VERSION ""

NS_ :

BS_:

BU_: ADCS_FD3 GW_FD2 BDCS CDCS GW_FD3 GW_FD4 GW_FD5 GW_FD6 GW_FD1 MCU FMCU EPS1 IDB1 ACU ICU TBOX IDB2 EPS2 RCU1 PDCU DDCU PLSD DLSD PDCS1 BTM GW_FD8 HNS2 HNS1 EMS BMS EDU RCU2

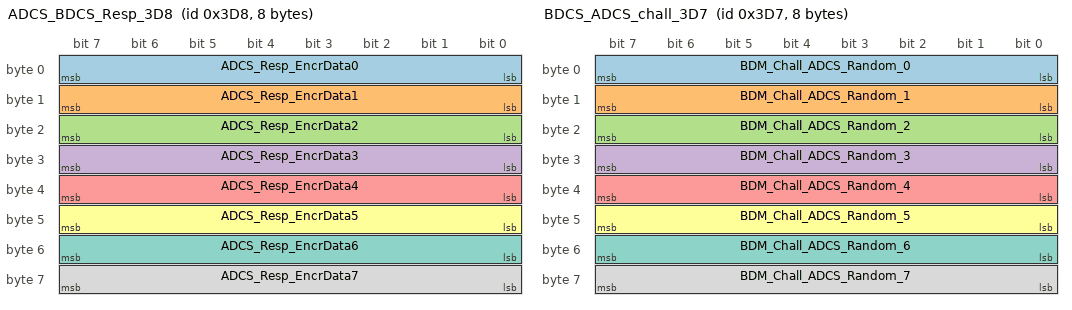
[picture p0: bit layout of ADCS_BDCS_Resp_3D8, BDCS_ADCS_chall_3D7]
BO_ 984 ADCS_BDCS_Resp_3D8: 8 ADCS_FD3
 SG_ ADCS_Resp_EncrData0 : 7|8@0+ (1,0) [0|255] "NoUnit" GW_FD2,BDCS
 SG_ ADCS_Resp_EncrData1 : 15|8@0+ (1,0) [0|255] "NoUnit" GW_FD2,BDCS
 SG_ ADCS_Resp_EncrData2 : 23|8@0+ (1,0) [0|255] "NoUnit" GW_FD2,BDCS
 SG_ ADCS_Resp_EncrData3 : 31|8@0+ (1,0) [0|255] "NoUnit" GW_FD2,BDCS
 SG_ ADCS_Resp_EncrData4 : 39|8@0+ (1,0) [0|255] "NoUnit" GW_FD2,BDCS
 SG_ ADCS_Resp_EncrData5 : 47|8@0+ (1,0) [0|255] "NoUnit" GW_FD2,BDCS
 SG_ ADCS_Resp_EncrData6 : 55|8@0+ (1,0) [0|255] "NoUnit" GW_FD2,BDCS
 SG_ ADCS_Resp_EncrData7 : 63|8@0+ (1,0) [0|255] "NoUnit" GW_FD2,BDCS

BO_ 983 BDCS_ADCS_chall_3D7: 8 BDCS
 SG_ BDM_Chall_ADCS_Random_0 : 7|8@0+ (1,0) [0|255] "NoUnit" ADCS_FD3
 SG_ BDM_Chall_ADCS_Random_1 : 15|8@0+ (1,0) [0|255] "NoUnit" ADCS_FD3
 SG_ BDM_Chall_ADCS_Random_2 : 23|8@0+ (1,0) [0|255] "NoUnit" ADCS_FD3
 SG_ BDM_Chall_ADCS_Random_3 : 31|8@0+ (1,0) [0|255] "NoUnit" ADCS_FD3
 SG_ BDM_Chall_ADCS_Random_4 : 39|8@0+ (1,0) [0|255] "NoUnit" ADCS_FD3
 SG_ BDM_Chall_ADCS_Random_5 : 47|8@0+ (1,0) [0|255] "NoUnit" ADCS_FD3
 SG_ BDM_Chall_ADCS_Random_6 : 55|8@0+ (1,0) [0|255] "NoUnit" ADCS_FD3
 SG_ BDM_Chall_ADCS_Random_7 : 63|8@0+ (1,0) [0|255] "NoUnit" ADCS_FD3

BO_ 515 CDCS_Fr15_203: 16 CDCS
 SG_ CDCS15_NNP_DriverStatus : 71|2@0+ (1,0) [0|3] "NoUnit" ADCS_FD3
 SG_ CDCS15_Storage_St : 72|1@0+ (1,0) [0|1] "NoUnit" ADCS_FD3
 SG_ CDCS15_USB_St : 73|1@0+ (1,0) [0|1] "NoUnit" ADCS_FD3
 SG_ CDCS15_UserSceneMode : 79|4@0+ (1,0) [0|15] "NoUnit" ADCS_FD3

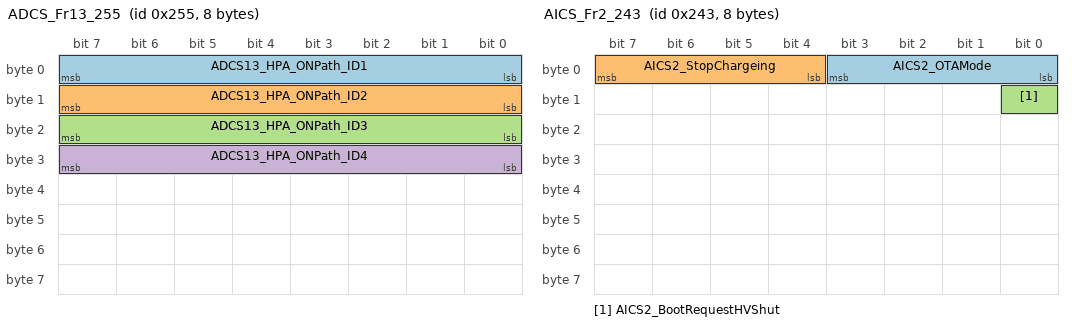
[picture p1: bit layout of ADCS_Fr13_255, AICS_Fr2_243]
BO_ 597 ADCS_Fr13_255: 8 ADCS_FD3
 SG_ ADCS13_HPA_ONPath_ID1 : 7|8@0+ (1,0) [0|255] "NoUnit" GW_FD3,GW_FD4,CDCS
 SG_ ADCS13_HPA_ONPath_ID2 : 15|8@0+ (1,0) [0|255] "NoUnit" GW_FD3,GW_FD4,CDCS
 SG_ ADCS13_HPA_ONPath_ID3 : 23|8@0+ (1,0) [0|255] "NoUnit" GW_FD3,GW_FD4,CDCS
 SG_ ADCS13_HPA_ONPath_ID4 : 31|8@0+ (1,0) [0|255] "NoUnit" GW_FD3,GW_FD4,CDCS

BO_ 579 AICS_Fr2_243: 8 GW_FD5
 SG_ AICS2_OTAMode : 3|4@0+ (1,0) [0|15] "NoUnit" ADCS_FD3
 SG_ AICS2_StopChargeing : 7|4@0+ (1,0) [0|15] "NoUnit" ADCS_FD3
 SG_ AICS2_BootRequestHVShut : 8|1@0+ (1,0) [0|1] "NoUnit" ADCS_FD3

BO_ 170 MCU_Fr01_0AA: 16 MCU
 SG_ MCU1_MotorSpeed : 23|16@0+ (0.5,-16000) [-16000|16000] "Rpm" ADCS_FD3
 SG_ MCU1_ControllerTorque : 39|16@0+ (0.05,-1024) [-1024|1024] "Nm" ADCS_FD3
 SG_ MCU1_AliveCounter : 51|4@0+ (1,0) [0|15] "NoUnit" ADCS_FD3
 SG_ MCU1_presentActivityFault : 71|8@0+ (1,0) [0|128] "NoUnit" ADCS_FD3
 SG_ MCU1_CurrentTorque : 78|15@0+ (0.05,-400) [-400|400] "Nm" ADCS_FD3
 SG_ MCU1_CurrentTorqueValid : 95|1@0+ (1,0) [0|1] "NoUnit" ADCS_FD3

BO_ 171 FMCU_Fr01_0AB: 16 FMCU
 SG_ FMCU1_MotorSpeed : 23|16@0+ (0.5,-16000) [-16000|16000] "Rpm" ADCS_FD3
 SG_ FMCU1_ControllerTorque : 39|16@0+ (0.05,-1024) [-1024|1024] "Nm" ADCS_FD3
 SG_ FMCU1_AliveCounter : 51|4@0+ (1,0) [0|15] "NoUnit" ADCS_FD3
 SG_ FMCU1_Checksum : 63|8@0+ (1,0) [0|255] "NoUnit" ADCS_FD3
 SG_ FMCU1_presentActivityFault : 71|8@0+ (1,0) [0|128] "NoUnit" ADCS_FD3
 SG_ FMCU1_CurrentTorque : 78|15@0+ (0.05,-400) [-400|400] "Nm" ADCS_FD3
 SG_ FMCU1_CurrentTorqueValid : 95|1@0+ (1,0) [0|1] "NoUnit" ADCS_FD3

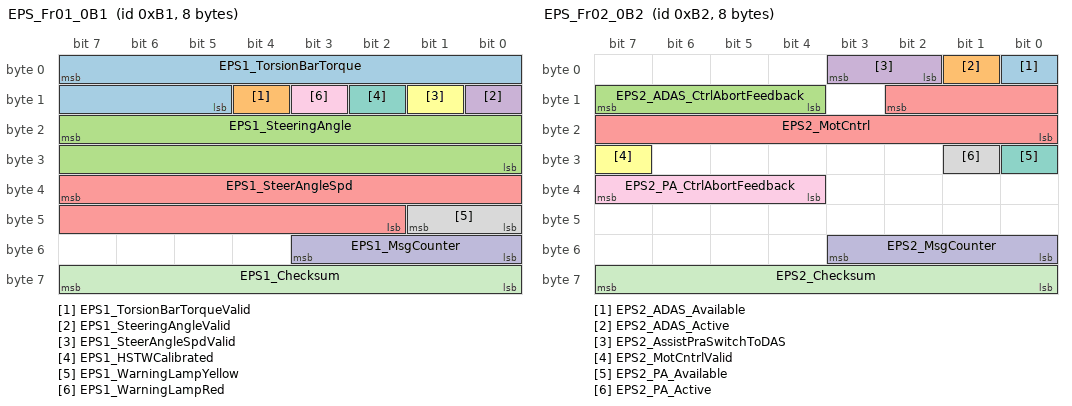
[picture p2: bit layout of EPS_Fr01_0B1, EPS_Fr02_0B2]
BO_ 177 EPS_Fr01_0B1: 8 EPS1
 SG_ EPS1_TorsionBarTorque : 7|11@0+ (0.01,-10.24) [-10.24|10.23] "Nm" ADCS_FD3
 SG_ EPS1_TorsionBarTorqueValid : 12|1@0+ (1,0) [0|1] "NoUnit" ADCS_FD3
 SG_ EPS1_SteeringAngle : 23|16@0+ (0.0345,-780) [-780|780.021] "degree" ADCS_FD3
 SG_ EPS1_SteeringAngleValid : 8|1@0+ (1,0) [0|1] "NoUnit" ADCS_FD3
 SG_ EPS1_SteerAngleSpd : 39|14@0+ (0.125,-1024) [-1024|1023.75] "deg/s" ADCS_FD3
 SG_ EPS1_SteerAngleSpdValid : 9|1@0+ (1,0) [0|1] "NoUnit" ADCS_FD3
 SG_ EPS1_HSTWCalibrated : 10|1@0+ (1,0) [0|1] "NoUnit" ADCS_FD3
 SG_ EPS1_WarningLampYellow : 41|2@0+ (1,0) [0|3] "NoUnit" ADCS_FD3
 SG_ EPS1_WarningLampRed : 11|1@0+ (1,0) [0|1] "NoUnit" ADCS_FD3
 SG_ EPS1_MsgCounter : 51|4@0+ (1,0) [0|15] "NoUnit" ADCS_FD3
 SG_ EPS1_Checksum : 63|8@0+ (1,0) [0|255] "NoUnit" ADCS_FD3

BO_ 178 EPS_Fr02_0B2: 8 EPS1
 SG_ EPS2_ADAS_Available : 0|1@0+ (1,0) [0|1] "NoUnit" ADCS_FD3
 SG_ EPS2_ADAS_Active : 1|1@0+ (1,0) [0|1] "NoUnit" ADCS_FD3
 SG_ EPS2_ADAS_CtrlAbortFeedback : 15|4@0+ (1,0) [0|15] "NoUnit" ADCS_FD3
 SG_ EPS2_AssistPraSwitchToDAS : 3|2@0+ (1,0) [0|3] "NoUnit" ADCS_FD3
 SG_ EPS2_MotCntrl : 10|11@0+ (0.01,-8) [-8|8] "Nm" ADCS_FD3
 SG_ EPS2_MotCntrlValid : 31|1@0+ (1,0) [0|1] "NoUnit" ADCS_FD3
 SG_ EPS2_PA_Available : 24|1@0+ (1,0) [0|1] "NoUnit" ADCS_FD3
 SG_ EPS2_PA_Active : 25|1@0+ (1,0) [0|1] "NoUnit" ADCS_FD3
 SG_ EPS2_PA_CtrlAbortFeedback : 39|4@0+ (1,0) [0|15] "NoUnit" ADCS_FD3
 SG_ EPS2_MsgCounter : 51|4@0+ (1,0) [0|15] "NoUnit" ADCS_FD3
 SG_ EPS2_Checksum : 63|8@0+ (1,0) [0|255] "NoUnit" ADCS_FD3

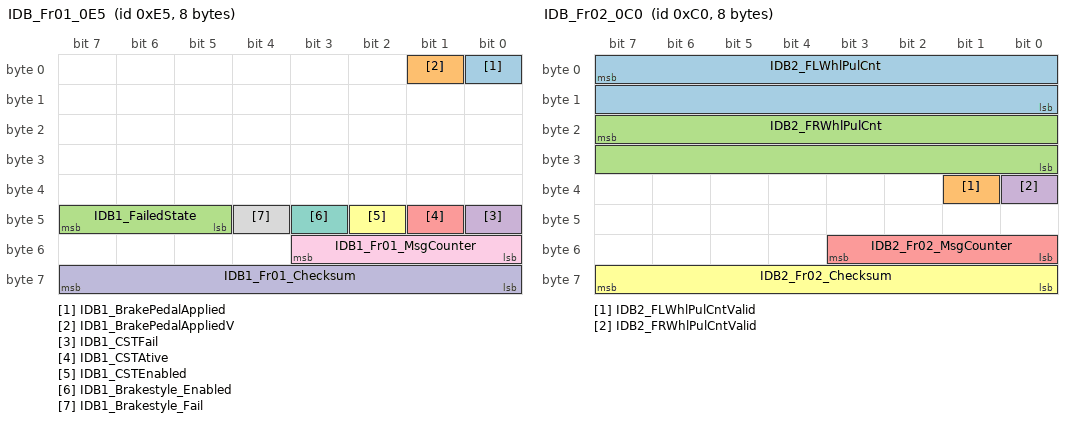
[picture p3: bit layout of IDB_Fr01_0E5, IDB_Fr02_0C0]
BO_ 229 IDB_Fr01_0E5: 8 IDB1
 SG_ IDB1_BrakePedalApplied : 0|1@0+ (1,0) [0|1] "NoUnit" ADCS_FD3
 SG_ IDB1_BrakePedalAppliedV : 1|1@0+ (1,0) [0|1] "NoUnit" ADCS_FD3
 SG_ IDB1_FailedState : 47|3@0+ (1,0) [0|7] "NoUnit" ADCS_FD3
 SG_ IDB1_CSTFail : 40|1@0+ (1,0) [0|1] "NoUnit" ADCS_FD3
 SG_ IDB1_CSTAtive : 41|1@0+ (1,0) [0|1] "NoUnit" ADCS_FD3
 SG_ IDB1_CSTEnabled : 42|1@0+ (1,0) [0|1] "NoUnit" ADCS_FD3
 SG_ IDB1_Brakestyle_Enabled : 43|1@0+ (1,0) [0|1] "NoUnit" ADCS_FD3
 SG_ IDB1_Brakestyle_Fail : 44|1@0+ (1,0) [0|1] "NoUnit" ADCS_FD3
 SG_ IDB1_Fr01_MsgCounter : 51|4@0+ (1,0) [0|15] "NoUnit" ADCS_FD3
 SG_ IDB1_Fr01_Checksum : 63|8@0+ (1,0) [0|255] "NoUnit" ADCS_FD3

BO_ 192 IDB_Fr02_0C0: 8 IDB1
 SG_ IDB2_FLWhlPulCnt : 7|16@0+ (0.5,0) [0|32767] "NoUnit" ADCS_FD3
 SG_ IDB2_FLWhlPulCntValid : 33|1@0+ (1,0) [0|1] "NoUnit" ADCS_FD3
 SG_ IDB2_FRWhlPulCnt : 23|16@0+ (0.5,0) [0|32767] "NoUnit" ADCS_FD3
 SG_ IDB2_FRWhlPulCntValid : 32|1@0+ (1,0) [0|1] "NoUnit" ADCS_FD3
 SG_ IDB2_Fr02_MsgCounter : 51|4@0+ (1,0) [0|15] "NoUnit" ADCS_FD3
 SG_ IDB2_Fr02_Checksum : 63|8@0+ (1,0) [0|255] "NoUnit" ADCS_FD3

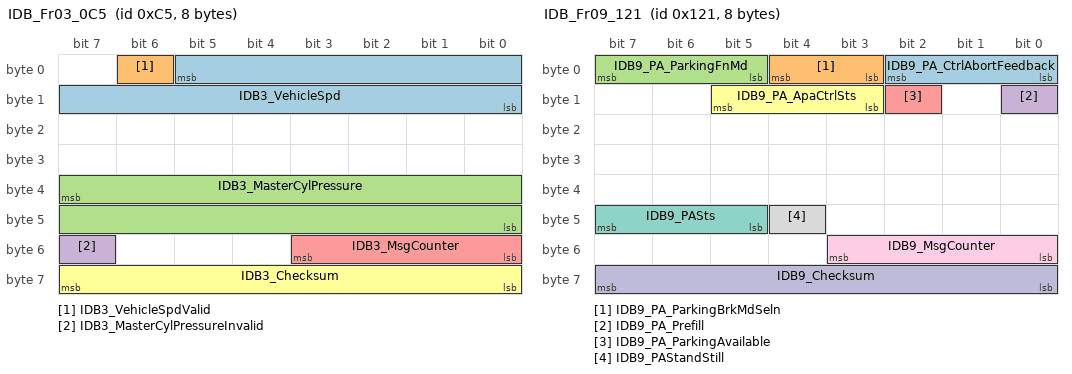
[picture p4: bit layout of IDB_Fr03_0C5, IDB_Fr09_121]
BO_ 197 IDB_Fr03_0C5: 8 IDB1
 SG_ IDB3_VehicleSpd : 5|14@0+ (0.03125,0) [0|511.9375] "km/h" ADCS_FD3
 SG_ IDB3_VehicleSpdValid : 6|1@0+ (1,0) [0|1] "NoUnit" ADCS_FD3
 SG_ IDB3_MasterCylPressure : 39|16@0+ (0.01,-30) [0|280] "bar" ADCS_FD3
 SG_ IDB3_MasterCylPressureInvalid : 55|1@0+ (1,0) [0|1] "NoUnit" ADCS_FD3
 SG_ IDB3_MsgCounter : 51|4@0+ (1,0) [0|15] "NoUnit" ADCS_FD3
 SG_ IDB3_Checksum : 63|8@0+ (1,0) [0|255] "NoUnit" ADCS_FD3

BO_ 199 IDB_Fr04_0C7: 32 IDB1
 SG_ IDB4_FLWhlVelocity : 7|14@0+ (0.03125,0) [0|511.9375] "km/h" ADCS_FD3
 SG_ IDB4_FLWhlVelocityValid : 9|1@0+ (1,0) [0|1] "NoUnit" ADCS_FD3
 SG_ IDB4_FRWhlVelocity : 23|14@0+ (0.03125,0) [0|511.9375] "km/h" ADCS_FD3
 SG_ IDB4_FRWhlVelocityValid : 25|1@0+ (1,0) [0|1] "NoUnit" ADCS_FD3
 SG_ IDB4_FRWhlDir : 37|2@0+ (1,0) [0|3] "NoUnit" ADCS_FD3
 SG_ IDB4_FLWhlDir : 39|2@0+ (1,0) [0|3] "NoUnit" ADCS_FD3
 SG_ IDB4_RLWhlDir : 35|2@0+ (1,0) [0|3] "NoUnit" ADCS_FD3
 SG_ IDB4_RRWhlDir : 33|2@0+ (1,0) [0|3] "NoUnit" ADCS_FD3
 SG_ IDB4_MsgCounter : 51|4@0+ (1,0) [0|15] "NoUnit" ADCS_FD3
 SG_ IDB4_Checksum : 63|8@0+ (1,0) [0|255] "NoUnit" ADCS_FD3
 SG_ IDB4_RLWhlVelocity : 71|14@0+ (0.03125,0) [0|511.9375] "km/h" ADCS_FD3
 SG_ IDB4_RLWhlVelocityValid : 73|1@0+ (1,0) [0|1] "NoUnit" ADCS_FD3
 SG_ IDB4_RRWhlVelocity : 87|14@0+ (0.03125,0) [0|511.9375] "km/h" ADCS_FD3
 SG_ IDB4_RRWhlVelocityValid : 72|1@0+ (1,0) [0|1] "NoUnit" ADCS_FD3
 SG_ IDB4_RLWhlPulCnt : 103|16@0+ (0.5,0) [0|32767] "NoUnit" ADCS_FD3
 SG_ IDB4_RRWhlPulCnt : 119|16@0+ (0.5,0) [0|32767] "NoUnit" ADCS_FD3
 SG_ IDB4_RLWhlPulCntValid : 88|1@0+ (1,0) [0|1] "NoUnit" ADCS_FD3
 SG_ IDB4_RRWhlPulCntValid : 89|1@0+ (1,0) [0|1] "NoUnit" ADCS_FD3

BO_ 289 IDB_Fr09_121: 8 IDB1
 SG_ IDB9_PA_CtrlAbortFeedback : 2|3@0+ (1,0) [0|7] "NoUnit" ADCS_FD3
 SG_ IDB9_PA_ParkingBrkMdSeln : 4|2@0+ (1,0) [0|3] "NoUnit" ADCS_FD3
 SG_ IDB9_PA_ParkingFnMd : 7|3@0+ (1,0) [0|7] "NoUnit" ADCS_FD3
 SG_ IDB9_PA_Prefill : 8|1@0+ (1,0) [0|1] "NoUnit" ADCS_FD3
 SG_ IDB9_PA_ParkingAvailable : 10|1@0+ (1,0) [0|1] "NoUnit" ADCS_FD3
 SG_ IDB9_PA_ApaCtrlSts : 13|3@0+ (1,0) [0|7] "NoUnit" ADCS_FD3
 SG_ IDB9_PASts : 47|3@0+ (1,0) [0|7] "NoUnit" ADCS_FD3
 SG_ IDB9_PAStandStill : 44|1@0+ (1,0) [0|1] "NoUnit" ADCS_FD3
 SG_ IDB9_MsgCounter : 51|4@0+ (1,0) [0|15] "NoUnit" ADCS_FD3
 SG_ IDB9_Checksum : 63|8@0+ (1,0) [0|255] "NoUnit" ADCS_FD3

BO_ 297 IDB_Fr05_129: 8 IDB1
 SG_ IDB5_BrakeDiscTempSts : 0|1@0+ (1,0) [0|1] "NoUnit" ADCS_FD3
 SG_ IDB5_VehicleStanstill : 2|2@0+ (1,0) [0|3] "NoUnit" ADCS_FD3
 SG_ IDB5_JerkActive : 3|1@0+ (1,0) [0|1] "NoUnit" ADCS_FD3
 SG_ IDB5_Jerkfail : 4|1@0+ (1,0) [0|1] "NoUnit" ADCS_FD3
 SG_ IDB5_ADAS_PrefillSts : 6|2@0+ (1,0) [0|3] "" ADCS_FD3
 SG_ IDB5_ACC_ReqLim : 25|2@0+ (1,0) [0|3] "NoUnit" ADCS_FD3
 SG_ IDB5_DBSavailable : 26|1@0+ (1,0) [0|1] "NoUnit" ADCS_FD3
 SG_ IDB5_Prefillavailable : 27|1@0+ (1,0) [0|1] "NoUnit" ADCS_FD3
 SG_ IDB5_ABAactive : 28|1@0+ (1,0) [0|1] "NoUnit" ADCS_FD3
 SG_ IDB5_ACC_ReferenceAccel : 39|11@0+ (0.01,-10.23) [-10.23|10.24] "m/s" ADCS_FD3
 SG_ IDB5_ACC_Enable : 43|2@0+ (1,0) [0|3] "NoUnit" ADCS_FD3
 SG_ IDB5_ACC_Sta : 44|1@0+ (1,0) [0|1] "NoUnit" ADCS_FD3
 SG_ IDB5_AEB_Enable : 41|2@0+ (1,0) [0|3] "NoUnit" ADCS_FD3
 SG_ IDB5_AEBactive : 52|1@0+ (1,0) [0|1] "NoUnit" ADCS_FD3
 SG_ IDB5_DriverOverride : 54|2@0+ (1,0) [0|3] "NoUnit" ADCS_FD3
 SG_ IDB5_MsgCounter : 51|4@0+ (1,0) [0|15] "NoUnit" ADCS_FD3
 SG_ IDB5_Checksum : 63|8@0+ (1,0) [0|255] "NoUnit" ADCS_FD3

BO_ 299 IDB_Fr06_12B: 8 IDB1
 SG_ IDB6_EPBAvailable : 37|3@0+ (1,0) [0|7] "NoUnit" ADCS_FD3
 SG_ IDB6_EPBStatus : 34|3@0+ (1,0) [0|7] "NoUnit" ADCS_FD3

BO_ 301 IDB_Fr07_12D: 16 IDB1
 SG_ IDB7_EBD_Fail : 4|1@0+ (1,0) [0|1] "NoUnit" ADCS_FD3
 SG_ IDB7_EBD_Active : 5|1@0+ (1,0) [0|1] "NoUnit" ADCS_FD3
 SG_ IDB7_HBAActive : 6|1@0+ (1,0) [0|1] "NoUnit" ADCS_FD3
 SG_ IDB7_HBAFail : 7|1@0+ (1,0) [0|1] "NoUnit" ADCS_FD3
 SG_ IDB7_DiagMode : 8|1@0+ (1,0) [0|1] "NoUnit" ADCS_FD3
 SG_ IDB7_TCSActive : 9|1@0+ (1,0) [0|1] "NoUnit" ADCS_FD3
 SG_ IDB7_TCSDisable : 10|1@0+ (1,0) [0|1] "NoUnit" ADCS_FD3
 SG_ IDB7_TCSFail : 11|1@0+ (1,0) [0|1] "NoUnit" ADCS_FD3
 SG_ IDB7_ROPACTIVE : 12|1@0+ (1,0) [0|1] "NoUnit" ADCS_FD3
 SG_ IDB7_ROPFailure : 13|1@0+ (1,0) [0|1] "NoUnit" ADCS_FD3
 SG_ IDB7_AVHDispMSG : 15|2@0+ (1,0) [0|3] "NoUnit" ADCS_FD3
 SG_ IDB7_AVHLampReq : 17|2@0+ (1,0) [0|3] "NoUnit" ADCS_FD3
 SG_ IDB7_AVHStatus : 19|2@0+ (1,0) [0|3] "NoUnit" ADCS_FD3
 SG_ IDB7_AVHEnabled : 20|1@0+ (1,0) [0|1] "NoUnit" ADCS_FD3
 SG_ IDB7_DynParkBrkByIDBActive : 21|1@0+ (1,0) [0|1] "NoUnit" ADCS_FD3
 SG_ IDB7_DynParkBrkByIDBAvailable : 22|1@0+ (1,0) [0|1] "NoUnit" ADCS_FD3
 SG_ IDB7_HSAActive : 23|1@0+ (1,0) [0|1] "NoUnit" ADCS_FD3
 SG_ IDB7_HSAFail : 24|1@0+ (1,0) [0|1] "NoUnit" ADCS_FD3
 SG_ IDB7_HDCEnabled : 25|1@0+ (1,0) [0|1] "NoUnit" ADCS_FD3
 SG_ IDB7_HDCFail : 26|1@0+ (1,0) [0|1] "NoUnit" ADCS_FD3
 SG_ IDB7_HDCAtive : 27|1@0+ (1,0) [0|1] "NoUnit" ADCS_FD3
 SG_ IDB7_ABSActive : 3|1@0+ (1,0) [0|1] "NoUnit" ADCS_FD3
 SG_ IDB7_ABSFail : 29|1@0+ (1,0) [0|1] "NoUnit" ADCS_FD3
 SG_ IDB7_ESCFail : 0|1@0+ (1,0) [0|1] "NoUnit" ADCS_FD3
 SG_ IDB7_ESCActive : 1|1@0+ (1,0) [0|1] "NoUnit" ADCS_FD3
 SG_ IDB7_ESCDisable : 2|1@0+ (1,0) [0|1] "NoUnit" ADCS_FD3

BO_ 201 IDB_Fr10_0C9: 16 IDB1
 SG_ IDB10_MotrTrqFrntAxleTargtReq : 54|1@0+ (1,0) [0|1] "NoUnit" ADCS_FD3
 SG_ IDB10_MotrTrqRearAxleTargtReq : 55|1@0+ (1,0) [0|1] "NoUnit" ADCS_FD3
 SG_ IDB10_MotrTrqFrntAxleTargt : 71|16@0+ (0.5,-16000) [-16000|16000] "Nm" ADCS_FD3
 SG_ IDB10_MotrTrqRearAxleTargt : 87|16@0+ (0.5,-16000) [-16000|16000] "Nm" ADCS_FD3
 SG_ IDB10_ADAS_DrvTorque : 103|16@0+ (0.5,-16000) [-16000|16000] "Nm" ADCS_FD3
 SG_ IDB10_ADAS_DrvTorqueReq : 40|1@0+ (1,0) [0|1] "NoUnit" ADCS_FD3

BO_ 272 BDCS_Fr01_110: 8 BDCS
 SG_ BDCS1_PowerMode : 1|2@0+ (1,0) [0|3] "NoUnit" ADCS_FD3
 SG_ BDCS1_PowerManageMode : 7|4@0+ (1,0) [0|15] "NoUnit" ADCS_FD3
 SG_ BDCS1_LowBeamSt : 11|1@0+ (1,0) [0|1] "NoUnit" ADCS_FD3
 SG_ BDCS1_HighBeamSt : 12|1@0+ (1,0) [0|1] "NoUnit" ADCS_FD3
 SG_ BDCS1_PositionLightSts : 17|1@0+ (1,0) [0|1] "NoUnit" ADCS_FD3
 SG_ BDCS1_BacklightStatus : 18|1@0+ (1,0) [0|1] "NoUnit" ADCS_FD3
 SG_ BDCS1_LeftTurnLightSt : 19|1@0+ (1,0) [0|1] "NoUnit" ADCS_FD3
 SG_ BDCS1_RightTurnLightSt : 20|1@0+ (1,0) [0|1] "NoUnit" ADCS_FD3
 SG_ BDCS1_FrontLampSt : 22|2@0+ (1,0) [0|3] "NoUnit" ADCS_FD3
 SG_ BDCS1_HazardLampSt : 23|1@0+ (1,0) [0|1] "NoUnit" ADCS_FD3
 SG_ BDCS1_HighBeamSW : 25|2@0+ (1,0) [0|3] "NoUnit" ADCS_FD3
 SG_ BDCS1_TurnLightSW : 27|2@0+ (1,0) [0|3] "NoUnit" ADCS_FD3
 SG_ BDCS1_HazardSwSt : 28|1@0+ (1,0) [0|1] "NoUnit" ADCS_FD3
 SG_ BDCS1_RearFogLampSt : 30|1@0+ (1,0) [0|1] "NoUnit" ADCS_FD3
 SG_ BDCS1_FrontFogLampSt : 31|1@0+ (1,0) [0|1] "NoUnit" ADCS_FD3
 SG_ BDCS1_TrunkLockSts : 35|1@0+ (1,0) [0|1] "NoUnit" ADCS_FD3
 SG_ BDCS1_HoodAjarSts : 39|1@0+ (1,0) [0|1] "NoUnit" ADCS_FD3
 SG_ BDCS1_MsgCounter : 51|4@0+ (1,0) [0|15] "NoUnit" ADCS_FD3
 SG_ BDCS1_Checksum : 63|8@0+ (1,0) [0|255] "NoUnit" ADCS_FD3

BO_ 274 BDCS_Fr03_112: 16 BDCS
 SG_ BDCS3_RemoteAuthenSts : 11|2@0+ (1,0) [0|3] "NoUnit" ADCS_FD3
 SG_ BDCS3_BackDoorAjar : 27|3@0+ (1,0) [0|7] "NoUnit" ADCS_FD3
 SG_ BDCS3_ADCSAuthenSts : 63|2@0+ (1,0) [0|3] "NoUnit" ADCS_FD3

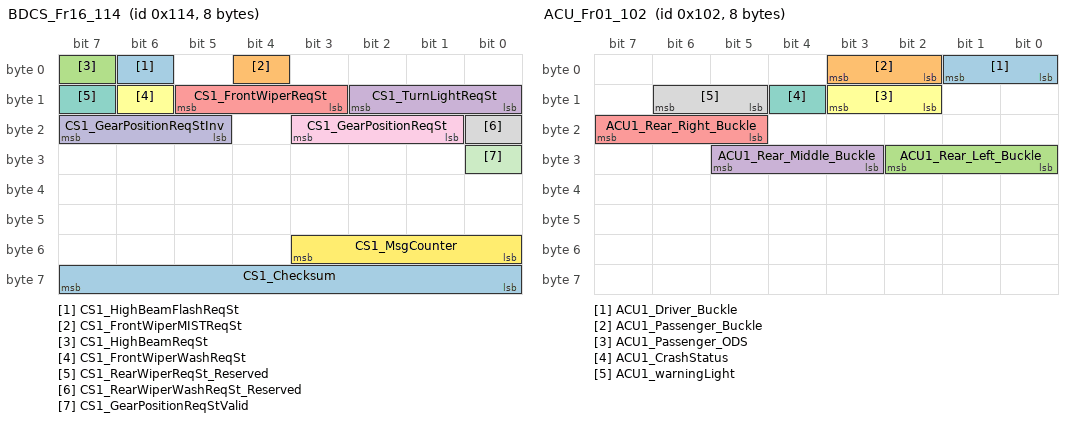
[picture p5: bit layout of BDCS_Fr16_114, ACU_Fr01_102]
BO_ 276 BDCS_Fr16_114: 8 BDCS
 SG_ CS1_HighBeamFlashReqSt : 6|1@0+ (1,0) [0|1] "NoUnit" ADCS_FD3
 SG_ CS1_FrontWiperMISTReqSt : 4|1@0+ (1,0) [0|1] "NoUnit" ADCS_FD3
 SG_ CS1_HighBeamReqSt : 7|1@0+ (1,0) [0|1] "NoUnit" ADCS_FD3
 SG_ CS1_TurnLightReqSt : 10|3@0+ (1,0) [0|7] "NoUnit" ADCS_FD3
 SG_ CS1_FrontWiperReqSt : 13|3@0+ (1,0) [0|7] "NoUnit" ADCS_FD3
 SG_ CS1_FrontWiperWashReqSt : 14|1@0+ (1,0) [0|1] "NoUnit" ADCS_FD3
 SG_ CS1_RearWiperReqSt_Reserved : 15|1@0+ (1,0) [0|1] "NoUnit" ADCS_FD3
 SG_ CS1_RearWiperWashReqSt_Reserved : 16|1@0+ (1,0) [0|1] "NoUnit" ADCS_FD3
 SG_ CS1_GearPositionReqSt : 19|3@0+ (1,0) [0|7] "NoUnit" ADCS_FD3
 SG_ CS1_GearPositionReqStInv : 23|3@0+ (1,0) [0|7] "NoUnit" ADCS_FD3
 SG_ CS1_GearPositionReqStValid : 24|1@0+ (1,0) [0|1] "NoUnit" ADCS_FD3
 SG_ CS1_MsgCounter : 51|4@0+ (1,0) [0|15] "NoUnit" ADCS_FD3
 SG_ CS1_Checksum : 63|8@0+ (1,0) [0|255] "NoUnit" ADCS_FD3

BO_ 258 ACU_Fr01_102: 8 ACU
 SG_ ACU1_Driver_Buckle : 1|2@0+ (1,0) [0|3] "NoUnit" ADCS_FD3
 SG_ ACU1_Passenger_Buckle : 3|2@0+ (1,0) [0|3] "NoUnit" ADCS_FD3
 SG_ ACU1_Rear_Left_Buckle : 26|3@0+ (1,0) [0|7] "NoUnit" ADCS_FD3
 SG_ ACU1_Rear_Middle_Buckle : 29|3@0+ (1,0) [0|7] "NoUnit" ADCS_FD3
 SG_ ACU1_Rear_Right_Buckle : 23|3@0+ (1,0) [0|7] "NoUnit" ADCS_FD3
 SG_ ACU1_Passenger_ODS : 11|2@0+ (1,0) [0|3] "NoUnit" ADCS_FD3
 SG_ ACU1_CrashStatus : 12|1@0+ (1,0) [0|1] "NoUnit" ADCS_FD3
 SG_ ACU1_warningLight : 14|2@0+ (1,0) [0|3] "NoUnit" ADCS_FD3

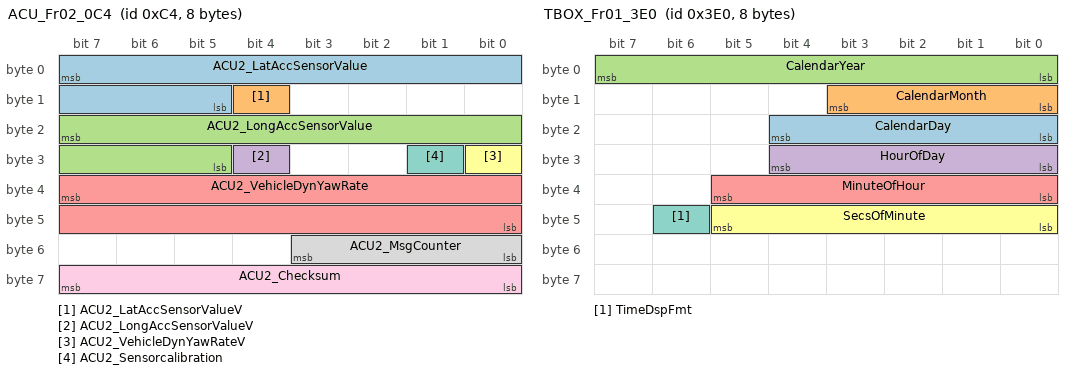
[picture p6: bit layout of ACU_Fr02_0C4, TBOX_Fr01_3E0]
BO_ 196 ACU_Fr02_0C4: 8 ACU
 SG_ ACU2_LatAccSensorValue : 7|11@0+ (0.02,-16) [-16|16] "m/s^2" ADCS_FD3
 SG_ ACU2_LatAccSensorValueV : 12|1@0+ (1,0) [0|1] "NoUnit" ADCS_FD3
 SG_ ACU2_LongAccSensorValue : 23|11@0+ (0.02,-16) [-16|16] "m/s^2" ADCS_FD3
 SG_ ACU2_LongAccSensorValueV : 28|1@0+ (1,0) [0|1] "NoUnit" ADCS_FD3
 SG_ ACU2_VehicleDynYawRate : 39|16@0+ (0.01,-180) [-180|180] "deg/s" ADCS_FD3
 SG_ ACU2_VehicleDynYawRateV : 24|1@0+ (1,0) [0|1] "NoUnit" ADCS_FD3
 SG_ ACU2_Sensorcalibration : 25|1@0+ (1,0) [0|1] "NoUnit" ADCS_FD3
 SG_ ACU2_MsgCounter : 51|4@0+ (1,0) [0|15] "NoUnit" ADCS_FD3
 SG_ ACU2_Checksum : 63|8@0+ (1,0) [0|255] "NoUnit" ADCS_FD3

BO_ 805 ICU_Fr02_325: 8 ICU
 SG_ ICU2_Odometer : 7|24@0+ (0.1,0) [0|1677721.4] "km" ADCS_FD3

BO_ 305 ICU_Fr01_131: 8 ICU
 SG_ ICU1_VehicleSpdDisplayValid : 8|1@0+ (1,0) [0|1] "NoUnit" ADCS_FD3
 SG_ ICU1_VehicleSpdDisplay : 7|10@0+ (0.5,0) [0|511] "NoUnit" ADCS_FD3

BO_ 992 TBOX_Fr01_3E0: 8 TBOX
 SG_ CalendarDay : 20|5@0+ (1,0) [0|31] "NoUnit" ADCS_FD3
 SG_ CalendarMonth : 11|4@0+ (1,0) [0|15] "NoUnit" ADCS_FD3
 SG_ CalendarYear : 7|8@0+ (1,2000) [2000|2255] "NoUnit" ADCS_FD3
 SG_ HourOfDay : 28|5@0+ (1,0) [0|23] "NoUnit" ADCS_FD3
 SG_ MinuteOfHour : 37|6@0+ (1,0) [0|59] "NoUnit" ADCS_FD3
 SG_ SecsOfMinute : 45|6@0+ (1,0) [0|59] "NoUnit" ADCS_FD3
 SG_ TimeDspFmt : 46|1@0+ (1,0) [0|1] "NoUnit" ADCS_FD3

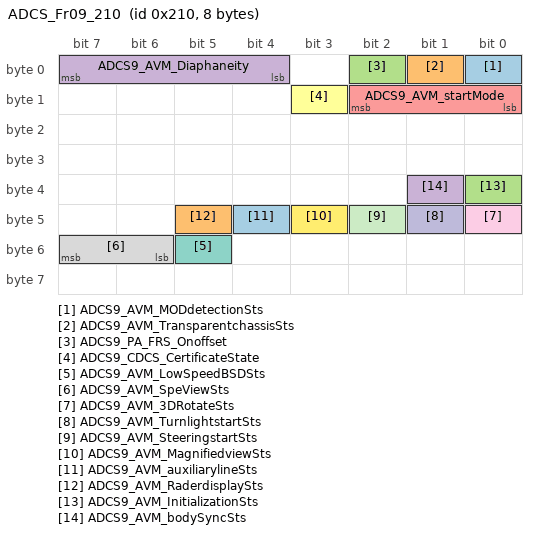
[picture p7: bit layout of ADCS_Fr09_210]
BO_ 528 ADCS_Fr09_210: 8 ADCS_FD3
 SG_ ADCS9_AVM_MODdetectionSts : 0|1@0+ (1,0) [0|1] "NoUnit" GW_FD4,ICU,CDCS
 SG_ ADCS9_AVM_TransparentchassisSts : 1|1@0+ (1,0) [0|1] "NoUnit" GW_FD4,ICU,CDCS
 SG_ ADCS9_PA_FRS_Onoffset : 2|1@0+ (1,0) [0|1] "NoUnit" GW_FD4,CDCS
 SG_ ADCS9_AVM_Diaphaneity : 7|4@0+ (1,0) [0|15] "NoUnit" GW_FD4,ICU,CDCS
 SG_ ADCS9_AVM_startMode : 10|3@0+ (1,0) [0|7] "NoUnit" GW_FD4,CDCS
 SG_ ADCS9_CDCS_CertificateState : 11|1@0+ (1,0) [0|1] "NoUnit" GW_FD4,CDCS
 SG_ ADCS9_AVM_LowSpeedBSDSts : 53|1@0+ (1,0) [0|1] "NoUnit" GW_FD4,CDCS
 SG_ ADCS9_AVM_SpeViewSts : 55|2@0+ (1,0) [0|3] "NoUnit" GW_FD4,CDCS
 SG_ ADCS9_AVM_3DRotateSts : 40|1@0+ (1,0) [0|1] "NoUnit" GW_FD4,CDCS
 SG_ ADCS9_AVM_TurnlightstartSts : 41|1@0+ (1,0) [0|1] "NoUnit" GW_FD4,CDCS
 SG_ ADCS9_AVM_SteeringstartSts : 42|1@0+ (1,0) [0|1] "NoUnit" GW_FD4,CDCS
 SG_ ADCS9_AVM_MagnifiedviewSts : 43|1@0+ (1,0) [0|1] "NoUnit" GW_FD4,CDCS
 SG_ ADCS9_AVM_auxiliarylineSts : 44|1@0+ (1,0) [0|1] "NoUnit" GW_FD4,CDCS
 SG_ ADCS9_AVM_RaderdisplaySts : 45|1@0+ (1,0) [0|1] "NoUnit" GW_FD4,CDCS
 SG_ ADCS9_AVM_InitializationSts : 32|1@0+ (1,0) [0|1] "NoUnit" GW_FD4,CDCS
 SG_ ADCS9_AVM_bodySyncSts : 33|1@0+ (1,0) [0|1] "NoUnit" GW_FD4,CDCS

BO_ 403 ADCS_Fr08_193: 64 ADCS_FD3
 SG_ ADCS8_LDWMode : 6|1@0+ (1,0) [0|1] "NoUnit" GW_FD4,CDCS
 SG_ ADCS8_LDWWarnState : 5|3@0+ (1,0) [0|7] "NoUnit" GW_FD4,ICU,CDCS
 SG_ ADCS8_LDWState : 2|3@0+ (1,0) [0|7] "NoUnit" GW_FD4,ICU,CDCS
 SG_ ADCS8_ELKMode : 7|1@0+ (1,0) [0|1] "NoUnit" GW_FD4,ICU,CDCS
 SG_ ADCS8_LDPELKWarnState : 9|2@0+ (1,0) [0|3] "NoUnit" GW_FD4,CDCS
 SG_ ADCS8_MissingExitAlert : 15|3@0+ (1,0) [0|7] "NoUnit" GW_FD4,CDCS
 SG_ ADCS8_LKSSetspeed : 23|8@0+ (1,0) [0|255] "km/h" GW_FD4,ICU,CDCS
 SG_ ADCS8_LDPMode : 29|1@0+ (1,0) [0|1] "NoUnit" GW_FD4,ICU,CDCS
 SG_ ADCS8_lateralCtrHandsEyesOffWarning : 12|3@0+ (1,0) [0|7] "NoUnit" GW_FD4,ICU,CDCS
 SG_ ADCS8_LDPELKtakeoverWarningstate : 31|2@0+ (1,0) [0|3] "NoUnit" GW_FD4,CDCS
 SG_ ADAS8_LateralCtrHandOffReleasewarning : 28|1@0+ (1,0) [0|1] "NoUnit" GW_FD4,ICU,CDCS
 SG_ ADCS8_lateralCtrtakeover : 27|1@0+ (1,0) [0|1] "NoUnit" GW_FD4,ICU,CDCS
 SG_ ADCS8_ACCState : 26|3@0+ (1,0) [0|7] "NoUnit" ACU,IDB1,GW_FD4,IDB2,EPS2,GW_FD1,ICU,RCU1,CDCS
 SG_ ADCS8_longitudCtrlTakeOverReq : 44|1@0+ (1,0) [0|1] "NoUnit" IDB1,GW_FD4,IDB2,EPS2,ICU,RCU1,CDCS
 SG_ ADCS8_longitudCtrlSetSpeed : 39|8@0+ (1,0) [0|255] "km/h" GW_FD4,ICU,CDCS
 SG_ ADCS8_NNP_Scenarios : 43|4@0+ (1,0) [0|15] "NoUnit" GW_FD4,CDCS
 SG_ ADCS8_longitudCtrlSetDistance : 47|3@0+ (1,0) [0|7] "NoUnit" GW_FD4,ICU,CDCS
 SG_ ADCS8_longitudCtrlTargetValidity : 48|1@0+ (1,0) [0|1] "NoUnit" GW_FD4,ICU,CDCS
 SG_ ADCS8_ACCSystemFaultStatus : 50|2@0+ (1,0) [0|3] "NoUnit" ACU,IDB1,GW_FD4,IDB2,EPS2,GW_FD1,ICU,RCU1,CDCS
 SG_ ADCS8_AEB_SystemFaultStatus : 53|3@0+ (1,0) [0|7] "NoUnit" ACU,IDB1,GW_FD4,IDB2,EPS2,GW_FD1,ICU,RCU1,CDCS
 SG_ ADCS8_AEB_SystemStatus : 55|2@0+ (1,0) [0|3] "NoUnit" ACU,IDB1,GW_FD4,IDB2,EPS2,GW_FD1,ICU,RCU1,CDCS
 SG_ ADCS8_FCW_State : 63|2@0+ (1,0) [0|3] "NoUnit" GW_FD4,ICU,CDCS
 SG_ ADCS8_FCWSensitiveLevel : 61|2@0+ (1,0) [0|3] "NoUnit" GW_FD4,ICU,CDCS
 SG_ ADCS8_FCWStatus : 59|2@0+ (1,0) [0|3] "NoUnit" ACU,GW_FD4,GW_FD1,ICU,CDCS
 SG_ ADCS8_FCWSystemFaultStatus : 57|2@0+ (1,0) [0|3] "NoUnit" GW_FD4,ICU,CDCS
 SG_ ADCS8_FCTA_State : 65|2@0+ (1,0) [0|3] "NoUnit" GW_FD4,ICU,CDCS
 SG_ ADCS8_FCTALeftActiveSt : 79|2@0+ (1,0) [0|3] "NoUnit" PDCU,GW_FD4,ICU,GW_FD2,DDCU,CDCS
 SG_ ADCS8_FCTARightActiveSt : 77|2@0+ (1,0) [0|3] "NoUnit" PDCU,GW_FD4,ICU,GW_FD2,DDCU,CDCS
 SG_ ADCS8_FCTAWarnObjType : 75|2@0+ (1,0) [0|3] "NoUnit" PDCU,GW_FD4,ICU,GW_FD2,DDCU,CDCS
 SG_ ADCS8_FCTA_SystemFaultStatus : 73|2@0+ (1,0) [0|3] "NoUnit" PDCU,GW_FD4,ICU,GW_FD2,DDCU,CDCS
 SG_ ADCS8_RCTA_State : 87|2@0+ (1,0) [0|3] "NoUnit" PDCU,GW_FD4,ICU,GW_FD2,DDCU,CDCS
 SG_ ADCS8_RCTALeftWarnSt : 85|2@0+ (1,0) [0|3] "NoUnit" PDCU,GW_FD4,ICU,GW_FD2,DDCU,CDCS
 SG_ ADCS8_RCTARightWarnSt : 83|2@0+ (1,0) [0|3] "NoUnit" PDCU,GW_FD4,ICU,GW_FD2,DDCU,CDCS
 SG_ ADCS8_RCTA_SystemFaultStatus : 81|2@0+ (1,0) [0|3] "NoUnit" PDCU,GW_FD4,ICU,GW_FD2,DDCU,CDCS
 SG_ ADCS8_RCW_State : 95|2@0+ (1,0) [0|3] "NoUnit" PDCU,GW_FD4,ICU,GW_FD2,DDCU,CDCS
 SG_ ADCS8_RCW_WarnState : 93|2@0+ (1,0) [0|3] "NoUnit" ACU,PDCU,GW_FD4,GW_FD1,ICU,GW_FD2,DDCU,CDCS
 SG_ ADCS8_RCW_SystemFaultStatus : 91|2@0+ (1,0) [0|3] "NoUnit" PDCU,GW_FD4,ICU,GW_FD2,DDCU,CDCS
 SG_ ADCS8_DOWState : 89|2@0+ (1,0) [0|3] "NoUnit" PDCU,PLSD,DLSD,GW_FD4,ICU,GW_FD2,DDCU,CDCS
 SG_ ADCS8_DOWLeftWarnState : 103|2@0+ (1,0) [0|3] "NoUnit" PDCU,DLSD,GW_FD4,ICU,GW_FD2,BDCS,DDCU,CDCS
 SG_ ADCS8_DOWRightWarnState : 101|2@0+ (1,0) [0|3] "NoUnit" PDCU,PLSD,GW_FD4,ICU,GW_FD2,BDCS,DDCU,CDCS
 SG_ ADCS8_DOW_SystemFaultStatus : 99|2@0+ (1,0) [0|3] "NoUnit" GW_FD4,ICU,CDCS
 SG_ ADCS8_ADAS_IHBCStat : 97|2@0+ (1,0) [0|3] "NoUnit" GW_FD4,ICU,CDCS
 SG_ ADCS8_LCAState : 105|2@0+ (1,0) [0|3] "NoUnit" GW_FD4,ICU,CDCS
 SG_ ADCS8_HornReq : 106|1@0+ (1,0) [0|1] "NoUnit" GW_FD2,BDCS
 SG_ ADCS8_DoorUnlock : 107|1@0+ (1,0) [0|1] "" PDCU,GW_FD2,BDCS,DDCU
 SG_ ADCS8_LCARightWarnSt : 119|2@0+ (1,0) [0|3] "NoUnit" PDCU,GW_FD4,ICU,GW_FD2,DDCU,CDCS
 SG_ ADCS8_LCALeftWarnSt : 117|2@0+ (1,0) [0|3] "NoUnit" PDCU,GW_FD4,ICU,GW_FD2,DDCU,CDCS
 SG_ ADCS8_ACCOnOffState : 126|1@0+ (1,0) [0|1] "NoUnit" GW_FD4,CDCS
 SG_ ADCS8_LCASystemFaultStatus : 135|2@0+ (1,0) [0|3] "NoUnit" PDCU,GW_FD4,ICU,GW_FD2,DDCU,CDCS
 SG_ ADCS8_TSRState : 133|2@0+ (1,0) [0|3] "NoUnit" GW_FD4,ICU,CDCS
 SG_ ADCS8_TSR_SpeedSign : 131|4@0+ (1,0) [0|15] "NoUnit" GW_FD4,ICU,CDCS
 SG_ ADCS8_TSR_SpeedWarnState : 143|1@0+ (1,0) [0|1] "NoUnit" GW_FD4,ICU,CDCS
 SG_ ADCS8_TSR_SLFStatefeedback : 142|2@0+ (1,0) [0|3] "NoUnit" GW_FD4,ICU,CDCS
 SG_ ADCS8_NNP_SOAAudioplay : 140|1@0+ (1,0) [0|1] "NoUnit" GW_FD4,CDCS
 SG_ ADCS8_TSR_ForbiddenSign : 139|4@0+ (1,0) [0|15] "NoUnit" GW_FD4,ICU,CDCS
 SG_ ADCS8_PA_FPAS_SnsrObjWrnngZn_RSDW : 180|3@0+ (1,0) [0|7] "NoUnit" GW_FD4,CDCS
 SG_ ADCS8_PA_FPAS_SnsrObjWrnngZn_LSDW : 183|3@0+ (1,0) [0|7] "NoUnit" GW_FD4,CDCS
 SG_ ADCS8_PA_FPAS_SnsrObjWrnnglc_RSDW : 149|2@0+ (1,0) [0|3] "NoUnit" GW_FD4,CDCS
 SG_ ADCS8_PA_FPAS_SnsrObjWrnnglc_LSDW : 151|2@0+ (1,0) [0|3] "NoUnit" GW_FD4,CDCS
 SG_ ADCS8_TSR_LeftLightColor : 159|2@0+ (1,0) [0|3] "NoUnit" GW_FD4,ICU,CDCS
 SG_ ADCS8_TSR_RightLightColor : 157|2@0+ (1,0) [0|3] "NoUnit" GW_FD4,ICU,CDCS
 SG_ ADCS8_TSR_StrLightColor : 155|2@0+ (1,0) [0|3] "NoUnit" GW_FD4,ICU,CDCS
 SG_ ADCS8_TSR_SystemFaultStatus : 153|2@0+ (1,0) [0|3] "NoUnit" GW_FD4,ICU,CDCS
 SG_ ADCS8_NPilot_SysState : 167|3@0+ (1,0) [0|7] "NoUnit" IDB1,GW_FD4,IDB2,ICU,RCU1,CDCS
 SG_ ADCS8_NPilot_SystemFaultStatus : 164|3@0+ (1,0) [0|7] "NoUnit" IDB1,GW_FD4,IDB2,ICU,RCU1,CDCS
 SG_ ADCS8_VoiceNotifFrequency_mode : 161|2@0+ (1,0) [0|3] "NoUnit" GW_FD4,CDCS
 SG_ ADCS8_NNPSysState : 175|3@0+ (1,0) [0|7] "NoUnit" GW_FD4,ICU,CDCS
 SG_ ADCS8_NNP_SystemFaultStatus : 172|3@0+ (1,0) [0|7] "NoUnit" GW_FD4,ICU,CDCS
 SG_ ADCS8_NNP_AutoOnOffSet : 169|2@0+ (1,0) [0|3] "NoUnit" GW_FD4,ICU,CDCS
 SG_ ADCS8_DCLCSysState : 191|2@0+ (1,0) [0|3] "NoUnit" GW_FD4,ICU,CDCS
 SG_ ADCS8_Lanechangeinfor : 189|3@0+ (1,0) [0|7] "NoUnit" GW_FD4,ICU,CDCS
 SG_ ADCS8_LaneChangeWarning : 205|2@0+ (1,0) [0|3] "NoUnit" GW_FD4,ICU,CDCS
 SG_ ADCS8_LaneChangeSystemFaultStatus : 194|3@0+ (1,0) [0|7] "NoUnit" GW_FD4,ICU,CDCS
 SG_ ADCS8_GMState : 203|2@0+ (1,0) [0|3] "NoUnit" TBOX,GW_FD5,GW_FD4,GW_FD1,ICU,PDCS1,CDCS
 SG_ ADCS8_GMWarnState : 201|2@0+ (1,0) [0|3] "NoUnit" TBOX,GW_FD5,GW_FD4,ICU,GW_FD2,BDCS,CDCS
 SG_ ADCS8_GMWorkState : 210|3@0+ (1,0) [0|7] "NoUnit" TBOX,GW_FD5,GW_FD4,CDCS
 SG_ ADCS8_ADAS_DriveOffPossilbe : 211|1@0+ (1,0) [0|1] "NoUnit" GW_FD4,ICU,CDCS
 SG_ ADCS8_DriveOffinhibitionObjType : 222|3@0+ (1,0) [0|7] "NoUnit" GW_FD4,ICU,CDCS
 SG_ ADCS8_FRS_Fail : 217|2@0+ (1,0) [0|3] "NoUnit" GW_FD4,ICU,CDCS
 SG_ ADCS8_SRR_FL_Fail : 215|2@0+ (1,0) [0|3] "NoUnit" GW_FD4,ICU,CDCS
 SG_ ADCS8_SRR_FR_Fail : 231|2@0+ (1,0) [0|3] "NoUnit" GW_FD4,ICU,CDCS
 SG_ ADCS8_SRR_RL_Fail : 219|2@0+ (1,0) [0|3] "NoUnit" GW_FD4,ICU,CDCS
 SG_ ADCS8_SRR_RR_Fail : 229|2@0+ (1,0) [0|3] "NoUnit" GW_FD4,ICU,CDCS
 SG_ ADCS8_FVC_120_Fail : 245|2@0+ (1,0) [0|3] "NoUnit" GW_FD4,ICU,CDCS
 SG_ ADCS8_FVC_30_Fail : 251|2@0+ (1,0) [0|3] "NoUnit" GW_FD4,ICU,CDCS
 SG_ ADCS8_SVC_FL_Fail : 227|2@0+ (1,0) [0|3] "NoUnit" GW_FD4,ICU,CDCS
 SG_ ADCS8_SVC_FR_Fail : 255|2@0+ (1,0) [0|3] "NoUnit" GW_FD4,ICU,CDCS
 SG_ ADCS8_SVC_RL_Fail : 225|2@0+ (1,0) [0|3] "NoUnit" GW_FD4,ICU,CDCS
 SG_ ADCS8_SVC_RR_Fail : 253|2@0+ (1,0) [0|3] "NoUnit" GW_FD4,ICU,CDCS
 SG_ ADCS8_RVC_Fail : 239|2@0+ (1,0) [0|3] "NoUnit" GW_FD4,ICU,CDCS
 SG_ ADCS8_TSR_OverspeedOnOffSet : 233|2@0+ (1,0) [0|3] "NoUnit" GW_FD4,CDCS
 SG_ ADCS8_Lanechangedirection : 247|2@0+ (1,0) [0|3] "NoUnit" GW_FD4,CDCS
 SG_ ADCS8_VoiceMode : 240|1@0+ (1,0) [0|1] "NoUnit" GW_FD4,ICU,CDCS
 SG_ ADCS8_ALC_mode : 241|1@0+ (1,0) [0|1] "NoUnit" GW_FD4,ICU,CDCS
 SG_ ADCS8_NNP_State : 242|1@0+ (1,0) [0|1] "NoUnit" GW_FD4,CDCS
 SG_ ADCS8_ADSDriving_mode : 249|2@0+ (1,0) [0|3] "NoUnit" GW_FD4,ICU,CDCS
 SG_ ADCS8_NNP_MRM_status : 258|3@0+ (1,0) [0|7] "NoUnit" GW_FD4,ICU,CDCS
 SG_ ADCS8_GM_SystemFaultStatus : 269|2@0+ (1,0) [0|3] "NoUnit" GW_FD4,ICU,CDCS
 SG_ ADCS8_SystemFault : 271|2@0+ (1,0) [0|3] "NoUnit" GW_FD4,ICU,CDCS
 SG_ ADCS8_LeftLidarFault : 273|2@0+ (1,0) [0|3] "NoUnit" GW_FD4,CDCS
 SG_ ADCS8_RightlidarFault : 275|2@0+ (1,0) [0|3] "NoUnit" GW_FD4,CDCS
 SG_ ADCS8_AVMFrontCAMFault : 277|2@0+ (1,0) [0|3] "NoUnit" GW_FD4,CDCS
 SG_ ADCS8_AVMLeftCAMFault : 279|2@0+ (1,0) [0|3] "NoUnit" GW_FD4,CDCS
 SG_ ADCS8_AVMRightCAMFault : 281|2@0+ (1,0) [0|3] "NoUnit" GW_FD4,CDCS
 SG_ ADCS8_AVMRearCAMFault : 283|2@0+ (1,0) [0|3] "NoUnit" GW_FD4,CDCS

BO_ 404 ADCS_Fr10_194: 64 ADCS_FD3
 SG_ ADCS8_RPA_CheckListDispReq1 : 5|1@0+ (1,0) [0|1] "NoUnit" TBOX,GW_FD5,GW_FD4,BTM,GW_FD2,CDCS
 SG_ ADCS8_RPA_CheckListDispReq2 : 4|1@0+ (1,0) [0|1] "NoUnit" TBOX,GW_FD5,GW_FD4,BTM,GW_FD2,CDCS
 SG_ ADCS8_RPA_CheckListDispReq3 : 3|1@0+ (1,0) [0|1] "NoUnit" TBOX,GW_FD5,GW_FD4,BTM,GW_FD2,CDCS
 SG_ ADCS8_RPA_CheckListDispReq4 : 2|1@0+ (1,0) [0|1] "NoUnit" TBOX,GW_FD5,GW_FD4,BTM,GW_FD2,CDCS
 SG_ ADCS8_RPA_CheckListDispReq5 : 1|1@0+ (1,0) [0|1] "NoUnit" TBOX,GW_FD5,GW_FD4,BTM,GW_FD2,CDCS
 SG_ ADCS8_RPA_CheckListDispReq6 : 0|1@0+ (1,0) [0|1] "NoUnit" TBOX,GW_FD5,GW_FD4,BTM,GW_FD2,CDCS
 SG_ ADCS8_PA_warninginfo : 15|8@0+ (1,0) [0|255] "NoUnit" TBOX,GW_FD5,GW_FD4,BTM,GW_FD2,CDCS
 SG_ ADCS8_RPA_CheckListDispReq7 : 23|1@0+ (1,0) [0|1] "NoUnit" TBOX,GW_FD5,GW_FD4,BTM,GW_FD2,CDCS
 SG_ ADCS8_RPA_CheckListDispReq8 : 22|1@0+ (1,0) [0|1] "NoUnit" TBOX,GW_FD5,GW_FD4,BTM,GW_FD2,CDCS
 SG_ ADCS8_PA_FPAS_SnsrObjWrnngZn_FLC : 21|3@0+ (1,0) [0|7] "NoUnit" TBOX,GW_FD5,GW_FD4,BTM,GW_FD2,CDCS
 SG_ ADCS8_PA_FPAS_SnsrObjWrnngZn_FLM : 18|3@0+ (1,0) [0|7] "NoUnit" TBOX,GW_FD5,GW_FD4,BTM,GW_FD2,CDCS
 SG_ ADCS8_PA_FPAS_SnsrObjWrnngZn_FRM : 31|3@0+ (1,0) [0|7] "NoUnit" TBOX,GW_FD5,GW_FD4,BTM,GW_FD2,CDCS
 SG_ ADCS8_PA_FPAS_SnsrObjWrnngZn_FRC : 28|3@0+ (1,0) [0|7] "NoUnit" TBOX,GW_FD5,GW_FD4,BTM,GW_FD2,CDCS
 SG_ ADCS8_PA_FPAS_SnsrObjWrnngZn_RLC : 39|3@0+ (1,0) [0|7] "NoUnit" TBOX,GW_FD5,GW_FD4,BTM,GW_FD2,CDCS
 SG_ ADCS8_PA_FPAS_SnsrObjWrnngZn_RLM : 36|3@0+ (1,0) [0|7] "NoUnit" TBOX,GW_FD5,GW_FD4,BTM,GW_FD2,CDCS
 SG_ ADCS8_PA_FPAS_SnsrObjWrnngZn_RRM : 47|3@0+ (1,0) [0|7] "NoUnit" TBOX,GW_FD5,GW_FD4,BTM,GW_FD2,CDCS
 SG_ ADCS8_PA_FPAS_SnsrObjWrnngZn_RRC : 44|3@0+ (1,0) [0|7] "NoUnit" TBOX,GW_FD5,GW_FD4,BTM,GW_FD2,CDCS
 SG_ ADCS8_PA_FPAS_SnsrObjWrnngZn_SFL : 55|3@0+ (1,0) [0|7] "NoUnit" TBOX,GW_FD5,GW_FD4,BTM,GW_FD2,CDCS
 SG_ ADCS8_PA_FPAS_SnsrObjWrnngZn_SFR : 52|3@0+ (1,0) [0|7] "NoUnit" TBOX,GW_FD5,GW_FD4,BTM,GW_FD2,CDCS
 SG_ ADCS8_PA_FPAS_SnsrObjWrnngZn_SRL : 63|3@0+ (1,0) [0|7] "NoUnit" TBOX,GW_FD5,GW_FD4,BTM,GW_FD2,CDCS
 SG_ ADCS8_PA_FPAS_SnsrObjWrnngZn_SRR : 60|3@0+ (1,0) [0|7] "NoUnit" TBOX,GW_FD5,GW_FD4,BTM,GW_FD2,CDCS
 SG_ ADCS8_PA_FPAS_SnsrDist_FLC : 71|8@0+ (1,0) [0|255] "cm" TBOX,GW_FD5,GW_FD4,BTM,GW_FD2,CDCS
 SG_ ADCS8_PA_FPAS_SnsrDist_FLM : 79|8@0+ (1,0) [0|255] "cm" TBOX,GW_FD5,GW_FD4,BTM,GW_FD2,CDCS
 SG_ ADCS8_PA_FPAS_SnsrDist_FRM : 87|8@0+ (1,0) [0|255] "cm" TBOX,GW_FD5,GW_FD4,BTM,GW_FD2,CDCS
 SG_ ADCS8_PA_FPAS_SnsrDist_FRC : 95|8@0+ (1,0) [0|255] "cm" TBOX,GW_FD5,GW_FD4,BTM,GW_FD2,CDCS
 SG_ ADCS8_PA_FPAS_SnsrDist_RLC : 103|8@0+ (1,0) [0|255] "cm" TBOX,GW_FD5,GW_FD4,BTM,GW_FD2,CDCS
 SG_ ADCS8_PA_FPAS_SnsrDist_RLM : 111|8@0+ (1,0) [0|255] "cm" TBOX,GW_FD5,GW_FD4,BTM,GW_FD2,CDCS
 SG_ ADCS8_PA_FPAS_SnsrDist_RRM : 119|8@0+ (1,0) [0|255] "cm" TBOX,GW_FD5,GW_FD4,BTM,GW_FD2,CDCS
 SG_ ADCS8_PA_FPAS_SnsrDist_RRC : 127|8@0+ (1,0) [0|255] "cm" TBOX,GW_FD5,GW_FD4,BTM,GW_FD2,CDCS
 SG_ ADCS8_PA_FPAS_SnsrDist_SFL : 135|9@0+ (1,0) [0|511] "cm" TBOX,GW_FD5,GW_FD4,BTM,GW_FD2,CDCS
 SG_ ADCS8_PA_FPAS_SnsrDist_SFR : 142|9@0+ (1,0) [0|511] "cm" TBOX,GW_FD5,GW_FD4,BTM,GW_FD2,CDCS
 SG_ ADCS8_PA_FPAS_SnsrDist_SRL : 149|9@0+ (1,0) [0|511] "cm" TBOX,GW_FD5,GW_FD4,BTM,GW_FD2,CDCS
 SG_ ADCS8_PA_FPAS_SnsrDist_SRR : 156|9@0+ (1,0) [0|511] "cm" TBOX,GW_FD5,GW_FD4,BTM,GW_FD2,CDCS
 SG_ ADCS8_PA_FPAS_WorkSts : 175|2@0+ (1,0) [0|3] "NoUnit" GW_FD4,BTM,GW_FD2,CDCS
 SG_ ADCS8_PA_RPAS_WorkSts : 173|2@0+ (1,0) [0|3] "NoUnit" GW_FD4,BTM,GW_FD2,CDCS
 SG_ ADCS8_PA_FPAS_SensorFaultStsFLC : 171|1@0+ (1,0) [0|1] "NoUnit" TBOX,GW_FD5,GW_FD4,BTM,GW_FD2,CDCS
 SG_ ADCS8_PA_FPAS_SensorFaultStsFLM : 170|1@0+ (1,0) [0|1] "NoUnit" TBOX,GW_FD5,GW_FD4,BTM,GW_FD2,CDCS
 SG_ ADCS8_PA_FPAS_SensorFaultStsFRM : 169|1@0+ (1,0) [0|1] "NoUnit" TBOX,GW_FD5,GW_FD4,BTM,GW_FD2,CDCS
 SG_ ADCS8_PA_FPAS_SensorFaultStsFRC : 168|1@0+ (1,0) [0|1] "NoUnit" TBOX,GW_FD5,GW_FD4,BTM,GW_FD2,CDCS
 SG_ ADCS8_PA_RPAS_SensorFaultStsRLC : 183|1@0+ (1,0) [0|1] "NoUnit" TBOX,GW_FD5,GW_FD4,BTM,GW_FD2,CDCS
 SG_ ADCS8_PA_RPAS_SensorFaultStsRLM : 182|1@0+ (1,0) [0|1] "NoUnit" TBOX,GW_FD5,GW_FD4,BTM,GW_FD2,CDCS
 SG_ ADCS8_PA_RPAS_SensorFaultStsRRM : 181|1@0+ (1,0) [0|1] "NoUnit" TBOX,GW_FD5,GW_FD4,BTM,GW_FD2,CDCS
 SG_ ADCS8_PA_RPAS_SensorFaultStsRRC : 180|1@0+ (1,0) [0|1] "NoUnit" TBOX,GW_FD5,GW_FD4,BTM,GW_FD2,CDCS
 SG_ ADCS8_PA_FPAS_SensorFaultStsSFL : 179|1@0+ (1,0) [0|1] "NoUnit" TBOX,GW_FD5,GW_FD4,BTM,GW_FD2,CDCS
 SG_ ADCS8_PA_FPAS_SensorFaultStsSFR : 178|1@0+ (1,0) [0|1] "NoUnit" TBOX,GW_FD5,GW_FD4,BTM,GW_FD2,CDCS
 SG_ ADCS8_PA_RPAS_SensorFaultStsSRL : 177|1@0+ (1,0) [0|1] "NoUnit" TBOX,GW_FD5,GW_FD4,BTM,GW_FD2,CDCS
 SG_ ADCS8_PA_RPAS_SensorFaultStsSRR : 176|1@0+ (1,0) [0|1] "NoUnit" TBOX,GW_FD5,GW_FD4,BTM,GW_FD2,CDCS
 SG_ ADCS8_AudBpRate_R : 186|3@0+ (1,0) [0|7] "NoUnit" GW_FD4,BTM,GW_FD2,CDCS
 SG_ ADCS8_AudBpRate_F : 189|3@0+ (1,0) [0|7] "NoUnit" GW_FD4,BTM,GW_FD2,CDCS
 SG_ ADCS8_AVM_RomoteAVMFeedBack : 191|1@0+ (1,0) [0|1] "NoUnit" TBOX,GW_FD5,GW_FD4,BTM,GW_FD2
 SG_ ADCS8_AVM_MODWarning : 190|1@0+ (1,0) [0|1] "NoUnit" TBOX,GW_FD5,GW_FD4,BTM,GW_FD2,CDCS

BO_ 402 ADCS_Fr07_192: 64 ADCS_FD3
 SG_ ADCS7_RPA_slot_ID_7_P0_X : 7|14@0+ (0.01,-80) [-80|83.83] "m" GW_FD4,BTM,GW_FD2,CDCS
 SG_ ADCS7_RPA_slot_ID_7_P0_Y : 9|14@0+ (0.01,-80) [-80|83.83] "m" GW_FD4,BTM,GW_FD2,CDCS
 SG_ ADCS7_RPA_slot_ID_7_P1_X : 27|14@0+ (0.01,-80) [-80|83.83] "m" GW_FD4,BTM,GW_FD2,CDCS
 SG_ ADCS7_RPA_slot_ID_7_P1_Y : 45|14@0+ (0.01,-80) [-80|83.83] "m" GW_FD4,BTM,GW_FD2,CDCS
 SG_ ADCS7_RPA_slot_ID_7_P2_X : 63|14@0+ (0.01,-80) [-80|83.83] "m" GW_FD4,BTM,GW_FD2,CDCS
 SG_ ADCS7_RPA_slot_ID_7_P2_Y : 65|14@0+ (0.01,-80) [-80|83.83] "m" GW_FD4,BTM,GW_FD2,CDCS
 SG_ ADCS7_RPA_slot_ID_7_P3_X : 83|14@0+ (0.01,-80) [-80|83.83] "m" GW_FD4,BTM,GW_FD2,CDCS
 SG_ ADCS7_RPA_slot_ID_7_P3_Y : 101|14@0+ (0.01,-80) [-80|83.83] "m" GW_FD4,BTM,GW_FD2,CDCS
 SG_ ADCS7_RPA_slot_Angle7 : 118|15@0+ (0.001,0) [0|32.767] "rad/s" GW_FD4,BTM,GW_FD2,CDCS
 SG_ ADCS7_RPA_ParkingSlotDirection7 : 159|2@0+ (1,0) [0|3] "NoUnit" GW_FD4,BTM,GW_FD2,CDCS
 SG_ ADCS7_RPA_ParkingSlotType7 : 157|2@0+ (1,0) [0|3] "NoUnit" GW_FD4,BTM,GW_FD2,CDCS
 SG_ ADCS7_RPA_ParkingSlotDepth7 : 135|11@0+ (0.01,0) [0|20.47] "m" GW_FD4,BTM,GW_FD2,CDCS
 SG_ ADCS7_RPA_ParkingSlotWidth7 : 138|11@0+ (0.01,0) [0|20.47] "m" GW_FD4,BTM,GW_FD2,CDCS
 SG_ ADCS7_RPA_slot_ID_8_P0_X : 183|14@0+ (0.01,-80) [-80|83.83] "m" GW_FD4,BTM,GW_FD2,CDCS
 SG_ ADCS7_RPA_slot_ID_8_P0_Y : 185|14@0+ (0.01,-80) [-80|83.83] "m" GW_FD4,BTM,GW_FD2,CDCS
 SG_ ADCS7_RPA_slot_ID_8_P1_X : 203|14@0+ (0.01,-80) [-80|83.83] "m" GW_FD4,BTM,GW_FD2,CDCS
 SG_ ADCS7_RPA_slot_ID_8_P1_Y : 221|14@0+ (0.01,-80) [-80|83.83] "m" GW_FD4,BTM,GW_FD2,CDCS
 SG_ ADCS7_RPA_slot_ID_8_P2_X : 239|14@0+ (0.01,-80) [-80|83.83] "m" GW_FD4,BTM,GW_FD2,CDCS
 SG_ ADCS7_RPA_slot_ID_8_P2_Y : 241|14@0+ (0.01,-80) [-80|83.83] "m" GW_FD4,BTM,GW_FD2,CDCS
 SG_ ADCS7_RPA_slot_ID_8_P3_X : 259|14@0+ (0.01,-80) [-80|83.83] "m" GW_FD4,BTM,GW_FD2,CDCS
 SG_ ADCS7_RPA_slot_ID_8_P3_Y : 277|14@0+ (0.01,-80) [-80|83.83] "m" GW_FD4,BTM,GW_FD2,CDCS
 SG_ ADCS7_RPA_slot_Angle8 : 294|15@0+ (0.001,0) [0|32.767] "rad/s" GW_FD4,BTM,GW_FD2,CDCS
 SG_ ADCS7_RPA_ParkingSlotDirection8 : 335|2@0+ (1,0) [0|3] "NoUnit" GW_FD4,BTM,GW_FD2,CDCS
 SG_ ADCS7_RPA_ParkingSlotType8 : 333|2@0+ (1,0) [0|3] "NoUnit" GW_FD4,BTM,GW_FD2,CDCS
 SG_ ADCS7_RPA_ParkingSlotDepth8 : 311|11@0+ (0.01,0) [0|20.47] "m" GW_FD4,BTM,GW_FD2,CDCS
 SG_ ADCS7_RPA_ParkingSlotWidth8 : 314|11@0+ (0.01,0) [0|20.47] "m" GW_FD4,BTM,GW_FD2,CDCS
 SG_ ADCS7_PA_ObsDist_F : 487|8@0+ (0.01,0) [0|2.55] "m" GW_FD4,BTM,GW_FD2,CDCS
 SG_ ADCS7_PA_ObsDist_R : 495|8@0+ (0.01,0) [0|2.55] "m" GW_FD4,BTM,GW_FD2,CDCS
 SG_ ADCS7_RPA_ObsArea : 498|3@0+ (1,0) [0|7] "NoUnit" GW_FD4,BTM,GW_FD2,CDCS
 SG_ ADCS7_RPA_ObsDist : 511|8@0+ (0.01,0) [0|2.55] "m" GW_FD4,BTM,GW_FD2,CDCS
 SG_ ADCS7_RPA_slot_ID_7_Status : 140|2@0+ (1,0) [0|3] "NoUnit" GW_FD4,BTM,GW_FD2,CDCS
 SG_ ADCS7_RPA_slot_ID_8_Status : 316|2@0+ (1,0) [0|3] "NoUnit" GW_FD4,BTM,GW_FD2,CDCS

BO_ 401 ADCS_Fr06_191: 64 ADCS_FD3
 SG_ ADCS6_RPA_slot_ID_4_P0_X : 7|14@0+ (0.01,-80) [-80|83.83] "m" GW_FD4,BTM,GW_FD2,CDCS
 SG_ ADCS6_RPA_slot_ID_4_P0_Y : 9|14@0+ (0.01,-80) [-80|83.83] "m" GW_FD4,BTM,GW_FD2,CDCS
 SG_ ADCS6_RPA_slot_ID_4_P1_X : 27|14@0+ (0.01,-80) [-80|83.83] "m" GW_FD4,BTM,GW_FD2,CDCS
 SG_ ADCS6_RPA_slot_ID_4_P1_Y : 45|14@0+ (0.01,-80) [-80|83.83] "m" GW_FD4,BTM,GW_FD2,CDCS
 SG_ ADCS6_RPA_slot_ID_4_P2_X : 63|14@0+ (0.01,-80) [-80|83.83] "m" GW_FD4,BTM,GW_FD2,CDCS
 SG_ ADCS6_RPA_slot_ID_4_P2_Y : 65|14@0+ (0.01,-80) [-80|83.83] "m" GW_FD4,BTM,GW_FD2,CDCS
 SG_ ADCS6_RPA_slot_ID_4_P3_X : 83|14@0+ (0.01,-80) [-80|83.83] "m" GW_FD4,BTM,GW_FD2,CDCS
 SG_ ADCS6_RPA_slot_ID_4_P3_Y : 101|14@0+ (0.01,-80) [-80|83.83] "m" GW_FD4,BTM,GW_FD2,CDCS
 SG_ ADCS6_RPA_slot_Angle4 : 118|15@0+ (0.001,0) [0|32.767] "rad/s" GW_FD4,BTM,GW_FD2,CDCS
 SG_ ADCS6_RPA_ParkingSlotDirection4 : 159|2@0+ (1,0) [0|3] "NoUnit" GW_FD4,BTM,GW_FD2,CDCS
 SG_ ADCS6_RPA_slot_ID_4_Status : 155|2@0+ (1,0) [0|3] "NoUnit" GW_FD4,BTM,GW_FD2,CDCS
 SG_ ADCS6_RPA_slot_ID_5_Status : 331|2@0+ (1,0) [0|3] "NoUnit" GW_FD4,BTM,GW_FD2,CDCS
 SG_ ADCS6_RPA_ParkingSlotType4 : 157|2@0+ (1,0) [0|3] "NoUnit" GW_FD4,BTM,GW_FD2,CDCS
 SG_ ADCS6_RPA_ParkingSlotDepth4 : 135|11@0+ (0.01,0) [0|20.47] "m" GW_FD4,BTM,GW_FD2,CDCS
 SG_ ADCS6_RPA_ParkingSlotWidth4 : 138|11@0+ (0.01,0) [0|20.47] "m" GW_FD4,BTM,GW_FD2,CDCS
 SG_ ADCS6_RPA_slot_ID_5_P0_X : 183|14@0+ (0.01,-80) [-80|83.83] "m" GW_FD4,BTM,GW_FD2,CDCS
 SG_ ADCS6_RPA_slot_ID_5_P0_Y : 185|14@0+ (0.01,-80) [-80|83.83] "m" GW_FD4,BTM,GW_FD2,CDCS
 SG_ ADCS6_RPA_slot_ID_5_P1_X : 203|14@0+ (0.01,-80) [-80|83.83] "m" GW_FD4,BTM,GW_FD2,CDCS
 SG_ ADCS6_RPA_slot_ID_5_P1_Y : 221|14@0+ (0.01,-80) [-80|83.83] "m" GW_FD4,BTM,GW_FD2,CDCS
 SG_ ADCS6_RPA_slot_ID_5_P2_X : 239|14@0+ (0.01,-80) [-80|83.83] "m" GW_FD4,BTM,GW_FD2,CDCS
 SG_ ADCS6_RPA_slot_ID_5_P2_Y : 241|14@0+ (0.01,-80) [-80|83.83] "m" GW_FD4,BTM,GW_FD2,CDCS
 SG_ ADCS6_RPA_slot_ID_5_P3_X : 259|14@0+ (0.01,-80) [-80|83.83] "m" GW_FD4,BTM,GW_FD2,CDCS
 SG_ ADCS6_RPA_slot_ID_5_P3_Y : 277|14@0+ (0.01,-80) [-80|83.83] "m" GW_FD4,BTM,GW_FD2,CDCS
 SG_ ADCS6_RPA_slot_Angle5 : 294|15@0+ (0.001,0) [0|32.767] "rad/s" GW_FD4,BTM,GW_FD2,CDCS
 SG_ ADCS6_RPA_ParkingSlotDirection5 : 335|2@0+ (1,0) [0|3] "NoUnit" GW_FD4,BTM,GW_FD2,CDCS
 SG_ ADCS6_RPA_ParkingSlotType5 : 333|2@0+ (1,0) [0|3] "NoUnit" GW_FD4,BTM,GW_FD2,CDCS
 SG_ ADCS6_RPA_ParkingSlotDepth5 : 311|11@0+ (0.01,0) [0|20.47] "m" GW_FD4,BTM,GW_FD2,CDCS
 SG_ ADCS6_RPA_ParkingSlotWidth5 : 314|11@0+ (0.01,0) [0|20.47] "m" GW_FD4,BTM,GW_FD2,CDCS
 SG_ ADCS6_RPA_slot_ID_6_P0_X : 359|14@0+ (0.01,-80) [-80|83.83] "m" GW_FD4,BTM,GW_FD2,CDCS
 SG_ ADCS6_RPA_slot_ID_6_P0_Y : 361|14@0+ (0.01,-80) [-80|83.83] "m" GW_FD4,BTM,GW_FD2,CDCS
 SG_ ADCS6_RPA_slot_ID_6_P1_X : 379|14@0+ (0.01,-80) [-80|83.83] "m" GW_FD4,BTM,GW_FD2,CDCS
 SG_ ADCS6_RPA_slot_ID_6_P1_Y : 397|14@0+ (0.01,-80) [-80|83.83] "m" GW_FD4,BTM,GW_FD2,CDCS
 SG_ ADCS6_RPA_slot_ID_6_P2_X : 415|14@0+ (0.01,-80) [-80|83.83] "m" GW_FD4,BTM,GW_FD2,CDCS
 SG_ ADCS6_RPA_slot_ID_6_P2_Y : 417|14@0+ (0.01,-80) [-80|83.83] "m" GW_FD4,BTM,GW_FD2,CDCS
 SG_ ADCS6_RPA_slot_ID_6_P3_X : 435|14@0+ (0.01,-80) [-80|83.83] "m" GW_FD4,BTM,GW_FD2,CDCS
 SG_ ADCS6_RPA_slot_ID_6_P3_Y : 453|14@0+ (0.01,-80) [-80|83.83] "m" GW_FD4,BTM,GW_FD2,CDCS
 SG_ ADCS6_RPA_slot_Angle6 : 470|15@0+ (0.001,0) [0|32.767] "rad/s" GW_FD4,BTM,GW_FD2,CDCS
 SG_ ADCS6_RPA_ParkingSlotDirection6 : 511|2@0+ (1,0) [0|3] "NoUnit" GW_FD4,BTM,GW_FD2,CDCS
 SG_ ADCS6_RPA_ParkingSlotType6 : 509|2@0+ (1,0) [0|3] "NoUnit" GW_FD4,BTM,GW_FD2,CDCS
 SG_ ADCS6_RPA_ParkingSlotDepth6 : 487|11@0+ (0.01,0) [0|20.47] "m" GW_FD4,BTM,GW_FD2,CDCS
 SG_ ADCS6_RPA_ParkingSlotWidth6 : 490|11@0+ (0.01,0) [0|20.47] "m" GW_FD4,BTM,GW_FD2,CDCS
 SG_ ADCS6_RPA_slot_ID_6_Status : 507|2@0+ (1,0) [0|3] "NoUnit" GW_FD4,BTM,GW_FD2,CDCS

BO_ 400 ADCS_Fr05_190: 64 ADCS_FD3
 SG_ ADCS5_RPA_slot_ID_1_P0_X : 7|14@0+ (0.01,-80) [-80|83.83] "m" GW_FD4,BTM,GW_FD2,CDCS
 SG_ ADCS5_RPA_slot_ID_1_P0_Y : 9|14@0+ (0.01,-80) [-80|83.83] "m" GW_FD4,BTM,GW_FD2,CDCS
 SG_ ADCS5_RPA_slot_ID_1_P1_X : 27|14@0+ (0.01,-80) [-80|83.83] "m" GW_FD4,BTM,GW_FD2,CDCS
 SG_ ADCS5_RPA_slot_ID_1_P1_Y : 45|14@0+ (0.01,-80) [-80|83.83] "m" GW_FD4,BTM,GW_FD2,CDCS
 SG_ ADCS5_RPA_slot_ID_1_P2_X : 63|14@0+ (0.01,-80) [-80|83.83] "m" GW_FD4,BTM,GW_FD2,CDCS
 SG_ ADCS5_RPA_slot_ID_1_P2_Y : 65|14@0+ (0.01,-80) [-80|83.83] "m" GW_FD4,BTM,GW_FD2,CDCS
 SG_ ADCS5_RPA_slot_ID_1_P3_X : 83|14@0+ (0.01,-80) [-80|83.83] "m" GW_FD4,BTM,GW_FD2,CDCS
 SG_ ADCS5_RPA_slot_ID_1_P3_Y : 101|14@0+ (0.01,-80) [-80|83.83] "m" GW_FD4,BTM,GW_FD2,CDCS
 SG_ ADCS5_RPA_slot_Angle1 : 118|15@0+ (0.001,0) [0|32.767] "rad/s" GW_FD4,BTM,GW_FD2,CDCS
 SG_ ADCS5_RPA_slot_ID_1_Status : 155|2@0+ (1,0) [0|3] "NoUnit" GW_FD4,BTM,GW_FD2,CDCS
 SG_ ADCS5_RPA_slot_ID_2_Status : 331|2@0+ (1,0) [0|3] "NoUnit" GW_FD4,BTM,GW_FD2,CDCS
 SG_ ADCS5_RPA_slot_ID_3_Status : 507|2@0+ (1,0) [0|3] "NoUnit" GW_FD4,BTM,GW_FD2,CDCS
 SG_ ADCS5_RPA_ParkingSlotDirection1 : 159|2@0+ (1,0) [0|3] "NoUnit" GW_FD4,BTM,GW_FD2,CDCS
 SG_ ADCS5_RPA_ParkingSlotType1 : 157|2@0+ (1,0) [0|3] "NoUnit" GW_FD4,BTM,GW_FD2,CDCS
 SG_ ADCS5_RPA_ParkingSlotDepth1 : 135|11@0+ (0.01,0) [0|20.47] "m" GW_FD4,BTM,GW_FD2,CDCS
 SG_ ADCS5_RPA_ParkingSlotWidth1 : 138|11@0+ (0.01,0) [0|20.47] "m" GW_FD4,BTM,GW_FD2,CDCS
 SG_ ADCS5_RPA_slot_ID_2_P0_X : 183|14@0+ (0.01,-80) [-80|83.83] "m" GW_FD4,BTM,GW_FD2,CDCS
 SG_ ADCS5_RPA_slot_ID_2_P0_Y : 185|14@0+ (0.01,-80) [-80|83.83] "m" GW_FD4,BTM,GW_FD2,CDCS
 SG_ ADCS5_RPA_slot_ID_2_P1_X : 203|14@0+ (0.01,-80) [-80|83.83] "m" GW_FD4,BTM,GW_FD2,CDCS
 SG_ ADCS5_RPA_slot_ID_2_P1_Y : 221|14@0+ (0.01,-80) [-80|83.83] "m" GW_FD4,BTM,GW_FD2,CDCS
 SG_ ADCS5_RPA_slot_ID_2_P2_X : 239|14@0+ (0.01,-80) [-80|83.83] "m" GW_FD4,BTM,GW_FD2,CDCS
 SG_ ADCS5_RPA_slot_ID_2_P2_Y : 241|14@0+ (0.01,-80) [-80|83.83] "m" GW_FD4,BTM,GW_FD2,CDCS
 SG_ ADCS5_RPA_slot_ID_2_P3_X : 259|14@0+ (0.01,-80) [-80|83.83] "m" GW_FD4,BTM,GW_FD2,CDCS
 SG_ ADCS5_RPA_slot_ID_2_P3_Y : 277|14@0+ (0.01,-80) [-80|83.83] "m" GW_FD4,BTM,GW_FD2,CDCS
 SG_ ADCS5_RPA_slot_Angle2 : 294|15@0+ (0.001,0) [0|32.767] "rad/s" GW_FD4,BTM,GW_FD2,CDCS
 SG_ ADCS5_RPA_ParkingSlotDirection2 : 335|2@0+ (1,0) [0|3] "NoUnit" GW_FD4,BTM,GW_FD2,CDCS
 SG_ ADCS5_RPA_ParkingSlotType2 : 333|2@0+ (1,0) [0|3] "NoUnit" GW_FD4,BTM,GW_FD2,CDCS
 SG_ ADCS5_RPA_ParkingSlotDepth2 : 311|11@0+ (0.01,0) [0|20.47] "m" GW_FD4,BTM,GW_FD2,CDCS
 SG_ ADCS5_RPA_ParkingSlotWidth2 : 314|11@0+ (0.01,0) [0|20.47] "m" GW_FD4,BTM,GW_FD2,CDCS
 SG_ ADCS5_RPA_slot_ID_3_P0_X : 359|14@0+ (0.01,-80) [-80|83.83] "m" GW_FD4,BTM,GW_FD2,CDCS
 SG_ ADCS5_RPA_slot_ID_3_P0_Y : 361|14@0+ (0.01,-80) [-80|83.83] "m" GW_FD4,BTM,GW_FD2,CDCS
 SG_ ADCS5_RPA_slot_ID_3_P1_X : 379|14@0+ (0.01,-80) [-80|83.83] "m" GW_FD4,BTM,GW_FD2,CDCS
 SG_ ADCS5_RPA_slot_ID_3_P1_Y : 397|14@0+ (0.01,-80) [-80|83.83] "m" GW_FD4,BTM,GW_FD2,CDCS
 SG_ ADCS5_RPA_slot_ID_3_P2_X : 415|14@0+ (0.01,-80) [-80|83.83] "m" GW_FD4,BTM,GW_FD2,CDCS
 SG_ ADCS5_RPA_slot_ID_3_P2_Y : 417|14@0+ (0.01,-80) [-80|83.83] "m" GW_FD4,BTM,GW_FD2,CDCS
 SG_ ADCS5_RPA_slot_ID_3_P3_X : 435|14@0+ (0.01,-80) [-80|83.83] "m" GW_FD4,BTM,GW_FD2,CDCS
 SG_ ADCS5_RPA_slot_ID_3_P3_Y : 453|14@0+ (0.01,-80) [-80|83.83] "m" GW_FD4,BTM,GW_FD2,CDCS
 SG_ ADCS5_RPA_slot_Angle3 : 470|15@0+ (0.001,0) [0|32.767] "rad/s" GW_FD4,BTM,GW_FD2,CDCS
 SG_ ADCS5_RPA_ParkingSlotDirection3 : 511|2@0+ (1,0) [0|3] "NoUnit" GW_FD4,BTM,GW_FD2,CDCS
 SG_ ADCS5_RPA_ParkingSlotType3 : 509|2@0+ (1,0) [0|3] "NoUnit" GW_FD4,BTM,GW_FD2,CDCS
 SG_ ADCS5_RPA_ParkingSlotDepth3 : 487|11@0+ (0.01,0) [0|20.47] "m" GW_FD4,BTM,GW_FD2,CDCS
 SG_ ADCS5_RPA_ParkingSlotWidth3 : 490|11@0+ (0.01,0) [0|20.47] "m" GW_FD4,BTM,GW_FD2,CDCS

BO_ 254 ADCS_Fr04_0FE_APA2: 32 ADCS_FD3
 SG_ ADCS_AVM_RCW_warningReq : 1|2@0+ (1,0) [0|3] "NoUnit" GW_FD8,IDB1,GW_FD4,IDB2,EPS2,CDCS
 SG_ ADCS4_AVM_BSD_warningReqLeft : 3|2@0+ (1,0) [0|3] "NoUnit" PDCU,GW_FD4,GW_FD2,DDCU,CDCS
 SG_ ADCS4_AVM_BSD_warningReqRight : 5|2@0+ (1,0) [0|3] "NoUnit" PDCU,GW_FD4,GW_FD2,DDCU,CDCS
 SG_ ADCS4_PA_SysSoundIndication : 10|3@0+ (1,0) [0|7] "NoUnit" GW_FD4,CDCS
 SG_ ADCS4_PA_Sound_Location : 13|3@0+ (1,0) [0|7] "NoUnit" TBOX,GW_FD5,GW_FD4,CDCS
 SG_ ADCS4_AVM_vedioReq : 206|3@0+ (1,0) [0|7] "NoUnit" GW_FD4,CDCS
 SG_ ADCS4_AVM_Sts : 18|3@0+ (1,0) [0|7] "NoUnit" GW_FD4,CDCS
 SG_ ADCS4_RPA_RemoteParkFinishReq : 20|2@0+ (1,0) [0|3] "NoUnit" TBOX,GW_FD5,GW_FD4,CDCS
 SG_ ADCS4_AVM_BSD_SysSts : 23|3@0+ (1,0) [0|7] "NoUnit" GW_FD4,CDCS
 SG_ ADCS4_PA_InfoDisplayReq : 27|4@0+ (1,0) [0|15] "NoUnit" GW_FD4,BTM,ICU,GW_FD2,CDCS
 SG_ ADCS4_PA_failinfo : 31|4@0+ (1,0) [0|15] "NoUnit" GW_FD4,BTM,GW_FD2,CDCS
 SG_ ADCS4_UPA_Sound_Location : 35|4@0+ (1,0) [0|15] "NoUnit" GW_FD4,CDCS
 SG_ ADCS4_HPA_failinfo : 39|4@0+ (1,0) [0|15] "NoUnit" GW_FD4,CDCS
 SG_ ADCS4_UPA_SysSoundIndication : 42|3@0+ (1,0) [0|7] "NoUnit" GW_FD4,CDCS
 SG_ ADCS4_AVM_SysSoundIndication : 45|3@0+ (1,0) [0|7] "NoUnit" GW_FD4,CDCS
 SG_ ADCS4_PA_ParkBarPercent : 55|4@0+ (1,0) [0|15] "NoUnit" TBOX,GW_FD5,GW_FD4,BTM,GW_FD2,CDCS
 SG_ ADCS4_MsgCounter0 : 51|4@0+ (1,0) [0|15] "NoUnit" GW_FD4,CDCS
 SG_ ADCS4_Checksum0 : 63|8@0+ (1,0) [0|255] "NoUnit" GW_FD4,CDCS
 SG_ ADCS4_APA_FunctionMode : 70|3@0+ (1,0) [0|7] "NoUnit" GW_FD4,BTM,GW_FD2,CDCS
 SG_ ADCS4_Text : 79|8@0+ (1,0) [0|255] "NoUnit" GW_FD4,BTM,GW_FD2,CDCS
 SG_ ADCS4_ParkingswithReq : 80|1@0+ (1,0) [0|1] "NoUnit" GW_FD4,BTM,GW_FD2,CDCS
 SG_ ADCS4_Slotavaliable : 82|2@0+ (1,0) [0|3] "NoUnit" GW_FD4,BTM,GW_FD2,CDCS
 SG_ ADCS4_locationSt : 84|2@0+ (1,0) [0|3] "NoUnit" GW_FD4,CDCS
 SG_ ADCS4_PA_GuideLineE_a : 95|16@0+ (0.01,0) [0|655.35] "NoUnit" GW_FD4,BTM,GW_FD2,CDCS
 SG_ ADCS4_PA_GuideLineE_b : 111|16@0+ (0.01,0) [0|655.35] "NoUnit" GW_FD4,BTM,GW_FD2,CDCS
 SG_ ADCS4_PA_GuideLineE_c : 127|16@0+ (0.01,0) [0|655.35] "NoUnit" GW_FD4,BTM,GW_FD2,CDCS
 SG_ ADCS4_PA_GuideLineE_d : 143|16@0+ (0.01,0) [0|655.35] "NoUnit" GW_FD4,BTM,GW_FD2,CDCS
 SG_ ADCS4_PA_GuideLineE_Xmin : 159|16@0+ (0.01,0) [0|655.35] "NoUnit" GW_FD4,BTM,GW_FD2,CDCS
 SG_ ADCS4_PA_GuideLineE_Xmax : 175|16@0+ (0.01,0) [0|655.35] "NoUnit" GW_FD4,BTM,GW_FD2,CDCS
 SG_ ADCS4_ParkingTime : 185|10@0+ (1,0) [0|1023] "s" GW_FD4,BTM,GW_FD2,CDCS
 SG_ ADCS4_HPA_FunctionMode : 208|1@0+ (1,0) [0|1] "NoUnit" GW_FD4,CDCS
 SG_ ADCS4_HPAWarningInfo : 203|4@0+ (1,0) [0|15] "NoUnit" GW_FD4,CDCS
 SG_ ADCS4_HPA_deleteMapSt : 187|2@0+ (1,0) [0|3] "NoUnit" GW_FD4,CDCS
 SG_ ADCS4_HPA_uploadMapSt : 191|4@0+ (1,0) [0|15] "NoUnit" GW_FD4,CDCS
 SG_ ADCS4_NNS_FunctionMode : 211|3@0+ (1,0) [0|7] "NoUnit" TBOX,GW_FD5,GW_FD4,CDCS
 SG_ ADCS4_FindCarAvmStatus : 223|2@0+ (1,0) [0|3] "NoUnit" GW_FD4,CDCS
 SG_ ADCS4_HourOfDay : 221|6@0+ (1,0) [0|63] "NoUnit" TBOX,GW_FD5,GW_FD4,CDCS
 SG_ ADCS4_MinuteOfHour : 229|6@0+ (1,0) [0|63] "NoUnit" TBOX,GW_FD5,GW_FD4,CDCS
 SG_ ADCS4_SecondOfMinute : 237|6@0+ (1,0) [0|63] "NoUnit" TBOX,GW_FD5,GW_FD4,CDCS
 SG_ ADCS4_TractionswithReq : 212|1@0+ (1,0) [0|1] "NoUnit" GW_FD4,CDCS
 SG_ ADCS4_RPA_FunctionMode : 215|3@0+ (1,0) [0|7] "NoUnit" GW_FD4,BTM,GW_FD2,CDCS
 SG_ ADCS4_DCWposition : 47|2@0+ (1,0) [0|3] "NoUnit" GW_FD4,CDCS
 SG_ ADCS4_DCWlevel : 87|3@0+ (1,0) [0|7] "NoUnit" GW_FD4,CDCS

BO_TX_BU_ 579 : GW_FD5,GW_FD6,GW_FD3,GW_FD4,GW_FD1,GW_FD2;

CM_ SG_ 984 ADCS_Resp_EncrData0 "ADCS控制身份认证响应0";
CM_ SG_ 984 ADCS_Resp_EncrData1 "ADCS控制身份认证响应1";
CM_ SG_ 984 ADCS_Resp_EncrData2 "ADCS控制身份认证响应2";
CM_ SG_ 984 ADCS_Resp_EncrData3 "ADCS控制身份认证响应3";
CM_ SG_ 984 ADCS_Resp_EncrData4 "ADCS控制身份认证响应4";
CM_ SG_ 984 ADCS_Resp_EncrData5 "ADCS控制身份认证响应5";
CM_ SG_ 984 ADCS_Resp_EncrData6 "ADCS控制身份认证响应6";
CM_ SG_ 984 ADCS_Resp_EncrData7 "ADCS控制身份认证响应7";
CM_ SG_ 983 BDM_Chall_ADCS_Random_0 "ADCS控制身份认证随机数0";
CM_ SG_ 983 BDM_Chall_ADCS_Random_1 "ADCS控制身份认证随机数1";
CM_ SG_ 983 BDM_Chall_ADCS_Random_2 "ADCS控制身份认证随机数2";
CM_ SG_ 983 BDM_Chall_ADCS_Random_3 "ADCS控制身份认证随机数3";
CM_ SG_ 983 BDM_Chall_ADCS_Random_4 "ADCS控制身份认证随机数4";
CM_ SG_ 983 BDM_Chall_ADCS_Random_5 "ADCS控制身份认证随机数5";
CM_ SG_ 983 BDM_Chall_ADCS_Random_6 "ADCS控制身份认证随机数6";
CM_ SG_ 983 BDM_Chall_ADCS_Random_7 "ADCS控制身份认证随机数7";
CM_ SG_ 515 CDCS15_NNP_DriverStatus "驾驶员状态信号（DMS）";
CM_ SG_ 515 CDCS15_Storage_St "CDCS内部空间信号，用于哨兵模式状态机监控";
CM_ SG_ 515 CDCS15_USB_St "CDCS USB不可用信号，用于哨兵模式状态机监控";
CM_ SG_ 515 CDCS15_UserSceneMode "情景模式信号";
CM_ SG_ 597 ADCS13_HPA_ONPath_ID1 "记忆泊车当前车辆所在路线ID1";
CM_ SG_ 597 ADCS13_HPA_ONPath_ID2 "记忆泊车当前车辆所在路线ID2";
CM_ SG_ 597 ADCS13_HPA_ONPath_ID3 "记忆泊车当前车辆所在路线ID3";
CM_ SG_ 597 ADCS13_HPA_ONPath_ID4 "记忆泊车当前车辆所在路线ID4";
CM_ SG_ 579 AICS2_OTAMode "OTA模式进入及退出请求";
CM_ SG_ 579 AICS2_StopChargeing "断开充电";
CM_ SG_ 579 AICS2_BootRequestHVShut "OTA刷写三电下高压电请求";
CM_ SG_ 170 MCU1_MotorSpeed "电机转速";
CM_ SG_ 170 MCU1_ControllerTorque "实际输出扭矩
包含MCU Damping torque";
CM_ SG_ 170 MCU1_AliveCounter "E2E Profile2-CRC8H2F，Counter：0-15";
CM_ SG_ 170 MCU1_presentActivityFault "当前活动最严重错误号";
CM_ SG_ 170 MCU1_CurrentTorque "实际扭力值
[-400,400] Nm";
CM_ SG_ 170 MCU1_CurrentTorqueValid "实际扭力值有效位";
CM_ SG_ 171 FMCU1_MotorSpeed "电机转速";
CM_ SG_ 171 FMCU1_ControllerTorque "实际输出扭矩
包含MCU Damping torque";
CM_ SG_ 171 FMCU1_AliveCounter "E2E Profile2-CRC8H2F，Counter：0-15";
CM_ SG_ 171 FMCU1_Checksum "E2E Profile2-CRC8H2F
DataID List:#9 - 245 53 92 121 207 9 230 132 113 201 5 47 4 179 35 160";
CM_ SG_ 171 FMCU1_presentActivityFault "当前活动最严重错误号";
CM_ SG_ 171 FMCU1_CurrentTorque "实际扭力值
[-400,400] Nm";
CM_ SG_ 171 FMCU1_CurrentTorqueValid "实际扭力值有效位";
CM_ SG_ 177 EPS1_TorsionBarTorque "转向扭杆扭矩（驾驶员手力矩，左正右负）";
CM_ SG_ 177 EPS1_TorsionBarTorqueValid "转向杆扭矩有效位";
CM_ SG_ 177 EPS1_SteeringAngle "方向盘转角（左正右负）";
CM_ SG_ 177 EPS1_SteeringAngleValid "方向盘转角有效位";
CM_ SG_ 177 EPS1_SteerAngleSpd "方向盘角速度（左正右负）";
CM_ SG_ 177 EPS1_SteerAngleSpdValid "方向盘角速度有效位";
CM_ SG_ 177 EPS1_HSTWCalibrated "方向盘中位标定状态";
CM_ SG_ 177 EPS1_WarningLampYellow "EPS一般故障黄色警示灯";
CM_ SG_ 177 EPS1_WarningLampRed "EPS功能故障红色警示灯";
CM_ SG_ 177 EPS1_MsgCounter "E2E Profile2-CRC8H2F，Counter：0-15";
CM_ SG_ 177 EPS1_Checksum "E2E Profile2-CRC8H2F
DataID List:#7 - 12 243 207 94 6 201 30 183 35 143 78 190 188 108 16 38";
CM_ SG_ 178 EPS2_ADAS_Available "EPS ADAS功能可用状态";
CM_ SG_ 178 EPS2_ADAS_Active "EPS反馈ADAS功能激活状态";
CM_ SG_ 178 EPS2_ADAS_CtrlAbortFeedback "EPS当前跳出ADAS的原因";
CM_ SG_ 178 EPS2_AssistPraSwitchToDAS "EPS ADAS助力模式状态";
CM_ SG_ 178 EPS2_MotCntrl "电机控制扭矩 (left“+”,right“-” )";
CM_ SG_ 178 EPS2_MotCntrlValid "电机扭矩有效性";
CM_ SG_ 178 EPS2_PA_Available "EPS系统APA功能可用状态";
CM_ SG_ 178 EPS2_PA_Active "EPS反馈APA功能激活状态";
CM_ SG_ 178 EPS2_PA_CtrlAbortFeedback "EPS当前跳出APA的原因";
CM_ SG_ 178 EPS2_MsgCounter "E2E Profile2-CRC8H2F，Counter：0-15";
CM_ SG_ 178 EPS2_Checksum "E2E Profile2-CRC8H2F
DataID List:#10 - 4 65 1 42 110 208 168 45 211 25 191 226 12 167 122 106";
CM_ SG_ 229 IDB1_BrakePedalApplied "制动踏板踩下信号";
CM_ SG_ 229 IDB1_BrakePedalAppliedV "制动踏板踩下信号有效性";
CM_ SG_ 229 IDB1_FailedState "IDB故障及有效性";
CM_ SG_ 229 IDB1_CSTFail "CST功能失效";
CM_ SG_ 229 IDB1_CSTAtive "CST激活";
CM_ SG_ 229 IDB1_CSTEnabled "CST功能使能";
CM_ SG_ 229 IDB1_Brakestyle_Enabled "Brake style功能使能";
CM_ SG_ 229 IDB1_Brakestyle_Fail "Brake style功能失效";
CM_ SG_ 229 IDB1_Fr01_MsgCounter "E2E Profile2-CRC8H2F，Counter：0-15";
CM_ SG_ 229 IDB1_Fr01_Checksum "E2E Profile2-CRC8H2F
DataID List:#19 - 42 45 226 106 113 62 80 154 133 115 60 98 94 63 21 212";
CM_ SG_ 192 IDB2_FLWhlPulCnt "FL Wheel Pulse Counter";
CM_ SG_ 192 IDB2_FLWhlPulCntValid "FL Wheel Speed Sensor Validity";
CM_ SG_ 192 IDB2_FRWhlPulCnt "FR Wheel Pulse Counter";
CM_ SG_ 192 IDB2_FRWhlPulCntValid "FR Wheel Speed Sensor Validity";
CM_ SG_ 192 IDB2_Fr02_MsgCounter "E2E Profile2-CRC8H2F，Counter：0-15";
CM_ SG_ 192 IDB2_Fr02_Checksum "E2E Profile2-CRC8H2F
DataID List:#32 - 242 165 194 90 167 136 69 119 173 80 76 95 67 239 144 234";
CM_ SG_ 197 IDB3_VehicleSpd "Vehicle Speed 车速";
CM_ SG_ 197 IDB3_VehicleSpdValid "Vehicle Speed Status 车速有效位";
CM_ SG_ 197 IDB3_MasterCylPressure "主缸压力";
CM_ SG_ 197 IDB3_MasterCylPressureInvalid "主缸压力值有效性";
CM_ SG_ 197 IDB3_MsgCounter "E2E Profile2-CRC8H2F，Counter：0-15";
CM_ SG_ 197 IDB3_Checksum "E2E Profile2-CRC8H2F
DataID List:#54 - 87 57 114 13 81 177 37 40 90 82 133 184 56 248 43 107";
CM_ SG_ 199 IDB4_FLWhlVelocity "Wheel Ground Velocity FL";
CM_ SG_ 199 IDB4_FLWhlVelocityValid "Wheel Ground Velocity FL Valid";
CM_ SG_ 199 IDB4_FRWhlVelocity "Wheel Ground Velocity FR";
CM_ SG_ 199 IDB4_FRWhlVelocityValid "Wheel Ground Velocity FR Valid";
CM_ SG_ 199 IDB4_FRWhlDir "Wheel FR Directiion";
CM_ SG_ 199 IDB4_FLWhlDir "Wheel FL Directiion";
CM_ SG_ 199 IDB4_RLWhlDir "Wheel RL Directiion";
CM_ SG_ 199 IDB4_RRWhlDir "Wheel RR Directiion";
CM_ SG_ 199 IDB4_MsgCounter "E2E Profile2-CRC8H2F，Counter：0-15";
CM_ SG_ 199 IDB4_Checksum "E2E Profile2-CRC8H2F
DataID List:#2 - 180 134 53 233 243 121 67 176 9 94 168 132 198 142 201 138";
CM_ SG_ 199 IDB4_RLWhlVelocity "Wheel Ground Velocity RL";
CM_ SG_ 199 IDB4_RLWhlVelocityValid "Wheel Ground Velocity RL Valid";
CM_ SG_ 199 IDB4_RRWhlVelocity "Wheel Ground Velocity RR";
CM_ SG_ 199 IDB4_RRWhlVelocityValid "Wheel Ground Velocity RR Valid";
CM_ SG_ 199 IDB4_RLWhlPulCnt "RL Wheel Pulse Counter";
CM_ SG_ 199 IDB4_RRWhlPulCnt "RR Wheel Pulse Counter";
CM_ SG_ 199 IDB4_RLWhlPulCntValid "RL Wheel Speed Sensor Validity";
CM_ SG_ 199 IDB4_RRWhlPulCntValid "RR Wheel Speed Sensor Validity";
CM_ SG_ 289 IDB9_PA_CtrlAbortFeedback "ESC反馈泊车的终止原因";
CM_ SG_ 289 IDB9_PA_ParkingBrkMdSeln "ESC反馈当前制动模式";
CM_ SG_ 289 IDB9_PA_ParkingFnMd "ESC反馈当前功能模式";
CM_ SG_ 289 IDB9_PA_Prefill "PA预建压是否已开启";
CM_ SG_ 289 IDB9_PA_ParkingAvailable "当前是否满足泊车的状态信号";
CM_ SG_ 289 IDB9_PASts "ESC control state for APA";
CM_ SG_ 289 IDB9_PAStandStill "Stop confirmation signal during APA operation";
CM_ SG_ 289 IDB9_MsgCounter "E2E Profile2-CRC8H2F，Counter：0-15";
CM_ SG_ 289 IDB9_Checksum "E2E Profile2-CRC8H2F
DataID List:#67 - 24 231 54 71 249 240 162 122 56 55 94 118 178 174 32 41";
CM_ SG_ 297 IDB5_BrakeDiscTempSts "Over Temp status";
CM_ SG_ 297 IDB5_VehicleStanstill "Vehicle Stan still";
CM_ SG_ 297 IDB5_JerkActive "Jerk Active";
CM_ SG_ 297 IDB5_Jerkfail "Jerk fail";
CM_ SG_ 297 IDB5_ACC_ReqLim "Due to limitaion of the actuators the acceleration or deceleration request from FRM can not be processed or only partly";
CM_ SG_ 297 IDB5_DBSavailable "DBS function available";
CM_ SG_ 297 IDB5_Prefillavailable "Prefill function available";
CM_ SG_ 297 IDB5_ACC_ReferenceAccel "Feedback signal for the inner acceleration control loop";
CM_ SG_ 297 IDB5_ACC_Enable "This signal is set by the safety logic in the ESC.";
CM_ SG_ 297 IDB5_ACC_Sta "IDB ACC激活状态";
CM_ SG_ 297 IDB5_AEB_Enable "This signal is set by the safety logic for AEB in the ESC";
CM_ SG_ 297 IDB5_DriverOverride "Input signal which represents a driver accelerator/brake pedal press/release manipulation.";
CM_ SG_ 297 IDB5_MsgCounter "E2E Profile2-CRC8H2F，Counter：0-15";
CM_ SG_ 297 IDB5_Checksum "E2E Profile2-CRC8H2F
DataID List:#58 - 204 92 25 9 246 113 123 47 41 35 210 115 157 97 39 37";
CM_ SG_ 299 IDB6_EPBAvailable "Availability of EPB";
CM_ SG_ 299 IDB6_EPBStatus "EPB工作状态";
CM_ SG_ 301 IDB7_EBD_Fail "EBD Fault";
CM_ SG_ 301 IDB7_EBD_Active "EBD激活";
CM_ SG_ 301 IDB7_HBAActive "HBA激活";
CM_ SG_ 301 IDB7_HBAFail "HBA失效";
CM_ SG_ 301 IDB7_DiagMode "This signal indicate diagnostic mode condition";
CM_ SG_ 301 IDB7_TCSActive "Traction Control System Active";
CM_ SG_ 301 IDB7_TCSDisable "Traction Control System Driver Intent";
CM_ SG_ 301 IDB7_TCSFail "Traction Control System Fault";
CM_ SG_ 301 IDB7_ROPACTIVE "ARP激活";
CM_ SG_ 301 IDB7_ROPFailure "ARP失效";
CM_ SG_ 301 IDB7_AVHDispMSG "Auto Hold System Display Message";
CM_ SG_ 301 IDB7_AVHLampReq "Auto Hold System Lamp Request";
CM_ SG_ 301 IDB7_AVHStatus "Auto Hold System Status";
CM_ SG_ 301 IDB7_AVHEnabled "AVH功能使能";
CM_ SG_ 301 IDB7_DynParkBrkByIDBActive "Dynamic Parking Brake Activation by IDB";
CM_ SG_ 301 IDB7_DynParkBrkByIDBAvailable "Dynamic Parking Brake Available status by IDB";
CM_ SG_ 301 IDB7_HSAActive "坡道辅助";
CM_ SG_ 301 IDB7_HSAFail "坡道辅助故障";
CM_ SG_ 301 IDB7_HDCEnabled "HDC功能使能";
CM_ SG_ 301 IDB7_HDCFail "HDC功能失效";
CM_ SG_ 301 IDB7_HDCAtive "HDC激活";
CM_ SG_ 301 IDB7_ABSActive "Antilock Brake System Active";
CM_ SG_ 301 IDB7_ABSFail "Antilock Brake System Failed";
CM_ SG_ 301 IDB7_ESCFail "Electric Stability Control  Fault";
CM_ SG_ 301 IDB7_ESCActive "Electric Stability Control Active";
CM_ SG_ 301 IDB7_ESCDisable "Electric Stability Control Driver Intent
(ESC_DISABLED)";
CM_ SG_ 201 IDB10_MotrTrqFrntAxleTargtReq "Target torque value of front axle motor request";
CM_ SG_ 201 IDB10_MotrTrqRearAxleTargtReq "Target torque value of rear axle motor request";
CM_ SG_ 201 IDB10_MotrTrqFrntAxleTargt "Target torque value of front axle motor";
CM_ SG_ 201 IDB10_MotrTrqRearAxleTargt "Target torque value of rear axle motor";
CM_ SG_ 201 IDB10_ADAS_DrvTorque "Total regenerative braking torque of front axle";
CM_ SG_ 201 IDB10_ADAS_DrvTorqueReq "Total regenerative braking torque of front axle request";
CM_ SG_ 272 BDCS1_PowerMode "低压电源模式";
CM_ SG_ 272 BDCS1_PowerManageMode "低压电源管理模式";
CM_ SG_ 272 BDCS1_LowBeamSt "近光灯状态";
CM_ SG_ 272 BDCS1_HighBeamSt "远光灯状态";
CM_ SG_ 272 BDCS1_PositionLightSts "位置灯状态";
CM_ SG_ 272 BDCS1_BacklightStatus "整车背光灯状态";
CM_ SG_ 272 BDCS1_LeftTurnLightSt "左转向灯状态";
CM_ SG_ 272 BDCS1_RightTurnLightSt "右转向灯状态";
CM_ SG_ 272 BDCS1_FrontLampSt "前照灯开关";
CM_ SG_ 272 BDCS1_HazardLampSt "危险报警灯状态";
CM_ SG_ 272 BDCS1_HighBeamSW "远光灯开关状态";
CM_ SG_ 272 BDCS1_TurnLightSW "转向灯开关";
CM_ SG_ 272 BDCS1_HazardSwSt "危险报警灯开关状态";
CM_ SG_ 272 BDCS1_RearFogLampSt "后雾灯状态";
CM_ SG_ 272 BDCS1_FrontFogLampSt "前雾灯状态（预留）";
CM_ SG_ 272 BDCS1_TrunkLockSts "后背门锁状态（是否电动尾门，该信号均作为提示尾门是否开启）";
CM_ SG_ 272 BDCS1_HoodAjarSts "前舱盖开闭状态";
CM_ SG_ 272 BDCS1_MsgCounter "E2E Profile2-CRC8H2F，Counter：0-15";
CM_ SG_ 272 BDCS1_Checksum "E2E Profile2-CRC8H2F
DataID List:#60 - 174 124 106 58 47 154 237 220 98 37 173 212 59 125 101 188";
CM_ SG_ 274 BDCS3_RemoteAuthenSts "远程认证状态";
CM_ SG_ 274 BDCS3_BackDoorAjar "电动尾门位置状态";
CM_ SG_ 274 BDCS3_ADCSAuthenSts "与ADCS认证状态";
CM_ SG_ 276 CS1_HighBeamFlashReqSt "超车灯信号";
CM_ SG_ 276 CS1_FrontWiperMISTReqSt "前雨刮MIST请求状态";
CM_ SG_ 276 CS1_HighBeamReqSt "远光灯信号";
CM_ SG_ 276 CS1_TurnLightReqSt "转向灯";
CM_ SG_ 276 CS1_FrontWiperReqSt "前雨刮";
CM_ SG_ 276 CS1_FrontWiperWashReqSt "前洗涤";
CM_ SG_ 276 CS1_RearWiperReqSt_Reserved "后雨刮";
CM_ SG_ 276 CS1_RearWiperWashReqSt_Reserved "后洗涤";
CM_ SG_ 276 CS1_GearPositionReqSt "档位请求信号";
CM_ SG_ 276 CS1_GearPositionReqStInv "档位请求信号取反";
CM_ SG_ 276 CS1_GearPositionReqStValid "档位请求信号有效性";
CM_ SG_ 276 CS1_MsgCounter "E2E Profile2-CRC8H2F，Counter：0-15";
CM_ SG_ 276 CS1_Checksum "E2E Profile2-CRC8H2F
DataID List:#71 - 213 235 162 78 53 174 81 206 45 121 159 124 52 82 9 3";
CM_ SG_ 258 ACU1_Driver_Buckle "Driver Buckle status on CAN Bus
驾驶员安全带状态";
CM_ SG_ 258 ACU1_Passenger_Buckle "Passenger Buckle status on CAN Bus
副驾安全带状态";
CM_ SG_ 258 ACU1_Rear_Left_Buckle "Rear Left Buckle status on CAN Bus
后排左侧安全带状态";
CM_ SG_ 258 ACU1_Rear_Middle_Buckle "Rear Middle Buckle status on CAN Bus
后排中间安全带状态";
CM_ SG_ 258 ACU1_Rear_Right_Buckle "Rear Right Buckle status on CAN Bus
后排右侧安全带状态";
CM_ SG_ 258 ACU1_Passenger_ODS "Passenger ODS  status on CAN Bus
副驾占位传感器状态";
CM_ SG_ 258 ACU1_CrashStatus "Crash status on CAN Bus
碰撞信号";
CM_ SG_ 258 ACU1_warningLight "Airbag System Fault
安全气囊故障警报灯";
CM_ SG_ 196 ACU2_LatAccSensorValue "Lateral Acceleration Sensor Value";
CM_ SG_ 196 ACU2_LatAccSensorValueV "Lateral Acceleration Sensor Value Validity";
CM_ SG_ 196 ACU2_LongAccSensorValue "Longitude Acceleration Sensor Value";
CM_ SG_ 196 ACU2_LongAccSensorValueV "Longitude Acceleration Sensor Value Validity";
CM_ SG_ 196 ACU2_VehicleDynYawRate "Vehicle Dynamics Yaw Rate";
CM_ SG_ 196 ACU2_VehicleDynYawRateV "Vehicle Dynamics Yaw Rate Validity";
CM_ SG_ 196 ACU2_Sensorcalibration "组合传感器零位是否标定
Sensor calibration or not";
CM_ SG_ 196 ACU2_MsgCounter "E2E Profile2-CRC8H2F，Counter：0-15";
CM_ SG_ 196 ACU2_Checksum "E2E Profile2-CRC8H2F
DataID List:#26 - 39 175 13 15 49 40 145 209 184 197 98 107 118 202 100 99";
CM_ SG_ 805 ICU2_Odometer "仪表显示总计里程";
CM_ SG_ 305 ICU1_VehicleSpdDisplayValid "仪表显示车速有效性";
CM_ SG_ 305 ICU1_VehicleSpdDisplay "仪表显示车速";
CM_ SG_ 992 CalendarDay "Calendar Day";
CM_ SG_ 992 CalendarMonth "Calendar Month";
CM_ SG_ 992 CalendarYear "Calendar Year";
CM_ SG_ 992 HourOfDay "Hour Of Day";
CM_ SG_ 992 MinuteOfHour "Minute Of Hour";
CM_ SG_ 992 SecsOfMinute "Seconds Of Minute";
CM_ SG_ 992 TimeDspFmt "Time Display Format";
CM_ SG_ 528 ADCS9_AVM_MODdetectionSts "MOD状态";
CM_ SG_ 528 ADCS9_AVM_TransparentchassisSts "透明底盘状态";
CM_ SG_ 528 ADCS9_PA_FRS_Onoffset "反馈前雷达开关信号";
CM_ SG_ 528 ADCS9_AVM_Diaphaneity "透明度反馈";
CM_ SG_ 528 ADCS9_AVM_startMode "ADCS记忆设置";
CM_ SG_ 528 ADCS9_CDCS_CertificateState "PKI证书状态";
CM_ SG_ 528 ADCS9_AVM_LowSpeedBSDSts "低速BSD功能状态";
CM_ SG_ 528 ADCS9_AVM_SpeViewSts "特殊视角功能状态";
CM_ SG_ 528 ADCS9_AVM_3DRotateSts "3D旋转动画功能状态";
CM_ SG_ 528 ADCS9_AVM_TurnlightstartSts "转向灯开启全景功能状态";
CM_ SG_ 528 ADCS9_AVM_SteeringstartSts "转向角开启全景功能状态";
CM_ SG_ 528 ADCS9_AVM_MagnifiedviewSts "自动放大视角开关功能状态";
CM_ SG_ 528 ADCS9_AVM_auxiliarylineSts "辅助线功能状态";
CM_ SG_ 528 ADCS9_AVM_RaderdisplaySts "雷达显示功能状态";
CM_ SG_ 528 ADCS9_AVM_InitializationSts "初始化设置功能状态";
CM_ SG_ 528 ADCS9_AVM_bodySyncSts "车身信息同步功能状态";
CM_ SG_ 403 ADCS8_LDWMode "LDW模式";
CM_ SG_ 403 ADCS8_LDWWarnState "LDW报警状态";
CM_ SG_ 403 ADCS8_LDWState "LDW功能状态";
CM_ SG_ 403 ADCS8_ELKMode "ELK功能模式";
CM_ SG_ 403 ADCS8_LDPELKWarnState "LDPELK报警状态";
CM_ SG_ 403 ADCS8_LKSSetspeed "LKA激活速度反馈";
CM_ SG_ 403 ADCS8_LDPMode "LDP功能模式";
CM_ SG_ 403 ADCS8_lateralCtrHandsEyesOffWarning "Hands-off Warning Display";
CM_ SG_ 403 ADCS8_LDPELKtakeoverWarningstate "LDPELK接管报警状态";
CM_ SG_ 403 ADAS8_LateralCtrHandOffReleasewarning "HandOffReleasewarning";
CM_ SG_ 403 ADCS8_lateralCtrtakeover "驾驶员接管请求";
CM_ SG_ 403 ADCS8_ACCState "HMI显示";
CM_ SG_ 403 ADCS8_longitudCtrlTakeOverReq "ADAS纵向控制接管请求";
CM_ SG_ 403 ADCS8_longitudCtrlSetSpeed "设定速度";
CM_ SG_ 403 ADCS8_NNP_Scenarios "NNP所有场景显示提醒";
CM_ SG_ 403 ADCS8_longitudCtrlSetDistance "设定时距";
CM_ SG_ 403 ADCS8_longitudCtrlTargetValidity "是否有目标";
CM_ SG_ 403 ADCS8_ACCSystemFaultStatus "This signal means the ACC system health.";
CM_ SG_ 403 ADCS8_AEB_SystemFaultStatus "AEB状态";
CM_ SG_ 403 ADCS8_AEB_SystemStatus "This signal means indication of AEB On/Off Status";
CM_ SG_ 403 ADCS8_FCW_State "FCW开关状态反馈";
CM_ SG_ 403 ADCS8_FCWSensitiveLevel "FCW灵敏度反馈";
CM_ SG_ 403 ADCS8_FCWStatus "FCW报警状态";
CM_ SG_ 403 ADCS8_FCWSystemFaultStatus "FCW系统故障";
CM_ SG_ 403 ADCS8_FCTA_State "FCTA开关状态反馈";
CM_ SG_ 403 ADCS8_FCTALeftActiveSt "FCTA左报警状态";
CM_ SG_ 403 ADCS8_FCTARightActiveSt "FCTA右报警状态";
CM_ SG_ 403 ADCS8_FCTAWarnObjType "FCTA报警类型";
CM_ SG_ 403 ADCS8_FCTA_SystemFaultStatus "FCTA故障状态";
CM_ SG_ 403 ADCS8_RCTA_State "RCTA开关状态反馈";
CM_ SG_ 403 ADCS8_RCTALeftWarnSt "RCTA左报警状态";
CM_ SG_ 403 ADCS8_RCTARightWarnSt "RCTA右报警状态";
CM_ SG_ 403 ADCS8_RCTA_SystemFaultStatus "RCTA故障状态";
CM_ SG_ 403 ADCS8_RCW_State "RCW开关状态反馈";
CM_ SG_ 403 ADCS8_RCW_WarnState "RCW报警状态";
CM_ SG_ 403 ADCS8_RCW_SystemFaultStatus "RCW故障状态";
CM_ SG_ 403 ADCS8_DOWState "DOW开关状态反馈";
CM_ SG_ 403 ADCS8_DOWLeftWarnState "DOW Left报警状态（包括前后门）";
CM_ SG_ 403 ADCS8_DOWRightWarnState "DOW Right报警状态（包括前后门）";
CM_ SG_ 403 ADCS8_DOW_SystemFaultStatus "DOW故障状态";
CM_ SG_ 403 ADCS8_ADAS_IHBCStat "IHBC System Option Information";
CM_ SG_ 403 ADCS8_LCAState "LCA开关状态反馈";
CM_ SG_ 403 ADCS8_HornReq "请求喇叭响";
CM_ SG_ 403 ADCS8_DoorUnlock "ADCS解锁车门指令";
CM_ SG_ 403 ADCS8_LCARightWarnSt "LCA（BSD）右报警";
CM_ SG_ 403 ADCS8_LCALeftWarnSt "LCA（BSD）左报警";
CM_ SG_ 403 ADCS8_ACCOnOffState "ADCS巡航开关信号反馈";
CM_ SG_ 403 ADCS8_LCASystemFaultStatus "LCA故障状态";
CM_ SG_ 403 ADCS8_TSRState "TSR开关状态反馈";
CM_ SG_ 403 ADCS8_TSR_SpeedSign "TSR限速标志";
CM_ SG_ 403 ADCS8_TSR_SpeedWarnState "TSR限速报警";
CM_ SG_ 403 ADCS8_TSR_SLFStatefeedback "智能限速开关";
CM_ SG_ 403 ADCS8_NNP_SOAAudioplay "障碍避让语音提醒";
CM_ SG_ 403 ADCS8_TSR_ForbiddenSign "TSR禁止标志";
CM_ SG_ 403 ADCS8_PA_FPAS_SnsrObjWrnngZn_RSDW "侧翼保护报警区域信号";
CM_ SG_ 403 ADCS8_PA_FPAS_SnsrObjWrnngZn_LSDW "侧翼保护报警区域信号";
CM_ SG_ 403 ADCS8_PA_FPAS_SnsrObjWrnnglc_RSDW "侧翼保护报警位置信号";
CM_ SG_ 403 ADCS8_PA_FPAS_SnsrObjWrnnglc_LSDW "侧翼保护报警位置信号";
CM_ SG_ 403 ADCS8_TSR_LeftLightColor "TSR左转信号灯状态";
CM_ SG_ 403 ADCS8_TSR_RightLightColor "TSR右转信号灯状态";
CM_ SG_ 403 ADCS8_TSR_StrLightColor "TSR直行信号灯状态";
CM_ SG_ 403 ADCS8_TSR_SystemFaultStatus "TSR故障状态";
CM_ SG_ 403 ADCS8_NPilot_SysState "N-pilot System State";
CM_ SG_ 403 ADCS8_NPilot_SystemFaultStatus "N-Pilot故障状态";
CM_ SG_ 403 ADCS8_VoiceNotifFrequency_mode "导航播报模式反馈";
CM_ SG_ 403 ADCS8_NNPSysState "NNP系统状态";
CM_ SG_ 403 ADCS8_NNP_SystemFaultStatus "NNP故障状态";
CM_ SG_ 403 ADCS8_NNP_AutoOnOffSet "NNP自动开启开关（NNP设置项）";
CM_ SG_ 403 ADCS8_DCLCSysState "DCLC开关状态";
CM_ SG_ 403 ADCS8_Lanechangeinfor "Lane change 提醒";
CM_ SG_ 403 ADCS8_LaneChangeWarning "变道危险报警（仪表显示）";
CM_ SG_ 403 ADCS8_LaneChangeSystemFaultStatus "变道功能故障";
CM_ SG_ 403 ADCS8_GMState "哨兵模式开关状态反馈";
CM_ SG_ 403 ADCS8_GMWarnState "哨兵模式报警";
CM_ SG_ 403 ADCS8_GMWorkState "哨兵模式工作状态";
CM_ SG_ 403 ADCS8_ADAS_DriveOffPossilbe "前车起步提醒";
CM_ SG_ 403 ADCS8_DriveOffinhibitionObjType "起步抑制的目标类型";
CM_ SG_ 403 ADCS8_FRS_Fail "前雷达故障";
CM_ SG_ 403 ADCS8_SRR_FL_Fail "角雷达故障（FL）";
CM_ SG_ 403 ADCS8_SRR_FR_Fail "角雷达故障（FR）";
CM_ SG_ 403 ADCS8_SRR_RL_Fail "角雷达故障（RL）";
CM_ SG_ 403 ADCS8_SRR_RR_Fail "角雷达故障（RR）";
CM_ SG_ 403 ADCS8_FVC_120_Fail "120°前视摄像头故障";
CM_ SG_ 403 ADCS8_FVC_30_Fail "30°前视摄像头故障";
CM_ SG_ 403 ADCS8_SVC_FL_Fail "侧视摄像头故障（FL）";
CM_ SG_ 403 ADCS8_SVC_FR_Fail "侧视摄像头故障（FR）";
CM_ SG_ 403 ADCS8_SVC_RL_Fail "侧视摄像头故障（RL）";
CM_ SG_ 403 ADCS8_SVC_RR_Fail "侧视摄像头故障（RR）";
CM_ SG_ 403 ADCS8_RVC_Fail "后视摄像头故障";
CM_ SG_ 403 ADCS8_TSR_OverspeedOnOffSet "超速报警开关";
CM_ SG_ 403 ADCS8_Lanechangedirection "变道方向提示";
CM_ SG_ 403 ADCS8_VoiceMode "语音播报模式";
CM_ SG_ 403 ADCS8_ALC_mode "自动变道设置反馈";
CM_ SG_ 403 ADCS8_NNP_State "NNP总开关状态反馈";
CM_ SG_ 403 ADCS8_ADSDriving_mode "自动驾驶风格选项设置反馈";
CM_ SG_ 403 ADCS8_NNP_MRM_status "NNP_MRM（靠边停车）报警";
CM_ SG_ 403 ADCS8_GM_SystemFaultStatus "哪吒卫士故障，增加CDCS、ICU、GW_FD4接收
0x5~0x7 Reserved";
CM_ SG_ 403 ADCS8_SystemFault "ADAS系统故障指示";
CM_ SG_ 403 ADCS8_LeftLidarFault "左激光雷达故障";
CM_ SG_ 403 ADCS8_RightlidarFault "右激光雷达故障";
CM_ SG_ 403 ADCS8_AVMFrontCAMFault "前环视摄像头故障";
CM_ SG_ 403 ADCS8_AVMLeftCAMFault "左环视摄像头故障";
CM_ SG_ 403 ADCS8_AVMRightCAMFault "右环视摄像头故障";
CM_ SG_ 403 ADCS8_AVMRearCAMFault "后环视摄像头故障";
CM_ SG_ 404 ADCS8_RPA_CheckListDispReq1 "自检条目清单中四门两盖状态";
CM_ SG_ 404 ADCS8_RPA_CheckListDispReq2 "自检条目清单中车速状态";
CM_ SG_ 404 ADCS8_RPA_CheckListDispReq3 "自检条目清单中档位状态";
CM_ SG_ 404 ADCS8_RPA_CheckListDispReq4 "自检条目清单中EPB状态";
CM_ SG_ 404 ADCS8_RPA_CheckListDispReq5 "自检条目清单中胎压状态";
CM_ SG_ 404 ADCS8_RPA_CheckListDispReq6 "自检条目清单中坡度状态";
CM_ SG_ 404 ADCS8_PA_warninginfo "RPA发送工作状态提示信息";
CM_ SG_ 404 ADCS8_RPA_CheckListDispReq7 "自检条目清单中RPA系统故障状态";
CM_ SG_ 404 ADCS8_RPA_CheckListDispReq8 "自检条目清单中关联系统故障状态";
CM_ SG_ 404 ADCS8_PA_FPAS_SnsrObjWrnngZn_FLC "左前目标障碍物报警区域";
CM_ SG_ 404 ADCS8_PA_FPAS_SnsrObjWrnngZn_FLM "左前中目标障碍物报警区域";
CM_ SG_ 404 ADCS8_PA_FPAS_SnsrObjWrnngZn_FRM "右前中目标障碍物报警区域";
CM_ SG_ 404 ADCS8_PA_FPAS_SnsrObjWrnngZn_FRC "右前目标障碍物报警区域";
CM_ SG_ 404 ADCS8_PA_FPAS_SnsrObjWrnngZn_RLC "左后目标障碍物报警区域";
CM_ SG_ 404 ADCS8_PA_FPAS_SnsrObjWrnngZn_RLM "左后中目标障碍物报警区域";
CM_ SG_ 404 ADCS8_PA_FPAS_SnsrObjWrnngZn_RRM "右后中目标障碍物报警区域";
CM_ SG_ 404 ADCS8_PA_FPAS_SnsrObjWrnngZn_RRC "右后目标障碍物报警区域";
CM_ SG_ 404 ADCS8_PA_FPAS_SnsrObjWrnngZn_SFL "左前侧目标障碍物报警区域";
CM_ SG_ 404 ADCS8_PA_FPAS_SnsrObjWrnngZn_SFR "右前侧目标障碍物报警区域";
CM_ SG_ 404 ADCS8_PA_FPAS_SnsrObjWrnngZn_SRL "左后侧目标障碍物报警区域";
CM_ SG_ 404 ADCS8_PA_FPAS_SnsrObjWrnngZn_SRR "右后侧目标障碍物报警区域";
CM_ SG_ 404 ADCS8_PA_FPAS_SnsrDist_FLC "左前超声波传感器障碍物距离";
CM_ SG_ 404 ADCS8_PA_FPAS_SnsrDist_FLM "左前中超声波传感器障碍物距离";
CM_ SG_ 404 ADCS8_PA_FPAS_SnsrDist_FRM "右前中超声波传感器障碍物距离";
CM_ SG_ 404 ADCS8_PA_FPAS_SnsrDist_FRC "右前超声波传感器障碍物距离";
CM_ SG_ 404 ADCS8_PA_FPAS_SnsrDist_RLC "左后超声波传感器障碍物距离";
CM_ SG_ 404 ADCS8_PA_FPAS_SnsrDist_RLM "左后中超声波传感器障碍物距离";
CM_ SG_ 404 ADCS8_PA_FPAS_SnsrDist_RRM "右后中超声波传感器障碍物距离";
CM_ SG_ 404 ADCS8_PA_FPAS_SnsrDist_RRC "右后超声波传感器障碍物距离";
CM_ SG_ 404 ADCS8_PA_FPAS_SnsrDist_SFL "左前侧超声波传感器障碍物距离";
CM_ SG_ 404 ADCS8_PA_FPAS_SnsrDist_SFR "右前侧超声波传感器障碍物距离";
CM_ SG_ 404 ADCS8_PA_FPAS_SnsrDist_SRL "左后侧超声波传感器障碍物距离";
CM_ SG_ 404 ADCS8_PA_FPAS_SnsrDist_SRR "右后侧超声波传感器障碍物距离";
CM_ SG_ 404 ADCS8_PA_FPAS_WorkSts "前超声波工作状态";
CM_ SG_ 404 ADCS8_PA_RPAS_WorkSts "后超声波工作状态";
CM_ SG_ 404 ADCS8_PA_FPAS_SensorFaultStsFLC "左前超声波传感器故障";
CM_ SG_ 404 ADCS8_PA_FPAS_SensorFaultStsFLM "左前中超声波传感器故障";
CM_ SG_ 404 ADCS8_PA_FPAS_SensorFaultStsFRM "右前中超声波传感器故障";
CM_ SG_ 404 ADCS8_PA_FPAS_SensorFaultStsFRC "右前超声波传感器故障";
CM_ SG_ 404 ADCS8_PA_RPAS_SensorFaultStsRLC "左后超声波传感器故障";
CM_ SG_ 404 ADCS8_PA_RPAS_SensorFaultStsRLM "左后中超声波传感器故障";
CM_ SG_ 404 ADCS8_PA_RPAS_SensorFaultStsRRM "右后中超声波传感器故障";
CM_ SG_ 404 ADCS8_PA_RPAS_SensorFaultStsRRC "右后超声波传感器故障";
CM_ SG_ 404 ADCS8_PA_FPAS_SensorFaultStsSFL "左前侧超声波传感器故障";
CM_ SG_ 404 ADCS8_PA_FPAS_SensorFaultStsSFR "右前侧超声波传感器故障";
CM_ SG_ 404 ADCS8_PA_RPAS_SensorFaultStsSRL "左后侧超声波传感器故障";
CM_ SG_ 404 ADCS8_PA_RPAS_SensorFaultStsSRR "右后侧超声波传感器故障";
CM_ SG_ 404 ADCS8_AudBpRate_R "后雷达声音报警频率";
CM_ SG_ 404 ADCS8_AudBpRate_F "前雷达声音报警频率";
CM_ SG_ 404 ADCS8_AVM_RomoteAVMFeedBack "AVM远程启动状态反馈";
CM_ SG_ 404 ADCS8_AVM_MODWarning "MOD报警音";
CM_ SG_ 402 ADCS7_RPA_slot_ID_7_P0_X "RPA给APP的P0点横坐标7";
CM_ SG_ 402 ADCS7_RPA_slot_ID_7_P0_Y "RPA给APP的P0点纵坐标7";
CM_ SG_ 402 ADCS7_RPA_slot_ID_7_P1_X "RPA给APP的P1点横坐标7";
CM_ SG_ 402 ADCS7_RPA_slot_ID_7_P1_Y "RPA给APP的P1点纵坐标7";
CM_ SG_ 402 ADCS7_RPA_slot_ID_7_P2_X "RPA给APP的P2点横坐标7";
CM_ SG_ 402 ADCS7_RPA_slot_ID_7_P2_Y "RPA给APP的P2点纵坐标7";
CM_ SG_ 402 ADCS7_RPA_slot_ID_7_P3_X "RPA给APP的P3点横坐标7";
CM_ SG_ 402 ADCS7_RPA_slot_ID_7_P3_Y "RPA给APP的P3点纵坐标7";
CM_ SG_ 402 ADCS7_RPA_slot_Angle7 "RPA给APP角度7";
CM_ SG_ 402 ADCS7_RPA_ParkingSlotDirection7 "RPA给APP方向7";
CM_ SG_ 402 ADCS7_RPA_ParkingSlotType7 "RPA给APP类型7";
CM_ SG_ 402 ADCS7_RPA_ParkingSlotDepth7 "RPA给APP深度7";
CM_ SG_ 402 ADCS7_RPA_ParkingSlotWidth7 "RPA给APP宽度7";
CM_ SG_ 402 ADCS7_RPA_slot_ID_8_P0_X "RPA给APP的P0点横坐标8";
CM_ SG_ 402 ADCS7_RPA_slot_ID_8_P0_Y "RPA给APP的P0点纵坐标8";
CM_ SG_ 402 ADCS7_RPA_slot_ID_8_P1_X "RPA给APP的P1点横坐标8";
CM_ SG_ 402 ADCS7_RPA_slot_ID_8_P1_Y "RPA给APP的P1点纵坐标8";
CM_ SG_ 402 ADCS7_RPA_slot_ID_8_P2_X "RPA给APP的P2点横坐标8";
CM_ SG_ 402 ADCS7_RPA_slot_ID_8_P2_Y "RPA给APP的P2点纵坐标8";
CM_ SG_ 402 ADCS7_RPA_slot_ID_8_P3_X "RPA给APP的P3点横坐标8";
CM_ SG_ 402 ADCS7_RPA_slot_ID_8_P3_Y "RPA给APP的P3点纵坐标8";
CM_ SG_ 402 ADCS7_RPA_slot_Angle8 "RPA给APP角度8";
CM_ SG_ 402 ADCS7_RPA_ParkingSlotDirection8 "RPA给APP方向8";
CM_ SG_ 402 ADCS7_RPA_ParkingSlotType8 "RPA给APP类型8";
CM_ SG_ 402 ADCS7_RPA_ParkingSlotDepth8 "RPA给APP深度8";
CM_ SG_ 402 ADCS7_RPA_ParkingSlotWidth8 "RPA给APP宽度8";
CM_ SG_ 402 ADCS7_PA_ObsDist_F "RPA发送距离车辆前方最近的障碍物距离信息";
CM_ SG_ 402 ADCS7_PA_ObsDist_R "RPA发送距离车辆后方最近的障碍物距离信息";
CM_ SG_ 402 ADCS7_RPA_ObsArea "RPA发送障碍物区域信息";
CM_ SG_ 402 ADCS7_RPA_ObsDist "RPA发送距离车辆最近的障碍物距离信息";
CM_ SG_ 402 ADCS7_RPA_slot_ID_7_Status "车位ID7状态";
CM_ SG_ 402 ADCS7_RPA_slot_ID_8_Status "车位ID8状态";
CM_ SG_ 401 ADCS6_RPA_slot_ID_4_P0_X "RPA给APP的P0点横坐标4";
CM_ SG_ 401 ADCS6_RPA_slot_ID_4_P0_Y "RPA给APP的P0点纵坐标4";
CM_ SG_ 401 ADCS6_RPA_slot_ID_4_P1_X "RPA给APP的P1点横坐标4";
CM_ SG_ 401 ADCS6_RPA_slot_ID_4_P1_Y "RPA给APP的P1点纵坐标4";
CM_ SG_ 401 ADCS6_RPA_slot_ID_4_P2_X "RPA给APP的P2点横坐标4";
CM_ SG_ 401 ADCS6_RPA_slot_ID_4_P2_Y "RPA给APP的P2点纵坐标4";
CM_ SG_ 401 ADCS6_RPA_slot_ID_4_P3_X "RPA给APP的P3点横坐标4";
CM_ SG_ 401 ADCS6_RPA_slot_ID_4_P3_Y "RPA给APP的P3点纵坐标4";
CM_ SG_ 401 ADCS6_RPA_slot_Angle4 "RPA给APP角度4";
CM_ SG_ 401 ADCS6_RPA_ParkingSlotDirection4 "RPA给APP方向4";
CM_ SG_ 401 ADCS6_RPA_slot_ID_4_Status "车位ID4状态";
CM_ SG_ 401 ADCS6_RPA_slot_ID_5_Status "车位ID5状态";
CM_ SG_ 401 ADCS6_RPA_ParkingSlotType4 "RPA给APP类型4";
CM_ SG_ 401 ADCS6_RPA_ParkingSlotDepth4 "RPA给APP深度4";
CM_ SG_ 401 ADCS6_RPA_ParkingSlotWidth4 "RPA给APP宽度4";
CM_ SG_ 401 ADCS6_RPA_slot_ID_5_P0_X "RPA给APP的P0点横坐标5";
CM_ SG_ 401 ADCS6_RPA_slot_ID_5_P0_Y "RPA给APP的P0点纵坐标5";
CM_ SG_ 401 ADCS6_RPA_slot_ID_5_P1_X "RPA给APP的P1点横坐标5";
CM_ SG_ 401 ADCS6_RPA_slot_ID_5_P1_Y "RPA给APP的P1点纵坐标5";
CM_ SG_ 401 ADCS6_RPA_slot_ID_5_P2_X "RPA给APP的P2点横坐标5";
CM_ SG_ 401 ADCS6_RPA_slot_ID_5_P2_Y "RPA给APP的P2点纵坐标5";
CM_ SG_ 401 ADCS6_RPA_slot_ID_5_P3_X "RPA给APP的P3点横坐标5";
CM_ SG_ 401 ADCS6_RPA_slot_ID_5_P3_Y "RPA给APP的P3点纵坐标5";
CM_ SG_ 401 ADCS6_RPA_slot_Angle5 "RPA给APP角度5";
CM_ SG_ 401 ADCS6_RPA_ParkingSlotDirection5 "RPA给APP方向5";
CM_ SG_ 401 ADCS6_RPA_ParkingSlotType5 "RPA给APP类型5";
CM_ SG_ 401 ADCS6_RPA_ParkingSlotDepth5 "RPA给APP深度5";
CM_ SG_ 401 ADCS6_RPA_ParkingSlotWidth5 "RPA给APP宽度5";
CM_ SG_ 401 ADCS6_RPA_slot_ID_6_P0_X "RPA给APP的P0点横坐标6";
CM_ SG_ 401 ADCS6_RPA_slot_ID_6_P0_Y "RPA给APP的P0点纵坐标6";
CM_ SG_ 401 ADCS6_RPA_slot_ID_6_P1_X "RPA给APP的P1点横坐标6";
CM_ SG_ 401 ADCS6_RPA_slot_ID_6_P1_Y "RPA给APP的P1点纵坐标6";
CM_ SG_ 401 ADCS6_RPA_slot_ID_6_P2_X "RPA给APP的P2点横坐标6";
CM_ SG_ 401 ADCS6_RPA_slot_ID_6_P2_Y "RPA给APP的P2点纵坐标6";
CM_ SG_ 401 ADCS6_RPA_slot_ID_6_P3_X "RPA给APP的P3点横坐标6";
CM_ SG_ 401 ADCS6_RPA_slot_ID_6_P3_Y "RPA给APP的P3点纵坐标6";
CM_ SG_ 401 ADCS6_RPA_slot_Angle6 "RPA给APP角度6";
CM_ SG_ 401 ADCS6_RPA_ParkingSlotDirection6 "RPA给APP方向6";
CM_ SG_ 401 ADCS6_RPA_ParkingSlotType6 "RPA给APP类型6";
CM_ SG_ 401 ADCS6_RPA_ParkingSlotDepth6 "RPA给APP深度6";
CM_ SG_ 401 ADCS6_RPA_ParkingSlotWidth6 "RPA给APP宽度6";
CM_ SG_ 401 ADCS6_RPA_slot_ID_6_Status "车位ID6状态";
CM_ SG_ 400 ADCS5_RPA_slot_ID_1_P0_X "RPA给APP的P0点横坐标1";
CM_ SG_ 400 ADCS5_RPA_slot_ID_1_P0_Y "RPA给APP的P0点纵坐标1";
CM_ SG_ 400 ADCS5_RPA_slot_ID_1_P1_X "RPA给APP的P1点横坐标1";
CM_ SG_ 400 ADCS5_RPA_slot_ID_1_P1_Y "RPA给APP的P1点纵坐标1";
CM_ SG_ 400 ADCS5_RPA_slot_ID_1_P2_X "RPA给APP的P2点横坐标1";
CM_ SG_ 400 ADCS5_RPA_slot_ID_1_P2_Y "RPA给APP的P2点纵坐标1";
CM_ SG_ 400 ADCS5_RPA_slot_ID_1_P3_X "RPA给APP的P3点横坐标1";
CM_ SG_ 400 ADCS5_RPA_slot_ID_1_P3_Y "RPA给APP的P3点纵坐标1";
CM_ SG_ 400 ADCS5_RPA_slot_Angle1 "RPA给APP角度1";
CM_ SG_ 400 ADCS5_RPA_slot_ID_1_Status "车位ID1状态";
CM_ SG_ 400 ADCS5_RPA_slot_ID_2_Status "车位ID2状态";
CM_ SG_ 400 ADCS5_RPA_slot_ID_3_Status "车位ID3状态";
CM_ SG_ 400 ADCS5_RPA_ParkingSlotDirection1 "RPA给APP方向1";
CM_ SG_ 400 ADCS5_RPA_ParkingSlotType1 "RPA给APP类型1";
CM_ SG_ 400 ADCS5_RPA_ParkingSlotDepth1 "RPA给APP深度1";
CM_ SG_ 400 ADCS5_RPA_ParkingSlotWidth1 "RPA给APP宽度1";
CM_ SG_ 400 ADCS5_RPA_slot_ID_2_P0_X "RPA给APP的P0点横坐标2";
CM_ SG_ 400 ADCS5_RPA_slot_ID_2_P0_Y "RPA给APP的P0点纵坐标2";
CM_ SG_ 400 ADCS5_RPA_slot_ID_2_P1_X "RPA给APP的P1点横坐标2";
CM_ SG_ 400 ADCS5_RPA_slot_ID_2_P1_Y "RPA给APP的P1点纵坐标2";
CM_ SG_ 400 ADCS5_RPA_slot_ID_2_P2_X "RPA给APP的P2点横坐标2";
CM_ SG_ 400 ADCS5_RPA_slot_ID_2_P2_Y "RPA给APP的P2点纵坐标2";
CM_ SG_ 400 ADCS5_RPA_slot_ID_2_P3_X "RPA给APP的P3点横坐标2";
CM_ SG_ 400 ADCS5_RPA_slot_ID_2_P3_Y "RPA给APP的P3点纵坐标2";
CM_ SG_ 400 ADCS5_RPA_slot_Angle2 "RPA给APP角度2";
CM_ SG_ 400 ADCS5_RPA_ParkingSlotDirection2 "RPA给APP方向2";
CM_ SG_ 400 ADCS5_RPA_ParkingSlotType2 "RPA给APP类型2";
CM_ SG_ 400 ADCS5_RPA_ParkingSlotDepth2 "RPA给APP深度2";
CM_ SG_ 400 ADCS5_RPA_ParkingSlotWidth2 "RPA给APP宽度2";
CM_ SG_ 400 ADCS5_RPA_slot_ID_3_P0_X "RPA给APP的P0点横坐标3";
CM_ SG_ 400 ADCS5_RPA_slot_ID_3_P0_Y "RPA给APP的P0点纵坐标3";
CM_ SG_ 400 ADCS5_RPA_slot_ID_3_P1_X "RPA给APP的P1点横坐标3";
CM_ SG_ 400 ADCS5_RPA_slot_ID_3_P1_Y "RPA给APP的P1点纵坐标3";
CM_ SG_ 400 ADCS5_RPA_slot_ID_3_P2_X "RPA给APP的P2点横坐标3";
CM_ SG_ 400 ADCS5_RPA_slot_ID_3_P2_Y "RPA给APP的P2点纵坐标3";
CM_ SG_ 400 ADCS5_RPA_slot_ID_3_P3_X "RPA给APP的P3点横坐标3";
CM_ SG_ 400 ADCS5_RPA_slot_ID_3_P3_Y "RPA给APP的P3点纵坐标3";
CM_ SG_ 400 ADCS5_RPA_slot_Angle3 "RPA给APP角度3";
CM_ SG_ 400 ADCS5_RPA_ParkingSlotDirection3 "RPA给APP方向3";
CM_ SG_ 400 ADCS5_RPA_ParkingSlotType3 "RPA给APP类型3";
CM_ SG_ 400 ADCS5_RPA_ParkingSlotDepth3 "RPA给APP深度3";
CM_ SG_ 400 ADCS5_RPA_ParkingSlotWidth3 "RPA给APP宽度3";
CM_ SG_ 254 ADCS_AVM_RCW_warningReq "车辆后方报警信号";
CM_ SG_ 254 ADCS4_AVM_BSD_warningReqLeft "BSD左侧报警信号";
CM_ SG_ 254 ADCS4_AVM_BSD_warningReqRight "BSD右侧报警信号";
CM_ SG_ 254 ADCS4_PA_SysSoundIndication "APA系统声音提示";
CM_ SG_ 254 ADCS4_PA_Sound_Location "障碍物位置提示信息";
CM_ SG_ 254 ADCS4_AVM_vedioReq "AVM启动反馈信号";
CM_ SG_ 254 ADCS4_AVM_Sts "AVM系统状态";
CM_ SG_ 254 ADCS4_RPA_RemoteParkFinishReq "泊车结束请求";
CM_ SG_ 254 ADCS4_AVM_BSD_SysSts "BSD系统状态信号";
CM_ SG_ 254 ADCS4_PA_InfoDisplayReq "APA请求IHU显示APA进入失败原因";
CM_ SG_ 254 ADCS4_PA_failinfo "上电故障，开关置灰";
CM_ SG_ 254 ADCS4_UPA_Sound_Location "UPA声音报警对应车上扬声器位置发声";
CM_ SG_ 254 ADCS4_HPA_failinfo "记忆泊车路线学习过程中出错，退出原因播报";
CM_ SG_ 254 ADCS4_UPA_SysSoundIndication "UPA系统声音提示";
CM_ SG_ 254 ADCS4_AVM_SysSoundIndication "系统声音指示";
CM_ SG_ 254 ADCS4_PA_ParkBarPercent "泊车进程";
CM_ SG_ 254 ADCS4_MsgCounter0 "E2E Profile2-CRC8H2F，Counter：0-15";
CM_ SG_ 254 ADCS4_Checksum0 "E2E Profile2-CRC8H2F
DataID List:#16 - 149 178 48 27 29 185 17 203 148 68 204 36 101 195 44 16";
CM_ SG_ 254 ADCS4_APA_FunctionMode "APA功能模式反馈信号";
CM_ SG_ 254 ADCS4_Text "文字提示信息";
CM_ SG_ 254 ADCS4_ParkingswithReq "自动泊车软开关显示请求";
CM_ SG_ 254 ADCS4_Slotavaliable "自选车位是否可用";
CM_ SG_ 254 ADCS4_locationSt "当前定位状态";
CM_ SG_ 254 ADCS4_PA_GuideLineE_a "泊车引导线方程y=ax3+bx2+cx+d";
CM_ SG_ 254 ADCS4_PA_GuideLineE_b "泊车引导线方程y=ax3+bx2+cx+d";
CM_ SG_ 254 ADCS4_PA_GuideLineE_c "泊车引导线方程y=ax3+bx2+cx+d";
CM_ SG_ 254 ADCS4_PA_GuideLineE_d "泊车引导线方程y=ax3+bx2+cx+d";
CM_ SG_ 254 ADCS4_PA_GuideLineE_Xmin "泊车引导线方程y=ax3+bx2+cx+d";
CM_ SG_ 254 ADCS4_PA_GuideLineE_Xmax "泊车引导线方程y=ax3+bx2+cx+d";
CM_ SG_ 254 ADCS4_ParkingTime "泊车计时";
CM_ SG_ 254 ADCS4_HPA_FunctionMode "记忆泊车模式";
CM_ SG_ 254 ADCS4_HPAWarningInfo "记忆泊车警报信息";
CM_ SG_ 254 ADCS4_HPA_deleteMapSt "记忆泊车删除路线状态";
CM_ SG_ 254 ADCS4_HPA_uploadMapSt "记忆泊车上传路线状态";
CM_ SG_ 254 ADCS4_NNS_FunctionMode "智能召唤状态";
CM_ SG_ 254 ADCS4_FindCarAvmStatus "智能寻车状态";
CM_ SG_ 254 ADCS4_HourOfDay "目标到达时间显示";
CM_ SG_ 254 ADCS4_MinuteOfHour "目标到达时间显示";
CM_ SG_ 254 ADCS4_SecondOfMinute "目标到达时间显示";
CM_ SG_ 254 ADCS4_TractionswithReq "循迹倒车开始信息";
CM_ SG_ 254 ADCS4_RPA_FunctionMode "反馈泊车模式信号";
CM_ SG_ 254 ADCS4_DCWposition "新增反馈开门预警设置信号";
CM_ SG_ 254 ADCS4_DCWlevel "新增开门预警报警级别信号";

BA_DEF_ BU_ "NmCAN" INT 1 2;
BA_DEF_ BU_ "NodeLayerModules" STRING ;
BA_DEF_ BU_ "ILUsed" ENUM "No","Yes";
BA_DEF_ "Baudrate" INT 0 10000000;
BA_DEF_ "NmMessageCount" INT 0 255;
BA_DEF_ "NmBaseAddress" HEX 0 2047;
BA_DEF_ "BusType" STRING ;
BA_DEF_ "VersionYear" INT 2010 2999;
BA_DEF_ "DBName" STRING ;
BA_DEF_ "NmType" STRING ;
BA_DEF_ SG_ "GenSigSendType" ENUM "Cycle","OnChange","OnWrite","IfActive","OnChangeWithRepetition","OnWriteWithRepetition","IfActiveWithRepetition","NoSigSendType","OnChangeAndIfActive","OnChangeAndIfActiveWithRepetition","CA","CE","Event","Cyclic";
BA_DEF_ SG_ "GenSigInactiveValue" HEX 0 0;
BA_DEF_ SG_ "GenSigStartValue" HEX 0 0;
BA_DEF_ SG_ "GenSigInvalidValue" HEX 0 0;
BA_DEF_ BO_ "CANFD_BRS" ENUM "0","1";
BA_DEF_ BO_ "GenMsgCycleTimeFast" INT 0 0;
BA_DEF_ BO_ "GenMsgSendType" ENUM "Cycle","NoMsgSendType","IfActive","Event","CA","CE","Cyclic";
BA_DEF_ BO_ "GenMsgNrOfRepetition" INT 0 0;
BA_DEF_ BO_ "GenMsgStartDelayTime" INT 0 0;
BA_DEF_ BO_ "GenMsgCycleTime" INT 0 0;
BA_DEF_ BO_ "GenMsgDelayTime" INT 0 0;
BA_DEF_ BO_ "NmMessage" ENUM "No","Yes";
BA_DEF_ BO_ "GenMsgILSupport" ENUM "No","Yes";
BA_DEF_ BO_ "VFrameFormat" ENUM "StandardCAN","ExtendedCAN","reserved","reserved","reserved","reserved","reserved","reserved","reserved","reserved","reserved","reserved","reserved","reserved","StandardCAN_FD","ExtendedCAN_FD";
BA_DEF_DEF_ "NmCAN" 2;
BA_DEF_DEF_ "NodeLayerModules" "OSEKNM01.dll,CANoeILNLVector.dll";
BA_DEF_DEF_ "ILUsed" "Yes";
BA_DEF_DEF_ "Baudrate" 2000000;
BA_DEF_DEF_ "NmMessageCount" 128;
BA_DEF_DEF_ "NmBaseAddress" 1536;
BA_DEF_DEF_ "BusType" "CAN";
BA_DEF_DEF_ "VersionYear" 2019;
BA_DEF_DEF_ "DBName" "";
BA_DEF_DEF_ "NmType" "OSEK";
BA_DEF_DEF_ "GenSigSendType" "Cycle";
BA_DEF_DEF_ "GenSigInactiveValue" 0;
BA_DEF_DEF_ "GenSigStartValue" 0;
BA_DEF_DEF_ "GenSigInvalidValue" 0;
BA_DEF_DEF_ "CANFD_BRS" "1";
BA_DEF_DEF_ "GenMsgCycleTimeFast" 0;
BA_DEF_DEF_ "GenMsgSendType" "Cycle";
BA_DEF_DEF_ "GenMsgNrOfRepetition" 0;
BA_DEF_DEF_ "GenMsgStartDelayTime" 0;
BA_DEF_DEF_ "GenMsgCycleTime" 100;
BA_DEF_DEF_ "GenMsgDelayTime" 0;
BA_DEF_DEF_ "NmMessage" "No";
BA_DEF_DEF_ "GenMsgILSupport" "Yes";
BA_DEF_DEF_ "VFrameFormat" "StandardCAN";
BA_ "BusType" "CAN FD";
BA_ "DBName" "EP40_CANFD_Matrix_OTS2_V5.2_ADCS_FD3";
BA_ "GenMsgCycleTime" BO_ 984 0;
BA_ "GenMsgSendType" BO_ 984 2;
BA_ "VFrameFormat" BO_ 984 14;
BA_ "GenMsgCycleTime" BO_ 983 0;
BA_ "GenMsgSendType" BO_ 983 2;
BA_ "VFrameFormat" BO_ 983 14;
BA_ "GenMsgCycleTime" BO_ 515 50;
BA_ "VFrameFormat" BO_ 515 14;
BA_ "VFrameFormat" BO_ 597 14;
BA_ "VFrameFormat" BO_ 579 14;
BA_ "GenMsgCycleTime" BO_ 170 10;
BA_ "VFrameFormat" BO_ 170 14;
BA_ "GenMsgCycleTime" BO_ 171 10;
BA_ "VFrameFormat" BO_ 171 14;
BA_ "GenMsgCycleTime" BO_ 177 10;
BA_ "VFrameFormat" BO_ 177 14;
BA_ "GenMsgCycleTime" BO_ 178 10;
BA_ "VFrameFormat" BO_ 178 14;
BA_ "GenMsgCycleTime" BO_ 229 10;
BA_ "VFrameFormat" BO_ 229 14;
BA_ "GenMsgCycleTime" BO_ 192 10;
BA_ "VFrameFormat" BO_ 192 14;
BA_ "GenMsgCycleTime" BO_ 197 10;
BA_ "VFrameFormat" BO_ 197 14;
BA_ "GenMsgCycleTime" BO_ 199 10;
BA_ "VFrameFormat" BO_ 199 14;
BA_ "GenMsgCycleTime" BO_ 289 20;
BA_ "VFrameFormat" BO_ 289 14;
BA_ "GenMsgCycleTime" BO_ 297 20;
BA_ "VFrameFormat" BO_ 297 14;
BA_ "GenMsgCycleTime" BO_ 299 20;
BA_ "VFrameFormat" BO_ 299 14;
BA_ "GenMsgCycleTime" BO_ 301 20;
BA_ "VFrameFormat" BO_ 301 14;
BA_ "GenMsgCycleTime" BO_ 201 10;
BA_ "VFrameFormat" BO_ 201 14;
BA_ "GenMsgCycleTime" BO_ 272 20;
BA_ "VFrameFormat" BO_ 272 14;
BA_ "GenMsgCycleTime" BO_ 274 20;
BA_ "VFrameFormat" BO_ 274 14;
BA_ "GenMsgCycleTime" BO_ 276 20;
BA_ "VFrameFormat" BO_ 276 14;
BA_ "GenMsgCycleTime" BO_ 258 20;
BA_ "VFrameFormat" BO_ 258 14;
BA_ "GenMsgCycleTime" BO_ 196 10;
BA_ "VFrameFormat" BO_ 196 14;
BA_ "GenMsgCycleTime" BO_ 805 500;
BA_ "VFrameFormat" BO_ 805 14;
BA_ "GenMsgCycleTime" BO_ 305 20;
BA_ "VFrameFormat" BO_ 305 14;
BA_ "GenMsgCycleTime" BO_ 992 1000;
BA_ "VFrameFormat" BO_ 992 14;
BA_ "VFrameFormat" BO_ 528 14;
BA_ "GenMsgCycleTime" BO_ 403 50;
BA_ "VFrameFormat" BO_ 403 14;
BA_ "GenMsgCycleTime" BO_ 404 50;
BA_ "VFrameFormat" BO_ 404 14;
BA_ "GenMsgCycleTime" BO_ 402 50;
BA_ "VFrameFormat" BO_ 402 14;
BA_ "GenMsgCycleTime" BO_ 401 50;
BA_ "VFrameFormat" BO_ 401 14;
BA_ "GenMsgCycleTime" BO_ 400 50;
BA_ "VFrameFormat" BO_ 400 14;
BA_ "GenMsgCycleTime" BO_ 254 20;
BA_ "VFrameFormat" BO_ 254 14;
BA_ "GenSigSendType" SG_ 984 ADCS_Resp_EncrData0 3;
BA_ "GenSigSendType" SG_ 984 ADCS_Resp_EncrData1 3;
BA_ "GenSigSendType" SG_ 984 ADCS_Resp_EncrData2 3;
BA_ "GenSigSendType" SG_ 984 ADCS_Resp_EncrData3 3;
BA_ "GenSigSendType" SG_ 984 ADCS_Resp_EncrData4 3;
BA_ "GenSigSendType" SG_ 984 ADCS_Resp_EncrData5 3;
BA_ "GenSigSendType" SG_ 984 ADCS_Resp_EncrData6 3;
BA_ "GenSigSendType" SG_ 984 ADCS_Resp_EncrData7 3;
BA_ "GenSigSendType" SG_ 983 BDM_Chall_ADCS_Random_0 3;
BA_ "GenSigSendType" SG_ 983 BDM_Chall_ADCS_Random_1 3;
BA_ "GenSigSendType" SG_ 983 BDM_Chall_ADCS_Random_2 3;
BA_ "GenSigSendType" SG_ 983 BDM_Chall_ADCS_Random_3 3;
BA_ "GenSigSendType" SG_ 983 BDM_Chall_ADCS_Random_4 3;
BA_ "GenSigSendType" SG_ 983 BDM_Chall_ADCS_Random_5 3;
BA_ "GenSigSendType" SG_ 983 BDM_Chall_ADCS_Random_6 3;
BA_ "GenSigSendType" SG_ 983 BDM_Chall_ADCS_Random_7 3;
BA_ "GenSigStartValue" SG_ 170 MCU1_CurrentTorque 8000;
BA_ "GenSigStartValue" SG_ 171 FMCU1_CurrentTorque 8000;
BA_ "GenSigInvalidValue" SG_ 177 EPS1_TorsionBarTorque 2047;
BA_ "GenSigSendType" SG_ 177 EPS1_TorsionBarTorque 13;
BA_ "GenSigInvalidValue" SG_ 177 EPS1_SteeringAngle 65535;
BA_ "GenSigInvalidValue" SG_ 177 EPS1_SteerAngleSpd 16383;
BA_ "GenSigSendType" SG_ 177 EPS1_HSTWCalibrated 13;
BA_ "GenSigInvalidValue" SG_ 178 EPS2_MotCntrl 2047;
BA_ "GenSigInvalidValue" SG_ 192 IDB2_FLWhlPulCnt 65535;
BA_ "GenSigInvalidValue" SG_ 192 IDB2_FRWhlPulCnt 65535;
BA_ "GenSigInvalidValue" SG_ 197 IDB3_MasterCylPressure 65535;
BA_ "GenSigStartValue" SG_ 197 IDB3_MasterCylPressure 3000;
BA_ "GenSigInvalidValue" SG_ 199 IDB4_FLWhlVelocity 16383;
BA_ "GenSigInvalidValue" SG_ 199 IDB4_FRWhlVelocity 16383;
BA_ "GenSigInvalidValue" SG_ 199 IDB4_RLWhlVelocity 16383;
BA_ "GenSigInvalidValue" SG_ 199 IDB4_RRWhlVelocity 16383;
BA_ "GenSigInvalidValue" SG_ 199 IDB4_RLWhlPulCnt 65535;
BA_ "GenSigInvalidValue" SG_ 199 IDB4_RRWhlPulCnt 65535;
BA_ "GenSigStartValue" SG_ 297 IDB5_ACC_ReferenceAccel 1023;
BA_ "GenSigStartValue" SG_ 201 IDB10_MotrTrqFrntAxleTargt 32000;
BA_ "GenSigStartValue" SG_ 201 IDB10_MotrTrqRearAxleTargt 32000;
BA_ "GenSigStartValue" SG_ 201 IDB10_ADAS_DrvTorque 32000;
BA_ "GenSigStartValue" SG_ 276 CS1_GearPositionReqStInv 7;
BA_ "GenSigInvalidValue" SG_ 196 ACU2_LatAccSensorValue 2047;
BA_ "GenSigInvalidValue" SG_ 196 ACU2_LongAccSensorValue 2047;
BA_ "GenSigInvalidValue" SG_ 196 ACU2_VehicleDynYawRate 8191;
BA_ "GenSigSendType" SG_ 528 ADCS9_AVM_startMode 13;
BA_ "GenSigStartValue" SG_ 403 ADCS8_LKSSetspeed 55;
BA_ "GenSigStartValue" SG_ 403 ADCS8_ACCState 1;
BA_ "GenSigStartValue" SG_ 403 ADCS8_longitudCtrlSetSpeed 30;
BA_ "GenSigStartValue" SG_ 403 ADCS8_longitudCtrlSetDistance 5;
BA_ "GenSigStartValue" SG_ 403 ADCS8_AEB_SystemStatus 1;
BA_ "GenSigStartValue" SG_ 403 ADCS8_FCTA_State 2;
BA_ "GenSigStartValue" SG_ 403 ADCS8_RCTA_State 2;
BA_ "GenSigStartValue" SG_ 403 ADCS8_RCW_State 2;
BA_ "GenSigStartValue" SG_ 403 ADCS8_DOWState 2;
BA_ "GenSigStartValue" SG_ 403 ADCS8_LCAState 2;
BA_ "GenSigStartValue" SG_ 403 ADCS8_TSRState 2;
BA_ "GenSigStartValue" SG_ 403 ADCS8_GMState 2;
BA_ "GenSigStartValue" SG_ 403 ADCS8_TSR_OverspeedOnOffSet 1;
BA_ "GenSigStartValue" SG_ 403 ADCS8_Lanechangedirection 1;
BA_ "GenSigStartValue" SG_ 403 ADCS8_ADSDriving_mode 1;
BA_ "GenSigStartValue" SG_ 403 ADCS8_GM_SystemFaultStatus 1;
BA_ "GenSigStartValue" SG_ 403 ADCS8_SystemFault 1;
BA_ "GenSigInvalidValue" SG_ 404 ADCS8_PA_FPAS_SnsrDist_FLC 255;
BA_ "GenSigInvalidValue" SG_ 404 ADCS8_PA_FPAS_SnsrDist_FLM 255;
BA_ "GenSigInvalidValue" SG_ 404 ADCS8_PA_FPAS_SnsrDist_FRM 255;
BA_ "GenSigInvalidValue" SG_ 404 ADCS8_PA_FPAS_SnsrDist_FRC 255;
BA_ "GenSigInvalidValue" SG_ 404 ADCS8_PA_FPAS_SnsrDist_RLC 255;
BA_ "GenSigInvalidValue" SG_ 404 ADCS8_PA_FPAS_SnsrDist_RLM 255;
BA_ "GenSigInvalidValue" SG_ 404 ADCS8_PA_FPAS_SnsrDist_RRM 255;
BA_ "GenSigInvalidValue" SG_ 404 ADCS8_PA_FPAS_SnsrDist_RRC 255;
BA_ "GenSigInvalidValue" SG_ 404 ADCS8_PA_FPAS_SnsrDist_SFL 511;
BA_ "GenSigInvalidValue" SG_ 404 ADCS8_PA_FPAS_SnsrDist_SFR 511;
BA_ "GenSigInvalidValue" SG_ 404 ADCS8_PA_FPAS_SnsrDist_SRL 511;
BA_ "GenSigInvalidValue" SG_ 404 ADCS8_PA_FPAS_SnsrDist_SRR 511;
BA_ "GenSigStartValue" SG_ 404 ADCS8_PA_FPAS_WorkSts 1;
BA_ "GenSigStartValue" SG_ 404 ADCS8_PA_RPAS_WorkSts 1;
BA_ "GenSigInvalidValue" SG_ 402 ADCS7_RPA_slot_ID_7_P0_X 16383;
BA_ "GenSigInvalidValue" SG_ 402 ADCS7_RPA_slot_ID_7_P0_Y 16383;
BA_ "GenSigInvalidValue" SG_ 402 ADCS7_RPA_slot_ID_7_P1_X 16383;
BA_ "GenSigInvalidValue" SG_ 402 ADCS7_RPA_slot_ID_7_P1_Y 16383;
BA_ "GenSigInvalidValue" SG_ 402 ADCS7_RPA_slot_ID_7_P2_X 16383;
BA_ "GenSigInvalidValue" SG_ 402 ADCS7_RPA_slot_ID_7_P2_Y 16383;
BA_ "GenSigInvalidValue" SG_ 402 ADCS7_RPA_slot_ID_7_P3_X 16383;
BA_ "GenSigInvalidValue" SG_ 402 ADCS7_RPA_slot_ID_7_P3_Y 16383;
BA_ "GenSigInvalidValue" SG_ 402 ADCS7_RPA_slot_Angle7 32767;
BA_ "GenSigInvalidValue" SG_ 402 ADCS7_RPA_ParkingSlotDepth7 2047;
BA_ "GenSigInvalidValue" SG_ 402 ADCS7_RPA_ParkingSlotWidth7 2047;
BA_ "GenSigInvalidValue" SG_ 402 ADCS7_RPA_slot_ID_8_P0_X 16383;
BA_ "GenSigInvalidValue" SG_ 402 ADCS7_RPA_slot_ID_8_P0_Y 16383;
BA_ "GenSigInvalidValue" SG_ 402 ADCS7_RPA_slot_ID_8_P1_X 16383;
BA_ "GenSigInvalidValue" SG_ 402 ADCS7_RPA_slot_ID_8_P1_Y 16383;
BA_ "GenSigInvalidValue" SG_ 402 ADCS7_RPA_slot_ID_8_P2_X 16383;
BA_ "GenSigInvalidValue" SG_ 402 ADCS7_RPA_slot_ID_8_P2_Y 16383;
BA_ "GenSigInvalidValue" SG_ 402 ADCS7_RPA_slot_ID_8_P3_X 16383;
BA_ "GenSigInvalidValue" SG_ 402 ADCS7_RPA_slot_ID_8_P3_Y 16383;
BA_ "GenSigInvalidValue" SG_ 402 ADCS7_RPA_slot_Angle8 32767;
BA_ "GenSigInvalidValue" SG_ 402 ADCS7_RPA_ParkingSlotDepth8 2047;
BA_ "GenSigInvalidValue" SG_ 402 ADCS7_RPA_ParkingSlotWidth8 2047;
BA_ "GenSigInvalidValue" SG_ 402 ADCS7_PA_ObsDist_F 255;
BA_ "GenSigInvalidValue" SG_ 402 ADCS7_PA_ObsDist_R 255;
BA_ "GenSigInvalidValue" SG_ 402 ADCS7_RPA_ObsDist 255;
BA_ "GenSigInvalidValue" SG_ 401 ADCS6_RPA_slot_ID_4_P0_X 16383;
BA_ "GenSigInvalidValue" SG_ 401 ADCS6_RPA_slot_ID_4_P0_Y 16383;
BA_ "GenSigInvalidValue" SG_ 401 ADCS6_RPA_slot_ID_4_P1_X 16383;
BA_ "GenSigInvalidValue" SG_ 401 ADCS6_RPA_slot_ID_4_P1_Y 16383;
BA_ "GenSigInvalidValue" SG_ 401 ADCS6_RPA_slot_ID_4_P2_X 16383;
BA_ "GenSigInvalidValue" SG_ 401 ADCS6_RPA_slot_ID_4_P2_Y 16383;
BA_ "GenSigInvalidValue" SG_ 401 ADCS6_RPA_slot_ID_4_P3_X 16383;
BA_ "GenSigInvalidValue" SG_ 401 ADCS6_RPA_slot_ID_4_P3_Y 16383;
BA_ "GenSigInvalidValue" SG_ 401 ADCS6_RPA_slot_Angle4 32767;
BA_ "GenSigInvalidValue" SG_ 401 ADCS6_RPA_ParkingSlotDepth4 2047;
BA_ "GenSigInvalidValue" SG_ 401 ADCS6_RPA_ParkingSlotWidth4 2047;
BA_ "GenSigInvalidValue" SG_ 401 ADCS6_RPA_slot_ID_5_P0_X 16383;
BA_ "GenSigInvalidValue" SG_ 401 ADCS6_RPA_slot_ID_5_P0_Y 16383;
BA_ "GenSigInvalidValue" SG_ 401 ADCS6_RPA_slot_ID_5_P1_X 16383;
BA_ "GenSigInvalidValue" SG_ 401 ADCS6_RPA_slot_ID_5_P1_Y 16383;
BA_ "GenSigInvalidValue" SG_ 401 ADCS6_RPA_slot_ID_5_P2_X 16383;
BA_ "GenSigInvalidValue" SG_ 401 ADCS6_RPA_slot_ID_5_P2_Y 16383;
BA_ "GenSigInvalidValue" SG_ 401 ADCS6_RPA_slot_ID_5_P3_X 16383;
BA_ "GenSigInvalidValue" SG_ 401 ADCS6_RPA_slot_ID_5_P3_Y 16383;
BA_ "GenSigInvalidValue" SG_ 401 ADCS6_RPA_slot_Angle5 32767;
BA_ "GenSigInvalidValue" SG_ 401 ADCS6_RPA_ParkingSlotDepth5 2047;
BA_ "GenSigInvalidValue" SG_ 401 ADCS6_RPA_ParkingSlotWidth5 2047;
BA_ "GenSigInvalidValue" SG_ 401 ADCS6_RPA_slot_ID_6_P0_X 16383;
BA_ "GenSigInvalidValue" SG_ 401 ADCS6_RPA_slot_ID_6_P0_Y 16383;
BA_ "GenSigInvalidValue" SG_ 401 ADCS6_RPA_slot_ID_6_P1_X 16383;
BA_ "GenSigInvalidValue" SG_ 401 ADCS6_RPA_slot_ID_6_P1_Y 16383;
BA_ "GenSigInvalidValue" SG_ 401 ADCS6_RPA_slot_ID_6_P2_X 16383;
BA_ "GenSigInvalidValue" SG_ 401 ADCS6_RPA_slot_ID_6_P2_Y 16383;
BA_ "GenSigInvalidValue" SG_ 401 ADCS6_RPA_slot_ID_6_P3_X 16383;
BA_ "GenSigInvalidValue" SG_ 401 ADCS6_RPA_slot_ID_6_P3_Y 16383;
BA_ "GenSigInvalidValue" SG_ 401 ADCS6_RPA_slot_Angle6 32767;
BA_ "GenSigInvalidValue" SG_ 401 ADCS6_RPA_ParkingSlotDepth6 2047;
BA_ "GenSigInvalidValue" SG_ 401 ADCS6_RPA_ParkingSlotWidth6 2047;
BA_ "GenSigInvalidValue" SG_ 400 ADCS5_RPA_slot_ID_1_P0_X 16383;
BA_ "GenSigInvalidValue" SG_ 400 ADCS5_RPA_slot_ID_1_P0_Y 16383;
BA_ "GenSigInvalidValue" SG_ 400 ADCS5_RPA_slot_ID_1_P1_X 16383;
BA_ "GenSigInvalidValue" SG_ 400 ADCS5_RPA_slot_ID_1_P1_Y 16383;
BA_ "GenSigInvalidValue" SG_ 400 ADCS5_RPA_slot_ID_1_P2_X 16383;
BA_ "GenSigInvalidValue" SG_ 400 ADCS5_RPA_slot_ID_1_P2_Y 16383;
BA_ "GenSigInvalidValue" SG_ 400 ADCS5_RPA_slot_ID_1_P3_X 16383;
BA_ "GenSigInvalidValue" SG_ 400 ADCS5_RPA_slot_ID_1_P3_Y 16383;
BA_ "GenSigInvalidValue" SG_ 400 ADCS5_RPA_slot_Angle1 32767;
BA_ "GenSigInvalidValue" SG_ 400 ADCS5_RPA_ParkingSlotDepth1 2047;
BA_ "GenSigInvalidValue" SG_ 400 ADCS5_RPA_ParkingSlotWidth1 2047;
BA_ "GenSigInvalidValue" SG_ 400 ADCS5_RPA_slot_ID_2_P0_X 16383;
BA_ "GenSigInvalidValue" SG_ 400 ADCS5_RPA_slot_ID_2_P0_Y 16383;
BA_ "GenSigInvalidValue" SG_ 400 ADCS5_RPA_slot_ID_2_P1_X 16383;
BA_ "GenSigInvalidValue" SG_ 400 ADCS5_RPA_slot_ID_2_P1_Y 16383;
BA_ "GenSigInvalidValue" SG_ 400 ADCS5_RPA_slot_ID_2_P2_X 16383;
BA_ "GenSigInvalidValue" SG_ 400 ADCS5_RPA_slot_ID_2_P2_Y 16383;
BA_ "GenSigInvalidValue" SG_ 400 ADCS5_RPA_slot_ID_2_P3_X 16383;
BA_ "GenSigInvalidValue" SG_ 400 ADCS5_RPA_slot_ID_2_P3_Y 16383;
BA_ "GenSigInvalidValue" SG_ 400 ADCS5_RPA_slot_Angle2 32767;
BA_ "GenSigInvalidValue" SG_ 400 ADCS5_RPA_ParkingSlotDepth2 2047;
BA_ "GenSigInvalidValue" SG_ 400 ADCS5_RPA_ParkingSlotWidth2 2047;
BA_ "GenSigInvalidValue" SG_ 400 ADCS5_RPA_slot_ID_3_P0_X 16383;
BA_ "GenSigInvalidValue" SG_ 400 ADCS5_RPA_slot_ID_3_P0_Y 16383;
BA_ "GenSigInvalidValue" SG_ 400 ADCS5_RPA_slot_ID_3_P1_X 16383;
BA_ "GenSigInvalidValue" SG_ 400 ADCS5_RPA_slot_ID_3_P1_Y 16383;
BA_ "GenSigInvalidValue" SG_ 400 ADCS5_RPA_slot_ID_3_P2_X 16383;
BA_ "GenSigInvalidValue" SG_ 400 ADCS5_RPA_slot_ID_3_P2_Y 16383;
BA_ "GenSigInvalidValue" SG_ 400 ADCS5_RPA_slot_ID_3_P3_X 16383;
BA_ "GenSigInvalidValue" SG_ 400 ADCS5_RPA_slot_ID_3_P3_Y 16383;
BA_ "GenSigInvalidValue" SG_ 400 ADCS5_RPA_slot_Angle3 32767;
BA_ "GenSigInvalidValue" SG_ 400 ADCS5_RPA_ParkingSlotDepth3 2047;
BA_ "GenSigInvalidValue" SG_ 400 ADCS5_RPA_ParkingSlotWidth3 2047;
BA_ "GenSigInvalidValue" SG_ 254 ADCS4_HourOfDay 63;
BA_ "GenSigInvalidValue" SG_ 254 ADCS4_MinuteOfHour 63;
BA_ "GenSigInvalidValue" SG_ 254 ADCS4_SecondOfMinute 63;
BA_ "GenSigSendType" SG_ 254 ADCS4_DCWposition 13;
BA_ "GenSigSendType" SG_ 254 ADCS4_DCWlevel 13;
VAL_ 515 CDCS15_NNP_DriverStatus 2 " Driver Distracted" 1 "Driver Fatigue" 0 "None";
VAL_ 515 CDCS15_Storage_St 1 "not available" 0 "available";
VAL_ 515 CDCS15_USB_St 1 "not available" 0 "available";
VAL_ 515 CDCS15_UserSceneMode 15 "Reserved" 9 "Reserved" 8 "OtherMode14" 7 "OtherMode3" 6 "OtherMode2" 5 "OtherMode1" 4 "PetMode" 3 "Childmode" 2 "CarWashMode" 1 "RacingMode" 0 "No Scene";
VAL_ 579 AICS2_OTAMode 15 "Reserved" 4 "Reserved" 3 "in OTA mode" 2 "enter OTA mode request" 1 "quit OTA mode request" 0 "No request";
VAL_ 579 AICS2_StopChargeing 15 "Reserved" 2 "Reserved" 1 " shutdown chargeing" 0 " No request";
VAL_ 579 AICS2_BootRequestHVShut 1 "Request" 0 "No request";
VAL_ 170 MCU1_CurrentTorqueValid 1 "Invalid" 0 "Valid";
VAL_ 171 FMCU1_CurrentTorqueValid 1 "Invalid" 0 "Valid";
VAL_ 177 EPS1_TorsionBarTorqueValid 1 "Valid" 0 "Invalid";
VAL_ 177 EPS1_SteeringAngleValid 1 "Valid" 0 "Invalid";
VAL_ 177 EPS1_SteerAngleSpdValid 1 "Valid" 0 "Invalid";
VAL_ 177 EPS1_HSTWCalibrated 1 "angle calibrated" 0 "angle not calibrated";
VAL_ 177 EPS1_WarningLampYellow 3 "Reserved" 2 "function limited， lamp on" 1 "angle not calibrated,lamp blink" 0 "close";
VAL_ 177 EPS1_WarningLampRed 1 "Function failure，lamp on" 0 "close";
VAL_ 178 EPS2_ADAS_Available 1 "Available" 0 "Not  Available";
VAL_ 178 EPS2_ADAS_Active 1 "active" 0 "not active";
VAL_ 178 EPS2_ADAS_CtrlAbortFeedback 10 " Parking interruption" 9 "ADAS activation request error" 8 "Request Value over range " 7 "Request Slope over range " 6 "ADAS transmition signal error" 5 "EPS Temporary error " 4 "EPS Permanently error " 3 "Over speed" 2 "Vehicle Speed Invalid" 1 "Driver  override" 0 "No error";
VAL_ 178 EPS2_AssistPraSwitchToDAS 3 "Reserved" 2 "APA mode" 1 "ADAS mode" 0 "not in ADAS mode";
VAL_ 178 EPS2_MotCntrlValid 1 "Valid" 0 "Invalid";
VAL_ 178 EPS2_PA_Available 1 "Available" 0 "Not Available ";
VAL_ 178 EPS2_PA_Active 1 "active" 0 "not active";
VAL_ 178 EPS2_PA_CtrlAbortFeedback 9 "Parking activation error" 8 "Request Value over range " 7 "Request Slope over range " 6 "APA transmition signal error" 5 "EPS Temporary error " 4 "EPS Permanently error " 3 "Over speed" 2 "Vehicle Speed Invalid " 1 "Driver override " 0 "No error";
VAL_ 229 IDB1_BrakePedalApplied 1 "press( 制动踏板被踩下)" 0 "no press(( 制动踏板未被踩下)";
VAL_ 229 IDB1_BrakePedalAppliedV 1 "Valid(有效)" 0 "Invalid(无效)";
VAL_ 229 IDB1_FailedState 6 "fault level 6" 5 "fault level 5" 4 "fault level 4" 3 "fault level 3" 2 "fault level 2" 1 "fault level 1" 0 "no fault";
VAL_ 229 IDB1_CSTFail 1 "Fail" 0 "Not fail";
VAL_ 229 IDB1_CSTAtive 1 "Active" 0 "Not active";
VAL_ 229 IDB1_CSTEnabled 1 "Enabled" 0 "Disabled";
VAL_ 229 IDB1_Brakestyle_Enabled 1 "Enabled" 0 "Disabled";
VAL_ 229 IDB1_Brakestyle_Fail 1 "Fail" 0 "Not fail";
VAL_ 192 IDB2_FLWhlPulCntValid 1 "Valid(有效)" 0 "Invalid(无效)";
VAL_ 192 IDB2_FRWhlPulCntValid 1 "Valid(有效)" 0 "Invalid(无效)";
VAL_ 197 IDB3_VehicleSpdValid 1 "Valid(有效)" 0 "Invalid(无效)";
VAL_ 197 IDB3_MasterCylPressureInvalid 1 "Valid(有效)" 0 "Invalid(无效)";
VAL_ 199 IDB4_FLWhlVelocityValid 1 "Valid(有效)" 0 "Invalid(无效)";
VAL_ 199 IDB4_FRWhlVelocityValid 1 "Valid(有效)" 0 "Invalid(无效)";
VAL_ 199 IDB4_FRWhlDir 3 "Error identifier" 2 "Backward direction" 1 "Forward direction" 0 "Unknown or stanstill";
VAL_ 199 IDB4_FLWhlDir 3 "Error identifier" 2 "Backward direction" 1 "Forward direction" 0 "Unknown or stanstill";
VAL_ 199 IDB4_RLWhlDir 3 "Error identifier" 2 "Backward direction" 1 "Forward direction" 0 "Unknown or stanstill";
VAL_ 199 IDB4_RRWhlDir 3 "Error identifier" 2 "Backward direction" 1 "Forward direction" 0 "Unknown or stanstill";
VAL_ 199 IDB4_RLWhlVelocityValid 1 "Valid(有效)" 0 "Invalid(无效)";
VAL_ 199 IDB4_RRWhlVelocityValid 1 "Valid(有效)" 0 "Invalid(无效)";
VAL_ 199 IDB4_RLWhlPulCntValid 1 "Valid(有效)" 0 "Invalid(无效)";
VAL_ 199 IDB4_RRWhlPulCntValid 1 "Valid(有效)" 0 "Invalid(无效)";
VAL_ 289 IDB9_PA_CtrlAbortFeedback 7 "Communication failure with RCU" 6 "IDB Hydraulic failure" 5 "IDB Internal failure" 4 "Communication error with APA" 3 "Failure" 2 "EPB intervened" 1 "over speed" 0 "normal";
VAL_ 289 IDB9_PA_ParkingBrkMdSeln 2 "Function Not Active" 1 " Standstill (vehicle has been stopped)" 0 " Not standstill ";
VAL_ 289 IDB9_PA_ParkingFnMd 3 "Cruising(AVP) Mode" 2 "Cruising （HPP/ISM）Mode" 1 " Parking Mode" 0 " Function Not Active";
VAL_ 289 IDB9_PA_Prefill 1 " on" 0 " off";
VAL_ 289 IDB9_PA_ParkingAvailable 1 "Not Available" 0 "Available";
VAL_ 289 IDB9_PA_ApaCtrlSts 7 " Reserved" 6 " Emergency Stop " 5 " IDB Fail " 4 " Standstill " 3 " Stop Control " 2 " Speed Control " 1 " Ready " 0 " Off ";
VAL_ 289 IDB9_PASts 1 "Failure" 0 "Normal";
VAL_ 289 IDB9_PAStandStill 1 "standstill" 0 "not standstill";
VAL_ 297 IDB5_BrakeDiscTempSts 1 "Temperature too high;" 0 "Not high;";
VAL_ 297 IDB5_VehicleStanstill 3 "reserved;" 2 "invalid (short unavailability, max 3min);" 1 "standstill;" 0 "not standstill;";
VAL_ 297 IDB5_JerkActive 1 "available" 0 "Not available";
VAL_ 297 IDB5_Jerkfail 1 "fail" 0 "no fail";
VAL_ 297 IDB5_ADAS_PrefillSts 1 " active" 0 " not active";
VAL_ 297 IDB5_ACC_ReqLim 3 "Deceleration Limit" 2 "Reserved" 1 "Reserved" 0 "No request";
VAL_ 297 IDB5_DBSavailable 1 "Available" 0 "Not Available";
VAL_ 297 IDB5_Prefillavailable 1 "Available" 0 "Not Available";
VAL_ 297 IDB5_ABAactive 1 "Active" 0 "No Active";
VAL_ 297 IDB5_ACC_Enable 3 "ACC Communication Error" 2 "Permanently not Available" 1 "Temporarily not Available" 0 "Available";
VAL_ 297 IDB5_ACC_Sta 1 "ready" 0 "no ready";
VAL_ 297 IDB5_AEB_Enable 3 "AEB Communication Error" 2 "Permanently not Available" 1 "Temporarily not Available" 0 "Available";
VAL_ 297 IDB5_AEBactive 1 "Active" 0 "No Active";
VAL_ 297 IDB5_DriverOverride 3 "Reserved" 2 "DecelOverride" 1 "AccelOverride" 0 "No override";
VAL_ 299 IDB6_EPBAvailable 6 "EPB  failure" 5 "EPB Permanently Not Available" 4 "EPB Temporarily Not Available" 3 "EPB Diagnostic" 2 "EPB Initialization State" 1 "EPB No failure" 0 "Not valid";
VAL_ 299 IDB6_EPBStatus 7 "Not Initialized (NEW)" 6 "Full Released完全释放" 5 "Dynamic braking via EPB动态驻车" 4 "Releasing in progress卡钳释放中" 3 "Clamping in progress卡钳夹紧中" 2 "Clamped卡钳夹紧" 1 "Released卡钳释放" 0 "Unknown未知";
VAL_ 301 IDB7_EBD_Fail 1 "fail" 0 "no fail";
VAL_ 301 IDB7_EBD_Active 1 "Active" 0 "Inactive";
VAL_ 301 IDB7_HBAActive 1 "Active" 0 "Inactive";
VAL_ 301 IDB7_HBAFail 1 "Fail" 0 "Not fail";
VAL_ 301 IDB7_DiagMode 1 "DiagnosticMode" 0 "NormalMode";
VAL_ 301 IDB7_TCSActive 1 "Active" 0 "Inactive";
VAL_ 301 IDB7_TCSDisable 1 "TCS Function Disabled" 0 "TCS Function Enabled";
VAL_ 301 IDB7_TCSFail 1 "Fail" 0 "Not fail";
VAL_ 301 IDB7_ROPACTIVE 1 "Active" 0 "No Active";
VAL_ 301 IDB7_ROPFailure 1 "Failure" 0 "No Failure";
VAL_ 301 IDB7_AVHDispMSG 3 "AUTO HOLD cannot be activated Close Door" 2 "Press Brake Pedal to Release AUTO HOLD" 1 "AUTO HOLD to be deactivated Press Brake Pedal" 0 "AVH is off";
VAL_ 301 IDB7_AVHLampReq 3 "AVH READY" 2 "AVH ACTIVE(Green)" 1 "AVH failure(Yellow)" 0 "AVH Off ";
VAL_ 301 IDB7_AVHStatus 2 "AVH being released" 1 "AVH Active" 0 "AVH Inactive";
VAL_ 301 IDB7_AVHEnabled 1 "Enabled" 0 "Disabled";
VAL_ 301 IDB7_DynParkBrkByIDBActive 1 "Active" 0 "Inactive";
VAL_ 301 IDB7_DynParkBrkByIDBAvailable 1 "Available" 0 "Not Available";
VAL_ 301 IDB7_HSAActive 1 "Active" 0 "Inactive";
VAL_ 301 IDB7_HSAFail 1 "Fail" 0 "Not fail";
VAL_ 301 IDB7_HDCEnabled 1 "Enabled" 0 "Disabled";
VAL_ 301 IDB7_HDCFail 1 "Fail" 0 "Not fail";
VAL_ 301 IDB7_HDCAtive 1 "Active" 0 "Not active";
VAL_ 301 IDB7_ABSActive 1 "Active" 0 "Inactive";
VAL_ 301 IDB7_ABSFail 1 "fail" 0 "no fail";
VAL_ 301 IDB7_ESCFail 1 "Fail" 0 "Not fail";
VAL_ 301 IDB7_ESCActive 1 "Active" 0 "Inactive";
VAL_ 301 IDB7_ESCDisable 1 "ESC Function Disabled" 0 "ESC Function Enabled";
VAL_ 201 IDB10_MotrTrqFrntAxleTargtReq 1 "Request" 0 "No Request";
VAL_ 201 IDB10_MotrTrqRearAxleTargtReq 1 "Request" 0 "No Request";
VAL_ 201 IDB10_ADAS_DrvTorqueReq 1 "Request" 0 "No Request";
VAL_ 272 BDCS1_PowerMode 3 "Crank" 2 "ON" 1 "ACC" 0 "OFF";
VAL_ 272 BDCS1_PowerManageMode 15 "Reserved" 11 "Reserved" 10 " ON(Biological)" 9 "ON(Guard)" 8 "RUNNING" 7 "CRANK" 6 "ON(Remote)" 5 "ON(OTA)" 4 "ON(PetToLookAfter)" 3 "ON(120min) " 2 "ON(5min)" 1 "ON(Factory)" 0 "OFF";
VAL_ 272 BDCS1_LowBeamSt 1 "Active" 0 "Inactive";
VAL_ 272 BDCS1_HighBeamSt 1 "Active" 0 "Inactive";
VAL_ 272 BDCS1_PositionLightSts 1 "Active" 0 "Inactive";
VAL_ 272 BDCS1_BacklightStatus 1 "Active" 0 "Inactive";
VAL_ 272 BDCS1_LeftTurnLightSt 1 "Active" 0 "Inactive";
VAL_ 272 BDCS1_RightTurnLightSt 1 "Active" 0 "Inactive";
VAL_ 272 BDCS1_FrontLampSt 3 "LowBeam" 2 "PositionLamp" 1 "Auto" 0 "OFF";
VAL_ 272 BDCS1_HazardLampSt 1 "Active" 0 "Inactive";
VAL_ 272 BDCS1_HighBeamSW 3 "Reserved" 2 "HighBeam" 1 "Flash" 0 "OFF";
VAL_ 272 BDCS1_TurnLightSW 3 "Reserved" 2 "Right" 1 "Left" 0 "OFF";
VAL_ 272 BDCS1_HazardSwSt 1 "Active" 0 "Inactive";
VAL_ 272 BDCS1_RearFogLampSt 1 "Active" 0 "Inactive";
VAL_ 272 BDCS1_FrontFogLampSt 1 "Active" 0 "Inactive";
VAL_ 272 BDCS1_TrunkLockSts 1 "Locked" 0 "Unlocked";
VAL_ 272 BDCS1_HoodAjarSts 1 "Open" 0 "Closed";
VAL_ 274 BDCS3_RemoteAuthenSts 3 "Reserved" 2 "Authentication Failed" 1 "Authentication Successed" 0 "Default";
VAL_ 274 BDCS3_BackDoorAjar 7 "Unknow" 6 "Reserved " 5 "Reserved " 4 "Cannot Close Area " 3 "Fully Open " 2 "Open to Custon Height " 1 "Not Closed " 0 "Fully Closed ";
VAL_ 274 BDCS3_ADCSAuthenSts 3 "Reserved" 2 "Authentication Failed" 1 "Authentication Successed" 0 "Default";
VAL_ 276 CS1_HighBeamFlashReqSt 1 "Active" 0 "Inactive";
VAL_ 276 CS1_FrontWiperMISTReqSt 1 "Active" 0 "Inactive";
VAL_ 276 CS1_HighBeamReqSt 1 "Active" 0 "Inactive";
VAL_ 276 CS1_TurnLightReqSt 7 "Error" 4 "TurnLeftStatus" 3 "左变道" 2 "TurnRightStatus" 1 "右变道" 0 "No request";
VAL_ 276 CS1_FrontWiperReqSt 7 "Error" 5 "AUTO 2" 4 "AUTO 1" 3 "HI" 2 "LOW" 1 "MIST（Reserved）" 0 "OFF";
VAL_ 276 CS1_FrontWiperWashReqSt 1 "Active" 0 "Inactive";
VAL_ 276 CS1_RearWiperReqSt_Reserved 1 "Active" 0 "Inactive";
VAL_ 276 CS1_RearWiperWashReqSt_Reserved 1 "Active" 0 "Inactive";
VAL_ 276 CS1_GearPositionReqSt 7 "Gear hold（Reserved）" 6 "S（Reserved）" 5 "D" 4 "N2" 3 "N1" 2 "R" 1 "P（Reserved）" 0 "No request";
VAL_ 276 CS1_GearPositionReqStInv 7 "No request" 6 "P(Reserved)" 5 "R" 4 "N1" 3 "N2" 2 "D" 1 "S(Reserved)" 0 "Gear Hold(Reserved)";
VAL_ 276 CS1_GearPositionReqStValid 1 "Valid" 0 "Invalid";
VAL_ 258 ACU1_Driver_Buckle 3 "Not Avaliable(安全带未配置)" 2 "Fault(安全带有错)" 1 "Unbuckled(安全带未系上)" 0 "Buckled(安全带系上)";
VAL_ 258 ACU1_Passenger_Buckle 3 "Not Avaliable(安全带未配置)" 2 "Fault(安全带有错)" 1 "Unbuckled(安全带未系上)" 0 "Buckled(安全带系上)";
VAL_ 258 ACU1_Rear_Left_Buckle 5 "Unbuckled（无ODS）" 4 "Buckled（无ODS）" 3 "Not Avaliable(安全带未配置)" 2 "Fault(安全带有错)" 1 "Occupied and Unbuckled（有人未系）" 0 "Buckled Or unOccupied（安全带系上或者无人）";
VAL_ 258 ACU1_Rear_Middle_Buckle 5 "Unbuckled（无ODS）" 4 "Buckled（无ODS）" 3 "Not Avaliable(安全带未配置)" 2 "Fault(安全带有错)" 1 "Occupied and Unbuckled（有人未系）" 0 "Buckled Or unOccupied（安全带系上或者无人）";
VAL_ 258 ACU1_Rear_Right_Buckle 5 "Unbuckled（无ODS）" 4 "Buckled（无ODS）" 3 "Not Avaliable(安全带未配置)" 2 "Fault(安全带有错)" 1 "Occupied and Unbuckled（有人未系）" 0 "Buckled Or unOccupied（安全带系上或者无人）";
VAL_ 258 ACU1_Passenger_ODS 3 "Not Avaliable(安全带未配置)" 2 "Fault(安全带有错)" 1 "Unoccupied（无人）" 0 "Occupied（有人）";
VAL_ 258 ACU1_CrashStatus 1 "Crash happened（有碰撞事件）" 0 "Crash not happened（没有碰撞事件）";
VAL_ 258 ACU1_warningLight 3 "Signal Not Available（警报灯信号无效）" 2 "AWL Flashing（警报灯闪）" 1 "AWL ON（警报灯亮）" 0 "AWL OFF（警报灯灭）";
VAL_ 196 ACU2_LatAccSensorValueV 1 "Valid(有效)" 0 "Invalid(无效)";
VAL_ 196 ACU2_LongAccSensorValueV 1 "Valid(有效)" 0 "Invalid(无效)";
VAL_ 196 ACU2_VehicleDynYawRateV 1 "Valid(有效)" 0 "Invalid(无效)";
VAL_ 196 ACU2_Sensorcalibration 1 "calibration(已标定)" 0 "No calibration(未标定)";
VAL_ 305 ICU1_VehicleSpdDisplayValid 1 "Valid" 0 "Invalid";
VAL_ 992 CalendarMonth 12 "December" 11 "November" 10 "October" 9 "September" 8 "August" 7 "July" 6 "June" 5 "May" 4 "April" 3 "March" 2 "February" 1 "January" 0 "Unknown";
VAL_ 992 TimeDspFmt 1 "12 hour mode(not used)" 0 "24 hour mode(default)";
VAL_ 528 ADCS9_AVM_MODdetectionSts 1 "Closed" 0 "Open";
VAL_ 528 ADCS9_AVM_TransparentchassisSts 1 "Closed" 0 "Open";
VAL_ 528 ADCS9_PA_FRS_Onoffset 1 "On（开启）" 0 "Off（关闭）";
VAL_ 528 ADCS9_AVM_Diaphaneity 10 " 100%" 9 " 90%" 8 " 80%" 7 " 70%" 6 " 60%" 5 " 50%" 4 " 40%" 3 " 30%" 2 " 20%" 1 " 10%" 0 " 0%";
VAL_ 528 ADCS9_AVM_startMode 7 " Reserved" 6 " Reserved" 5 " Reserved" 4 " Reserved" 3 "Reserved" 2 "24 h" 1 "12 h" 0 "0 h";
VAL_ 528 ADCS9_CDCS_CertificateState 1 "有效" 0 "无效";
VAL_ 528 ADCS9_AVM_LowSpeedBSDSts 1 "Closed" 0 "Open";
VAL_ 528 ADCS9_AVM_SpeViewSts 2 "Rear wide view" 1 "Front wide view" 0 "Default";
VAL_ 528 ADCS9_AVM_3DRotateSts 1 "Closed" 0 "Open";
VAL_ 528 ADCS9_AVM_TurnlightstartSts 1 "Closed" 0 "Open";
VAL_ 528 ADCS9_AVM_SteeringstartSts 1 "Closed" 0 "Open";
VAL_ 528 ADCS9_AVM_MagnifiedviewSts 1 "Closed" 0 "Open";
VAL_ 528 ADCS9_AVM_auxiliarylineSts 1 "Closed" 0 "Open";
VAL_ 528 ADCS9_AVM_RaderdisplaySts 1 "Closed" 0 "Open";
VAL_ 528 ADCS9_AVM_InitializationSts 1 "Initialization success" 0 "Default";
VAL_ 528 ADCS9_AVM_bodySyncSts 1 "Closed" 0 "Open";
VAL_ 403 ADCS8_LDWMode 1 "On" 0 "Off";
VAL_ 403 ADCS8_LDWWarnState 5 "Reserved" 4 "Right Warning leve2" 3 "Right Warning leve1" 2 "Left Warning leve2" 1 "Left Warning leve1" 0 "No Warning";
VAL_ 403 ADCS8_LDWState 7 "Reserved" 6 "Reserved" 5 "Reserved" 4 "LDW passive" 3 "LDW Fail" 2 "LDW Active" 1 "LDW Standby" 0 "Off";
VAL_ 403 ADCS8_ELKMode 1 "On" 0 "Off";
VAL_ 403 ADCS8_LDPELKWarnState 3 "Reserved" 2 "Right Warning " 1 "Left Warning" 0 "No Warning";
VAL_ 403 ADCS8_MissingExitAlert 3 "Reserved" 2 " Exit Missed" 1 " Navigation Task Take Over Request" 0 "No Warning";
VAL_ 403 ADCS8_LDPMode 1 "On" 0 "Off";
VAL_ 403 ADCS8_lateralCtrHandsEyesOffWarning 3 "eyes off Warning" 2 "Automatic-Off Warning(Display)" 1 "Hands-off Warning(Display)" 0 "No Warning";
VAL_ 403 ADCS8_LDPELKtakeoverWarningstate 2 "Lever 2" 1 "Lever 1" 0 "No warning";
VAL_ 403 ADAS8_LateralCtrHandOffReleasewarning 1 "Requested" 0 "No request";
VAL_ 403 ADCS8_lateralCtrtakeover 1 "Requested" 0 "No request";
VAL_ 403 ADCS8_ACCState 7 "Passive" 6 "Fault" 5 "Standstill Wait" 4 "Standstill Active" 3 "Override" 2 "Active" 1 "Standby" 0 "Off";
VAL_ 403 ADCS8_longitudCtrlTakeOverReq 1 "Requested" 0 "No Request";
VAL_ 403 ADCS8_NNP_Scenarios 11 " Best Path Tracing" 10 " Oncoming Vehicle" 9 " Oversized Vehicle One Side" 8 " Oversized Vehicle Both Side" 7 " SpeedAdapt" 6 " Narrow Lane" 5 " Lane  Reduce" 4 " PayModeConfirm" 3 " Pedastrian Walk" 2 "  TFL" 1 "  Static Obstacle" 0 "None";
VAL_ 403 ADCS8_longitudCtrlSetDistance 7 "Reserved2" 6 "Reserved1" 5 "Level#5" 4 "Level#4" 3 "Level#3" 2 "Level#2" 1 "Level#1" 0 "No time gap set";
VAL_ 403 ADCS8_longitudCtrlTargetValidity 1 "Valid target vehicle" 0 "No target vehicle";
VAL_ 403 ADCS8_ACCSystemFaultStatus 3 "Service Required" 2 "System Temporary Unvailable" 1 "Performance Degradation" 0 "No Error";
VAL_ 403 ADCS8_AEB_SystemFaultStatus 3 "Service Required" 2 "System Temporary Unvailable" 1 "Performance Degradation" 0 "No Error";
VAL_ 403 ADCS8_AEB_SystemStatus 1 "On" 0 "Off";
VAL_ 403 ADCS8_FCW_State 1 "On" 0 "Off";
VAL_ 403 ADCS8_FCWSensitiveLevel 2 " Early" 1 " Normal" 0 " Late";
VAL_ 403 ADCS8_FCWStatus 3 "Reserved" 2 "Warning level2" 1 "Warning level1" 0 "No request                       ";
VAL_ 403 ADCS8_FCWSystemFaultStatus 3 "Service required" 2 "System temperary unavailable " 1 "Performance degrade" 0 "No error";
VAL_ 403 ADCS8_FCTA_State 1 "On" 0 "Off";
VAL_ 403 ADCS8_FCTALeftActiveSt 3 "Reserved" 2 "Level 2" 1 "Level 1" 0 "No Warning";
VAL_ 403 ADCS8_FCTARightActiveSt 3 "Reserved" 2 "Level 2" 1 "Level 1" 0 "No Warning";
VAL_ 403 ADCS8_FCTAWarnObjType 3 "Reserved" 2 "Unknown" 1 "Vehicle" 0 "No Object                       ";
VAL_ 403 ADCS8_FCTA_SystemFaultStatus 3 "Service required" 2 "System temperary unavailable " 1 "Performance degrade" 0 "No error";
VAL_ 403 ADCS8_RCTA_State 1 "On" 0 "Off";
VAL_ 403 ADCS8_RCTALeftWarnSt 3 "Reserved" 2 "Level 2" 1 "Level 1" 0 "No Warning";
VAL_ 403 ADCS8_RCTARightWarnSt 3 "Reserved" 2 "Level 2" 1 "Level 1" 0 "No Warning";
VAL_ 403 ADCS8_RCTA_SystemFaultStatus 3 "Service required" 2 "System temperary unavailable " 1 "Performance degrade" 0 "No error";
VAL_ 403 ADCS8_RCW_State 1 "On" 0 "Off";
VAL_ 403 ADCS8_RCW_WarnState 3 "Reserved" 2 "Level 2" 1 "Level 1" 0 "No Warning";
VAL_ 403 ADCS8_RCW_SystemFaultStatus 3 "Service required" 2 "System temperary unavailable " 1 "Performance degrade" 0 "No error";
VAL_ 403 ADCS8_DOWState 1 "On" 0 "Off";
VAL_ 403 ADCS8_DOWLeftWarnState 3 "Level 3" 2 "Level 2" 1 "Level 1" 0 "No Warning";
VAL_ 403 ADCS8_DOWRightWarnState 3 "Level 3" 2 "Level 2" 1 "Level 1" 0 "No Warning";
VAL_ 403 ADCS8_DOW_SystemFaultStatus 3 "Service required" 2 "System temperary unavailable " 1 "Performance degrade" 0 "No error";
VAL_ 403 ADCS8_ADAS_IHBCStat 1 "On" 0 "Off";
VAL_ 403 ADCS8_LCAState 1 "On" 0 "Off";
VAL_ 403 ADCS8_HornReq 1 "Request" 0 "No Request";
VAL_ 403 ADCS8_DoorUnlock 1 " Requested" 0 " No Request";
VAL_ 403 ADCS8_LCARightWarnSt 3 "Reserved" 2 "LV2 Warning(LCA)" 1 "LV1 Warning(BSD)" 0 "No warning";
VAL_ 403 ADCS8_LCALeftWarnSt 3 "Reserved" 2 "LV2 Warning(LCA)" 1 "LV1 Warning(BSD)" 0 "No warning";
VAL_ 403 ADCS8_ACCOnOffState 1 "On" 0 "Off";
VAL_ 403 ADCS8_LCASystemFaultStatus 3 "Service required" 2 "System temperary unavailable " 1 "Performance degrade" 0 "No error";
VAL_ 403 ADCS8_TSRState 1 "On" 0 "Off";
VAL_ 403 ADCS8_TSR_SpeedSign 15 "限速120km/h" 14 "限速110km/h" 13 "限速100km/h" 12 "限速90km/h" 11 "限速80km/h" 10 "限速70km/h" 9 "限速60km/h" 8 "限速50km/h" 7 "限速40km/h" 6 "限速35km/h" 5 "限速30km/h" 4 "限速20km/h" 3 "限速15km/h" 2 "限速10km/h" 1 "限速5km/h" 0 "No traffic limit speed";
VAL_ 403 ADCS8_TSR_SpeedWarnState 1 "Warning" 0 "No Warning";
VAL_ 403 ADCS8_TSR_SLFStatefeedback 1 "On" 0 "Off";
VAL_ 403 ADCS8_NNP_SOAAudioplay 1 "SOA Audiobroadcast" 0 "None";
VAL_ 403 ADCS8_TSR_ForbiddenSign 15 " reserved" 9 " reserved" 8 "No passing（禁止通行）" 7 "No turning back（禁止掉头）" 6 "No entry（禁止驶入）" 5 "No parking（禁止停车）" 4 "No turning（禁止转弯）" 3 "No straight（禁止直行）" 2 "No turning right（禁止右转）" 1 "No turning left（禁止左转）" 0 "No sign";
VAL_ 403 ADCS8_PA_FPAS_SnsrObjWrnngZn_RSDW 4 "Zone4" 3 "Zone3" 2 "Zone2" 1 "Zone1" 0 "No Object";
VAL_ 403 ADCS8_PA_FPAS_SnsrObjWrnngZn_LSDW 4 "Zone4" 3 "Zone3" 2 "Zone2" 1 "Zone1" 0 "No Object";
VAL_ 403 ADCS8_PA_FPAS_SnsrObjWrnnglc_RSDW 3 "Air3" 2 "Air2" 1 "Air1" 0 "Norequst";
VAL_ 403 ADCS8_PA_FPAS_SnsrObjWrnnglc_LSDW 3 "Air3" 2 "Air2" 1 "Air1" 0 "Norequst";
VAL_ 403 ADCS8_TSR_LeftLightColor 3 "Green" 2 "Yellow" 1 "Red" 0 "No signal";
VAL_ 403 ADCS8_TSR_RightLightColor 3 "Green" 2 "Yellow" 1 "Red" 0 "No signal";
VAL_ 403 ADCS8_TSR_StrLightColor 3 "Green" 2 "Yellow" 1 "Red" 0 "No signal";
VAL_ 403 ADCS8_TSR_SystemFaultStatus 3 "Service required" 2 "System temperary unavailable " 1 "Performance degrade" 0 "No error";
VAL_ 403 ADCS8_NPilot_SysState 5 " passive" 4 "Fault" 3 "suspend" 2 "Active" 1 "Standby" 0 "OFF";
VAL_ 403 ADCS8_NPilot_SystemFaultStatus 3 "Service Required" 2 "System Temporary Unvailable" 1 "Performance Degradation" 0 "No Error";
VAL_ 403 ADCS8_VoiceNotifFrequency_mode 2 "Detailed" 1 "Simple   " 0 "Basic";
VAL_ 403 ADCS8_NNPSysState 6 "Fault" 5 "Pilot" 4 "Suspend" 3 "TO_transition" 2 "Active" 1 "standby" 0 "Off and not avaliable and Passive";
VAL_ 403 ADCS8_NNP_SystemFaultStatus 3 "Service Required" 2 "System Temporary Unvailable" 1 "Performance Degradation" 0 "No Error";
VAL_ 403 ADCS8_NNP_AutoOnOffSet 1 "On" 0 "Off";
VAL_ 403 ADCS8_DCLCSysState 1 "On" 0 "Off";
VAL_ 403 ADCS8_Lanechangeinfor 6 "Lane change ongoing" 5 "Lane change pending" 4 "Lane change cancel" 3 "Lane change end" 2 "Lane change start" 1 "Vehicle Speed too low " 0 "None";
VAL_ 403 ADCS8_LaneChangeWarning 3 "Reserved" 2 "Right Warning" 1 "Left Warning" 0 "No Warning";
VAL_ 403 ADCS8_LaneChangeSystemFaultStatus 3 "Service Required" 2 "System Temporary Unvailable" 1 "Performance Degradation" 0 "No Error";
VAL_ 403 ADCS8_GMState 2 "Standby" 1 "On" 0 "Off";
VAL_ 403 ADCS8_GMWarnState 3 "Level 2 Warning" 2 "Approach Warning" 1 "Vibration Warning" 0 "No Warning";
VAL_ 403 ADCS8_GMWorkState 5 "   fail" 4 "disable" 3 "active" 2 "   passive" 1 "   standby" 0 "NO action";
VAL_ 403 ADCS8_ADAS_DriveOffPossilbe 1 "Requested" 0 "No Request";
VAL_ 403 ADCS8_DriveOffinhibitionObjType 4 "Unknown" 3 "Cyelist" 2 "Vehicle" 1 "Pedestrian" 0 "No Object                       ";
VAL_ 403 ADCS8_FRS_Fail 2 "Radar Fault" 1 "Radar Blocked" 0 "Radar is Working";
VAL_ 403 ADCS8_SRR_FL_Fail 2 "Radar Fault" 1 "Radar Blocked" 0 "Radar is Working";
VAL_ 403 ADCS8_SRR_FR_Fail 2 "Radar Fault" 1 "Radar Blocked" 0 "Radar is Working";
VAL_ 403 ADCS8_SRR_RL_Fail 2 "Radar Fault" 1 "Radar Blocked" 0 "Radar is Working";
VAL_ 403 ADCS8_SRR_RR_Fail 2 "Radar Fault" 1 "Radar Blocked" 0 "Radar is Working";
VAL_ 403 ADCS8_FVC_120_Fail 2 " Sensor Fault" 1 " Blocked" 0 " Normal";
VAL_ 403 ADCS8_FVC_30_Fail 2 " Sensor Fault" 1 " Blocked" 0 " Normal";
VAL_ 403 ADCS8_SVC_FL_Fail 2 " Sensor Fault" 1 " Blocked" 0 " Normal";
VAL_ 403 ADCS8_SVC_FR_Fail 2 " Sensor Fault" 1 " Blocked" 0 " Normal";
VAL_ 403 ADCS8_SVC_RL_Fail 2 " Sensor Fault" 1 " Blocked" 0 " Normal";
VAL_ 403 ADCS8_SVC_RR_Fail 2 " Sensor Fault" 1 " Blocked" 0 " Normal";
VAL_ 403 ADCS8_RVC_Fail 2 " Sensor Fault" 1 " Blocked" 0 " Normal";
VAL_ 403 ADCS8_TSR_OverspeedOnOffSet 1 "On" 0 "Off";
VAL_ 403 ADCS8_Lanechangedirection 2 "right" 1 "left" 0 "None";
VAL_ 403 ADCS8_VoiceMode 1 " More tips" 0 " Simple";
VAL_ 403 ADCS8_ALC_mode 1 " Automated LC" 0 " Voice allowed LC + Lever allowed LC ";
VAL_ 403 ADCS8_NNP_State 1 "ON（开启）" 0 "OFF（关闭）";
VAL_ 403 ADCS8_ADSDriving_mode 3 " Radical" 2 " Normal" 1 " Basic";
VAL_ 403 ADCS8_NNP_MRM_status 4 "Stand&Warning" 3 "Finshied" 2 "MRM Ongoing" 1 "EM Ongoing" 0 "No";
VAL_ 403 ADCS8_GM_SystemFaultStatus 3 "Service Required;" 2 "System Temporary Unvailable;" 1 "Performance Degradation;" 0 "No Error;";
VAL_ 403 ADCS8_SystemFault 3 " reserved" 2 " Service Required" 1 " System temporary Unavaliable" 0 " System Normal";
VAL_ 403 ADCS8_LeftLidarFault 2 " Sensor Fault" 1 " Blocked" 0 " Normal";
VAL_ 403 ADCS8_RightlidarFault 2 " Sensor Fault" 1 " Blocked" 0 " Normal";
VAL_ 403 ADCS8_AVMFrontCAMFault 2 " Sensor Fault" 1 " Blocked" 0 " Normal";
VAL_ 403 ADCS8_AVMLeftCAMFault 2 " Sensor Fault" 1 " Blocked" 0 " Normal";
VAL_ 403 ADCS8_AVMRightCAMFault 2 " Sensor Fault" 1 " Blocked" 0 " Normal";
VAL_ 403 ADCS8_AVMRearCAMFault 2 " Sensor Fault" 1 " Blocked" 0 " Normal";
VAL_ 404 ADCS8_RPA_CheckListDispReq1 1 "Doors are all closed" 0 "Not Satisfied";
VAL_ 404 ADCS8_RPA_CheckListDispReq2 1 "Vehicle is stanstill" 0 "Not Satisfied";
VAL_ 404 ADCS8_RPA_CheckListDispReq3 1 "Gear Conditions are satisfied" 0 "Not Satisfied";
VAL_ 404 ADCS8_RPA_CheckListDispReq4 1 "EPB is satisfied" 0 "Not Satisfied";
VAL_ 404 ADCS8_RPA_CheckListDispReq5 1 "Tire Pressure is satisfied" 0 "Not Satisfied";
VAL_ 404 ADCS8_RPA_CheckListDispReq6 1 "Slope is satisfied" 0 "Not Satisfied";
VAL_ 404 ADCS8_PA_warninginfo 255 " Reserved" 58 " Reserved" 57 " 请踩住刹车再选择车位" 56 "请在60s内连接蓝牙  " 55 "车位搜索超时，功能中止，3s后退出  " 54 "记忆泊?已暂停，请在30s内返回??继续泊?（手机）" 53 "导航地图不可用（手机）,功能无法开启" 52 "与车辆距离过远（手机）,功能无法开启" 51 "GPS或手机信号异常（手机）,功能无法开" 50 "GPS或手机信号异常，功能终止，请前往处理" 49 "非封闭园区（手机）,功能无法开启" 48 "非停车场区域，功能无法开启" 47 "环境异常，功能终止，3S后退出（车端）/请前往处理（手机）" 46 "道路信息无法满足路线学习要求，记忆泊车已退出，已学习路线将删除（弹窗）" 45 "车辆掉头，记忆泊车已退出，已学习路线将删除（弹窗）" 44 "车辆受阻，功能终止，3S后退出（车端）/请前往处理（手机）" 43 "发生碰撞，功能终止，3S后退出（车端）/请前往处理（手机）" 42 "地图创建失败，功能终止，3S后退出（车端）/请前往处理（手机）" 41 "移动网络通讯差，功能终止，3S后退出（车端）/请前往处理（手机）" 40 "初始化定位失败，功能终止，3S后退出（车端）/请前往处理（手机）" 39 "路线学习失败，记忆泊车已退出，已学习路线将删除(弹窗）" 38 "系统错误，记忆泊车已退出，已学习路线将删除(弹窗）" 37 "泊车失败，记忆泊车已退出，已学习路线将删除(弹窗）" 36 "位置信息丢失，记忆泊车已退出，已学习路线将删除(弹窗）" 35 "跨层受限，记忆泊车已退出，已学习路线将删除(弹窗）" 34 "环境异常，记忆泊车已退出，已学习路线将删除(弹窗）" 33 "挂入R档，记忆泊车已退出，已学习路线将删除(弹窗）" 32 "已超过最大学习里程，记忆泊车已退出，已学习路线将删除(弹窗）" 31 "机舱盖打开，记忆泊车已退出，已学习路线将删除(弹窗）" 30 "行李箱打开，记忆泊车已退出，已学习路线将删除(弹窗）" 29 "车门打开，记忆泊车已退出，已学习路线将删除(弹窗）" 28 "胎压报警，功能终止，3S后退出（车端）/请前往处理（手机）" 27 "功能终止，系统3S后退出（车端）/请前往处理（手机）" 26 "遥控泊车按键松开，泊车暂停" 25 "蓝牙连接故障，请连接蓝牙后重试" 24 "后视镜被折叠，功能终止，3S后退出（车端）/请前往处理（手机）" 23 "泊车空间不足，功能终止，3S后退出（车端）/请前往处理（手机" 22 "电量不足，功能终止，3S后退出（车端）/请前往处理（手机）" 21 "雨量过大，功能终止，3S后退出（车端）/请前往处理（手机）" 20 "坡度过大，功能终止，3S后退出（车端）/请前往处理（手机）" 19 "NNP功能激活，功能终止，3S后退出（车端）/请前往处理（手机）ADAS车控功能已开启，功能终止，3S后退出（车端）/请前往处理（手机）" 18 "驾驶员干预，功能终止，3S后退出（车端）/请前往处理（手机）" 17 "泊车超步，功能终止，3S后退出（车端）/请前往处理（手机）" 16 "泊车超时，功能终止，3S后退出（车端）/请前往处理（手机）" 15 "泊车超速，功能终止，3S后退出（车端）/请前往处理（手机）" 14 "泊车系统故障，功能终止，3S后退出（车端）/请前往处理（手机）" 13 "关联系统故障，功能终止，3S后退出（车端）/请前往处理（手机）" 12 "中断时间超时，功能终止，3S后退出（车端）/请前往处理（手机）" 11 "中断次数超限，功能终止，3S后退出（车端）/请前往处理（手机）" 10 "轨迹内有障碍物，请处理后重试" 9 "系统检测到刹车，功能中断，松开刹车后，泊车继续" 8 "安全带未系，请系上安全带后重试" 7 "机舱盖开启，请关闭后重试" 6 "行李箱门开启，请关闭后重试" 5 "车门被打开，请关闭后重试" 4 "请系好安全带" 3 "请关闭机舱盖开启" 2 "请关闭行李箱门" 1 "请关闭车门" 0 "Normal ";
VAL_ 404 ADCS8_RPA_CheckListDispReq7 1 "System is normal" 0 "Not Satisfied";
VAL_ 404 ADCS8_RPA_CheckListDispReq8 1 "System is normal" 0 "Not Satisfied";
VAL_ 404 ADCS8_PA_FPAS_SnsrObjWrnngZn_FLC 4 "Zone4" 3 "Zone3" 2 "Zone2" 1 "Zone1" 0 "No Object";
VAL_ 404 ADCS8_PA_FPAS_SnsrObjWrnngZn_FLM 4 "Zone4" 3 "Zone3" 2 "Zone2" 1 "Zone1" 0 "No Object";
VAL_ 404 ADCS8_PA_FPAS_SnsrObjWrnngZn_FRM 4 "Zone4" 3 "Zone3" 2 "Zone2" 1 "Zone1" 0 "No Object";
VAL_ 404 ADCS8_PA_FPAS_SnsrObjWrnngZn_FRC 4 "Zone4" 3 "Zone3" 2 "Zone2" 1 "Zone1" 0 "No Object";
VAL_ 404 ADCS8_PA_FPAS_SnsrObjWrnngZn_RLC 4 "Zone4" 3 "Zone3" 2 "Zone2" 1 "Zone1" 0 "No Object";
VAL_ 404 ADCS8_PA_FPAS_SnsrObjWrnngZn_RLM 4 "Zone4" 3 "Zone3" 2 "Zone2" 1 "Zone1" 0 "No Object";
VAL_ 404 ADCS8_PA_FPAS_SnsrObjWrnngZn_RRM 4 "Zone4" 3 "Zone3" 2 "Zone2" 1 "Zone1" 0 "No Object";
VAL_ 404 ADCS8_PA_FPAS_SnsrObjWrnngZn_RRC 4 "Zone4" 3 "Zone3" 2 "Zone2" 1 "Zone1" 0 "No Object";
VAL_ 404 ADCS8_PA_FPAS_SnsrObjWrnngZn_SFL 4 "Zone4" 3 "Zone3" 2 "Zone2" 1 "Zone1" 0 "No Object";
VAL_ 404 ADCS8_PA_FPAS_SnsrObjWrnngZn_SFR 4 "Zone4" 3 "Zone3" 2 "Zone2" 1 "Zone1" 0 "No Object";
VAL_ 404 ADCS8_PA_FPAS_SnsrObjWrnngZn_SRL 4 "Zone4" 3 "Zone3" 2 "Zone2" 1 "Zone1" 0 "No Object";
VAL_ 404 ADCS8_PA_FPAS_SnsrObjWrnngZn_SRR 4 "Zone4" 3 "Zone3" 2 "Zone2" 1 "Zone1" 0 "No Object";
VAL_ 404 ADCS8_PA_FPAS_SnsrDist_FLC 255 "Invalid";
VAL_ 404 ADCS8_PA_FPAS_SnsrDist_FLM 255 "Invalid";
VAL_ 404 ADCS8_PA_FPAS_SnsrDist_FRM 255 "Invalid";
VAL_ 404 ADCS8_PA_FPAS_SnsrDist_FRC 255 "Invalid";
VAL_ 404 ADCS8_PA_FPAS_SnsrDist_RLC 255 "Invalid";
VAL_ 404 ADCS8_PA_FPAS_SnsrDist_RLM 255 "Invalid";
VAL_ 404 ADCS8_PA_FPAS_SnsrDist_RRM 255 "Invalid";
VAL_ 404 ADCS8_PA_FPAS_SnsrDist_RRC 255 "Invalid";
VAL_ 404 ADCS8_PA_FPAS_SnsrDist_SFL 511 "Invalid";
VAL_ 404 ADCS8_PA_FPAS_SnsrDist_SFR 511 "Invalid";
VAL_ 404 ADCS8_PA_FPAS_SnsrDist_SRL 511 "Invalid";
VAL_ 404 ADCS8_PA_FPAS_SnsrDist_SRR 511 "Invalid";
VAL_ 404 ADCS8_PA_FPAS_WorkSts 3 "Failed" 2 "Active" 1 "Standby" 0 "Disabled";
VAL_ 404 ADCS8_PA_RPAS_WorkSts 3 "Failed" 2 "Active" 1 "Standby" 0 "Disabled";
VAL_ 404 ADCS8_PA_FPAS_SensorFaultStsFLC 1 "Sensor fault" 0 "Sensor normal";
VAL_ 404 ADCS8_PA_FPAS_SensorFaultStsFLM 1 "Sensor fault" 0 "Sensor normal";
VAL_ 404 ADCS8_PA_FPAS_SensorFaultStsFRM 1 "Sensor fault" 0 "Sensor normal";
VAL_ 404 ADCS8_PA_FPAS_SensorFaultStsFRC 1 "Sensor fault" 0 "Sensor normal";
VAL_ 404 ADCS8_PA_RPAS_SensorFaultStsRLC 1 "Sensor fault" 0 "Sensor normal";
VAL_ 404 ADCS8_PA_RPAS_SensorFaultStsRLM 1 "Sensor fault" 0 "Sensor normal";
VAL_ 404 ADCS8_PA_RPAS_SensorFaultStsRRM 1 "Sensor fault" 0 "Sensor normal";
VAL_ 404 ADCS8_PA_RPAS_SensorFaultStsRRC 1 "Sensor fault" 0 "Sensor normal";
VAL_ 404 ADCS8_PA_FPAS_SensorFaultStsSFL 1 "Sensor fault" 0 "Sensor normal";
VAL_ 404 ADCS8_PA_FPAS_SensorFaultStsSFR 1 "Sensor fault" 0 "Sensor normal";
VAL_ 404 ADCS8_PA_RPAS_SensorFaultStsSRL 1 "Sensor fault" 0 "Sensor normal";
VAL_ 404 ADCS8_PA_RPAS_SensorFaultStsSRR 1 "Sensor fault" 0 "Sensor normal";
VAL_ 404 ADCS8_AudBpRate_R 6 "Warning Level 4_R" 5 "Warning Level 3_R" 4 "Warning Level 2_R" 3 "Warning Level 1_R" 2 "SyStem fault" 1 "System normal" 0 "No Request";
VAL_ 404 ADCS8_AudBpRate_F 6 "Warning Level 4_F" 5 "Warning Level 3_F" 4 "Warning Level 2_F" 3 "Warning Level 1_F" 2 "SyStem fault" 1 "System normal" 0 "No Request";
VAL_ 404 ADCS8_AVM_RomoteAVMFeedBack 1 "On" 0 "Off";
VAL_ 404 ADCS8_AVM_MODWarning 1 "Warning" 0 "No warning";
VAL_ 402 ADCS7_RPA_ParkingSlotDirection7 2 "Right" 1 "Left" 0 "No";
VAL_ 402 ADCS7_RPA_ParkingSlotType7 3 "Oblique" 2 "Parallel" 1 "Vertical" 0 "undecided";
VAL_ 402 ADCS7_RPA_ParkingSlotDirection8 2 "Right" 1 "Left" 0 "No";
VAL_ 402 ADCS7_RPA_ParkingSlotType8 3 "Oblique" 2 "Parallel" 1 "Vertical" 0 "Undecided";
VAL_ 402 ADCS7_RPA_ObsArea 4 "Right" 3 "Left" 2 "Rear" 1 "Front" 0 "No object";
VAL_ 402 ADCS7_RPA_slot_ID_7_Status 3 "Selected" 2 "Unavailable" 1 "Available" 0 "default";
VAL_ 402 ADCS7_RPA_slot_ID_8_Status 3 "Selected" 2 "Unavailable" 1 "Available" 0 "default";
VAL_ 401 ADCS6_RPA_ParkingSlotDirection4 2 "Right" 1 "Left" 0 "No";
VAL_ 401 ADCS6_RPA_slot_ID_4_Status 3 "Selected" 2 "Unavailable" 1 "Available" 0 "default";
VAL_ 401 ADCS6_RPA_slot_ID_5_Status 3 "Selected" 2 "Unavailable" 1 "Available" 0 "default";
VAL_ 401 ADCS6_RPA_ParkingSlotType4 3 "Oblique" 2 "Parallel" 1 "Vertical" 0 "Undecided";
VAL_ 401 ADCS6_RPA_ParkingSlotDirection5 2 "Right" 1 "Left" 0 "No";
VAL_ 401 ADCS6_RPA_ParkingSlotType5 3 "Oblique" 2 "Parallel" 1 "Vertical" 0 "Undecided";
VAL_ 401 ADCS6_RPA_ParkingSlotDirection6 2 "Right" 1 "Left" 0 "No";
VAL_ 401 ADCS6_RPA_ParkingSlotType6 3 "Oblique" 2 "Parallel" 1 "Vertical" 0 "Undecided";
VAL_ 401 ADCS6_RPA_slot_ID_6_Status 3 "Selected" 2 "Unavailable" 1 "Available" 0 "default";
VAL_ 400 ADCS5_RPA_slot_ID_1_Status 3 "Selected" 2 "Unavailable" 1 "Available" 0 "default";
VAL_ 400 ADCS5_RPA_slot_ID_2_Status 3 "Selected" 2 "Unavailable" 1 "Available" 0 "default";
VAL_ 400 ADCS5_RPA_slot_ID_3_Status 3 "Selected" 2 "Unavailable" 1 "Available" 0 "default";
VAL_ 400 ADCS5_RPA_ParkingSlotDirection1 2 "Right" 1 "Left" 0 "No";
VAL_ 400 ADCS5_RPA_ParkingSlotType1 3 "Oblique" 2 "Parallel" 1 "Vertical" 0 "Undecided";
VAL_ 400 ADCS5_RPA_ParkingSlotDirection2 2 "Right" 1 "Left" 0 "No";
VAL_ 400 ADCS5_RPA_ParkingSlotType2 3 "Oblique" 2 "Parallel" 1 "Vertical" 0 "Undecided";
VAL_ 400 ADCS5_RPA_ParkingSlotDirection3 2 "Right" 1 "Left" 0 "No";
VAL_ 400 ADCS5_RPA_ParkingSlotType3 3 "Oblique" 2 "Parallel" 1 "Vertical" 0 "Undecided";
VAL_ 254 ADCS_AVM_RCW_warningReq 3 "Reserved2" 2 "Reserved1" 1 "Warning" 0 "No warning";
VAL_ 254 ADCS4_AVM_BSD_warningReqLeft 3 "Reserved" 2 "Warning level 2" 1 "Warning level 1" 0 "No warning";
VAL_ 254 ADCS4_AVM_BSD_warningReqRight 3 "Reserved" 2 "Warning level 2" 1 "Warning level 1" 0 "No warning";
VAL_ 254 ADCS4_PA_SysSoundIndication 5 "Reserved" 4 "System disabled or fault" 3 "Ask the driver take off" 2 "park is finished" 1 "Find the park position " 0 "No indication";
VAL_ 254 ADCS4_PA_Sound_Location 7 "Reserved" 6 "Right Rear+Left Rear" 5 "Left Rear" 4 "Right Rear" 3 "Driver Front+Passenger Front" 2 "Driver Front" 1 "Passenger Front" 0 "No warning";
VAL_ 254 ADCS4_AVM_vedioReq 4 " Show calibration" 3 " Show PA" 2 " Show AVM " 1 " Hide" 0 " No Request";
VAL_ 254 ADCS4_AVM_Sts 5 "Fault" 4 "Calibration" 3 "Road Calibration" 2 "Show AVM" 1 "Standby" 0 "off";
VAL_ 254 ADCS4_RPA_RemoteParkFinishReq 2 "Park out finish" 1 "Park in finish" 0 "No request";
VAL_ 254 ADCS4_AVM_BSD_SysSts 6 "Reserved" 5 "System blindness" 4 "System fault" 3 "Trailer mode, all BSD function not available(Reserved)" 2 "Active" 1 "Standby" 0 "Initialization";
VAL_ 254 ADCS4_PA_InfoDisplayReq 9 "Extreme weather" 8 "Abort_external system_Fail" 7 "Abort_VCU_Fail" 6 "Abort_ESP_Fail" 5 "Abort_EPS_Fail" 4 "Abort_APA_ECU_Fail" 3 "APA_Off_Speed too high" 2 "Slope_is_restricted" 1 "Abort_Other_reasons " 0 "OFF";
VAL_ 254 ADCS4_PA_failinfo 15 " reserved" 14 " 请检查车门,后背箱和机舱盖是否关闭" 13 " 当前环境无法开启路线学习" 12 " 蓝牙连接异常，无法使用此功能" 11 " 车辆未挂P档，无法使用此功能" 10 "当前环境，无法使用此功能" 9 "续航能力低，无法使用此功能" 8 "NNP已开启，无法使用此功能" 7 "请保持速度＜30km/h下，使用此功能" 6 "后视镜折叠，功能无法开启" 5 "关联件系统故障，功能无法开启" 4 "请在车辆启动下，使用此功能" 3 "雷达故障，功能无法开启" 2 "系统故障，功能无法开启" 1 "摄像头故障，功能无法开启" 0 "Normal";
VAL_ 254 ADCS4_UPA_Sound_Location 6 "Right Rear+Left Rear" 5 "Left Rear" 4 "Right Rear" 3 "Driver Front+Passenger Front" 2 "Driver Front" 1 "Passenger Front" 0 "No warning";
VAL_ 254 ADCS4_HPA_failinfo 8 "Reserved" 7 "Path error" 6 "Location lost" 5 "Parking error" 4 "Floor limit error" 3 "Distance limit error" 2 "Vehicle speed invalid" 1 "System error" 0 "Normal";
VAL_ 254 ADCS4_UPA_SysSoundIndication 5 "Tone 4 - 1Hz音频 (ICU_AudioAlarmReq 0x4" 4 "Tone 4 - 1Hz音频(ICU_AudioAlarmReq 0x4" 3 "Tone 3 - 2Hz音频(ICU_AudioAlarmReq 0x3" 2 "Tone 2 - 4Hz音频(ICU_AudioAlarmReq 0x2" 1 "Tone 1 - 长鸣(ICU_AudioAlarmReq 0x1" 0 "Tone 0 - No warning(ICU_AudioAlarmReq 0x0";
VAL_ 254 ADCS4_AVM_SysSoundIndication 2 "Over speed" 1 "System disabled or fault" 0 "No indication";
VAL_ 254 ADCS4_PA_ParkBarPercent 11 "100%" 10 "90%" 9 "80%" 8 "70%" 7 "60%" 6 "50%" 5 "40%" 4 "30%" 3 "20%" 2 "10%" 1 "0%" 0 "No request";
VAL_ 254 ADCS4_APA_FunctionMode 4 "Traction" 3 "choice parking in" 2 "Parking out" 1 "Parking in" 0 "No action";
VAL_ 254 ADCS4_Text 49 "前方右转" 48 "记忆泊车工作中" 47 "您的车位已被占用，附近无可用车位，功能即将退出" 46 "您的车位已被占用，附近有可用车位，请选择泊入车位" 45 "你可操作上传或删除，路线删除后，如需使?该地停?场记忆泊?，则需重新学习(弹窗)" 44 "当前起点有重复路线，请选择路线（弹窗）" 43 "重新学习路线，将会覆盖原有的路线，确定要重新学习吗？(弹窗)" 42 "Reserve 您好，路线正在学习中，如退出，已学习路线将删除（弹窗）“" 41 " 已到达您的车位，即将泊入" 40 " 请注意前方车辆" 39 " 请注意行人" 38 " 前方左转/右转" 37 " 识别到障碍物，正在避让" 36 " 前方路口，请注意穿行车辆" 35 "车辆已到达召唤点（手机）" 34 "suspend（见暂停提示）" 33 "长按终点图标重设召唤点" 32 "路径规划中" 31 "拖动或点击地图，选择召唤点" 30 "已到达预约位置，请尽快前往" 29 "记忆泊车成功" 28 "语音播报（不显示文字）" 27 "语音播报2（不显示文字）" 26 "请选择车位" 25 "记忆泊车已就绪，请点击开始" 24 "语音播报1（不显示文字）" 23 "恭喜，路线学习成功（弹窗）" 22 "路线学习已完成，请输入路线名称，结束后会自动保存路线（弹窗）" 21 "倒入车位后，请挂P档" 20 " 请泊入您的车位" 19 " 你好，路线库已满，如需学习路线，需前往路线管理删除路线（弹窗）" 18 " 路线学习已开始，到达您的车位后请倒车入库" 17 " 请控制车辆搜索车位" 16 " 你好，使用远程泊车功能需停好车辆后，挂P档，下车，关好车门，打开手机蓝牙，通过手机App来进行操作。（弹窗）" 15 "请在车辆静止下使用此功能" 14 "请保持车辆静止并点击开始泊车" 13 "请选择合适车位，当前车位不可用" 12 "请调整好目标车位后点击确认" 11 "请保持车辆静止并选择车位类型" 10 "当前方向不可泊出，请重新选择" 9 "请保持车辆静止并选择泊出类型及方向" 8 " 车速过快，记忆泊车已退出，已学习路线将删除(弹窗)" 7 "车速过快，自动泊车已退出" 6 "车速过快，请将车速降低至25km/H以下" 5 "泊车已完成，3S后退出（车端）请前往处理（手机）" 4 "请注意周边环境" 3 " 请松开刹车及方向盘，自动泊车开始" 2 "已找到车位，请踩住刹车，点击开始泊入或OK手势开启泊车，您也可以通过点选或语音切换目标车位" 1 "搜索车位中，请保持低速行驶" 0 "No indication ";
VAL_ 254 ADCS4_ParkingswithReq 1 "Request" 0 "No Request";
VAL_ 254 ADCS4_Slotavaliable 2 "not Avaliable" 1 "Avaliable" 0 "Undecided";
VAL_ 254 ADCS4_locationSt 2 "step2" 1 "step1" 0 "No action";
VAL_ 254 ADCS4_HPA_FunctionMode 1 "Request on" 0 "No request";
VAL_ 254 ADCS4_HPAWarningInfo 2 "此处已有地图，是否重新学习" 1 "地图存储已满" 0 " Default";
VAL_ 254 ADCS4_HPA_deleteMapSt 2 "delcomplete" 1 "deleting" 0 "Noaction";
VAL_ 254 ADCS4_HPA_uploadMapSt 11 "100%" 10 "90%" 9 "80%" 8 "70%" 7 "60%" 6 "50%" 5 "40%" 4 "30%" 3 "20%" 2 "10%" 1 "0%" 0 "No request";
VAL_ 254 ADCS4_NNS_FunctionMode 5 "Inplace" 4 "suspend" 3 "Ready" 2 "Path planing" 1 "NNS" 0 "No action";
VAL_ 254 ADCS4_FindCarAvmStatus 3 "Reserved" 2 "AVM Close" 1 "AVM Open" 0 "No Action";
VAL_ 254 ADCS4_TractionswithReq 1 "Request" 0 "No Request";
VAL_ 254 ADCS4_RPA_FunctionMode 4 "liner ctrl" 3 "choice parking in" 2 "Parking out" 1 "Parking in" 0 "No action";
VAL_ 254 ADCS4_DCWposition 3 "level3" 2 " level2  " 1 "level1   " 0 "off ";
VAL_ 254 ADCS4_DCWlevel 3 "doublewarning" 2 "rightwarning   " 1 " leftwarning    " 0 "   default      ";
